VERSION ""

NS_ :

BS_:

BU_: AHLM ASBS CBC DIAGNOST DPDM DTCM ECM EHPS ESC ESL ESM ETM GPF HCP IC IRCM OCM ORC PTS RF_HUB SCCM SGW TBM TCM TPM

BO_ 1099 VehCfgBu5: 8 RF_HUB
 SG_ VC_BU_AmbLtgPrsnt : 61|1@1+ (1,0) [0|0] ""  CBC,SGW
 SG_ VC_BU_AmbTempLct : 6|2@1+ (1,0) [0|0] ""  CBC,SGW
 SG_ VC_BU_ChildDisp_Prsnt : 59|1@1+ (1,0) [0|0] ""  CBC,SGW
 SG_ VC_BU_LUCI_PRSNT : 2|1@1+ (1,0) [0|0] ""  CBC,SGW
 SG_ VC_BU_NonReg_TPIS : 4|1@1+ (1,0) [0|0] ""  CBC,SGW
 SG_ VC_BU_OffRoadPg : 60|1@1+ (1,0) [0|0] ""  CBC,SGW
 SG_ VC_BU_PPPA_Prsnt : 62|1@1+ (1,0) [0|0] ""  CBC,SGW
 SG_ VC_BU_ParkStopPrsnt : 63|1@1+ (1,0) [0|0] ""  CBC,SGW
 SG_ VC_BU_RR_DuallyPrsnt : 3|1@1+ (1,0) [0|0] ""  CBC,SGW
 SG_ VC_BU_RearDoorLocks2DCM : 56|1@1+ (1,0) [0|0] ""  CBC,SGW
 SG_ VC_BU_SBR_Prsnt : 58|1@1+ (1,0) [0|0] ""  CBC,SGW
 SG_ VC_BU_SpdLmt_PRSNT : 57|1@1+ (1,0) [0|0] ""  CBC,SGW
 SG_ VC_BU_Strng_Rt_0 : 8|8@1+ (0.1,0) [0|25.4] ""  CBC,SGW
 SG_ VC_BU_Strng_Rt_pls1 : 16|8@1+ (0.1,0) [0|25.4] ""  CBC,SGW
 SG_ VC_BU_Strng_Rt_pls2 : 24|8@1+ (0.1,0) [0|25.4] ""  CBC,SGW
 SG_ VC_BU_Strng_Rt_pls3 : 32|8@1+ (0.1,0) [0|25.4] ""  CBC,SGW
 SG_ VC_BU_Strng_Rt_pls4 : 40|8@1+ (0.1,0) [0|25.4] ""  CBC,SGW
 SG_ VC_BU_Strng_Rt_pls5 : 48|8@1+ (0.1,0) [0|25.4] ""  CBC,SGW
 SG_ VC_BU_VehCfg5_Stat : 0|2@1+ (1,0) [0|0] ""  CBC,SGW
 SG_ VC_BU_WTS_Prsnt : 5|1@1+ (1,0) [0|0] ""  CBC,SGW

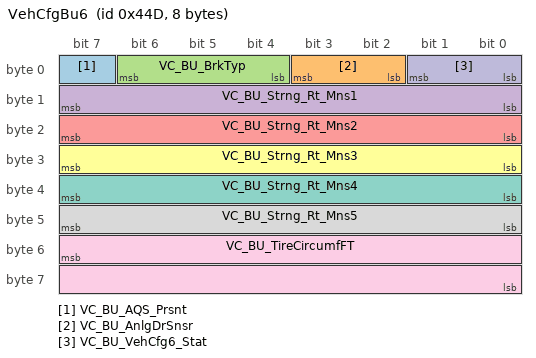
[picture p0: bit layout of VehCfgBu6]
BO_ 1101 VehCfgBu6: 8 RF_HUB
 SG_ VC_BU_AQS_Prsnt : 7|1@1+ (1,0) [0|0] ""  CBC,SGW
 SG_ VC_BU_AnlgDrSnsr : 2|2@1+ (1,0) [0|0] ""  CBC,SGW
 SG_ VC_BU_BrkTyp : 4|3@1+ (1,0) [0|0] ""  CBC,SGW
 SG_ VC_BU_Strng_Rt_Mns1 : 8|8@1+ (0.1,0) [0|25.4] ""  CBC,SGW
 SG_ VC_BU_Strng_Rt_Mns2 : 16|8@1+ (0.1,0) [0|25.4] ""  CBC,SGW
 SG_ VC_BU_Strng_Rt_Mns3 : 24|8@1+ (0.1,0) [0|25.4] ""  CBC,SGW
 SG_ VC_BU_Strng_Rt_Mns4 : 32|8@1+ (0.1,0) [0|25.4] ""  CBC,SGW
 SG_ VC_BU_Strng_Rt_Mns5 : 40|8@1+ (0.1,0) [0|25.4] ""  CBC,SGW
 SG_ VC_BU_TireCircumfFT : 55|16@0+ (1,0) [0|65534] "mm"  CBC,SGW
 SG_ VC_BU_VehCfg6_Stat : 0|2@1+ (1,0) [0|0] ""  CBC,SGW

BO_ 898 VehCfgBu7: 8 RF_HUB
 SG_ VC_BU_ABSM : 25|1@1+ (1,0) [0|0] ""  CBC,SGW
 SG_ VC_BU_ACC_Type : 19|2@1+ (1,0) [0|0] ""  CBC,SGW
 SG_ VC_BU_ADR_PRSNT : 40|1@1+ (1,0) [0|0] ""  CBC,SGW
 SG_ VC_BU_AGSprsnt : 41|1@1+ (1,0) [0|0] ""  CBC,SGW
 SG_ VC_BU_AS_ERS : 14|2@1+ (1,0) [0|0] ""  CBC,SGW
 SG_ VC_BU_AxleLockerPrsnt : 26|2@1+ (1,0) [0|0] ""  CBC,SGW
 SG_ VC_BU_Brake_Type : 56|4@1+ (1,0) [0|0] ""  CBC,SGW
 SG_ VC_BU_DST_Present : 5|1@1+ (1,0) [0|0] ""  CBC,SGW
 SG_ VC_BU_DampingPrsnt : 22|1@1+ (1,0) [0|0] ""  CBC,SGW
 SG_ VC_BU_FullSpeedRange_FCW : 18|1@1+ (1,0) [0|0] ""  CBC,SGW
 SG_ VC_BU_GlareFree_Prsnt : 48|1@1+ (1,0) [0|0] ""  CBC,SGW
 SG_ VC_BU_Glovebox : 44|1@1+ (1,0) [0|0] ""  CBC,SGW
 SG_ VC_BU_HybridType : 36|3@1+ (1,0) [0|0] ""  CBC,SGW
 SG_ VC_BU_LDW : 2|1@1+ (1,0) [0|0] ""  CBC,SGW
 SG_ VC_BU_MOC_Type : 45|2@1+ (1,0) [0|0] ""  CBC,SGW
 SG_ VC_BU_PBTyp : 29|3@1+ (1,0) [0|0] ""  CBC,SGW
 SG_ VC_BU_PTCPrsnt : 43|1@1+ (1,0) [0|0] ""  CBC,SGW
 SG_ VC_BU_PdlsMdPrsnt : 4|1@1+ (1,0) [0|0] ""  CBC,SGW
 SG_ VC_BU_RedKey : 24|1@1+ (1,0) [0|0] ""  CBC,SGW
 SG_ VC_BU_STP_PRSNT : 6|1@1+ (1,0) [0|0] ""  CBC,SGW
 SG_ VC_BU_SUNR_Prsnt : 47|1@1+ (1,0) [0|0] ""  CBC,SGW
 SG_ VC_BU_SVC_Prsnt : 17|1@1+ (1,0) [0|0] ""  CBC,SGW
 SG_ VC_BU_SmartAlternator : 35|1@1+ (1,0) [0|0] ""  CBC,SGW
 SG_ VC_BU_SuspPrsnt : 21|1@1+ (1,0) [0|0] ""  CBC,SGW
 SG_ VC_BU_Suspension_Type : 60|4@1+ (1,0) [0|0] ""  CBC,SGW
 SG_ VC_BU_TPMS_Configuration : 32|3@1+ (1,0) [0|0] ""  CBC,SGW
 SG_ VC_BU_TSBM_Prsnt : 39|1@1+ (1,0) [0|0] ""  CBC,SGW
 SG_ VC_BU_TeenKey : 16|1@1+ (1,0) [0|0] ""  CBC,SGW
 SG_ VC_BU_Temp_Display_Resolution : 42|1@1+ (1,0) [0|0] ""  CBC,SGW
 SG_ VC_BU_TransType : 8|6@1+ (1,0) [0|0] ""  CBC,SGW
 SG_ VC_BU_Trans_Equipped : 28|1@1+ (1,0) [0|0] ""  CBC,SGW
 SG_ VC_BU_Trans_N_Hold_Prsnt : 23|1@1+ (1,0) [0|0] ""  CBC,SGW
 SG_ VC_BU_TrnsDrvMdPrsnt : 3|1@1+ (1,0) [0|0] ""  CBC,SGW
 SG_ VC_BU_VehCfg7_Stat : 0|2@1+ (1,0) [0|0] ""  CBC,SGW
 SG_ VC_BU_eShifter_Prsnt : 7|1@1+ (1,0) [0|0] ""  CBC,SGW

BO_ 907 VehCfgBu8: 8 RF_HUB
 SG_ VC_BU_ARC_PRSNT : 5|1@1+ (1,0) [0|0] ""  CBC,SGW
 SG_ VC_BU_AVAC_PRSNT : 21|1@1+ (1,0) [0|0] ""  CBC,SGW
 SG_ VC_BU_BEAM_SHAPING_PRSNT : 19|1@1+ (1,0) [0|0] ""  CBC,SGW
 SG_ VC_BU_CHILLER_PRSNT : 6|1@1+ (1,0) [0|0] ""  CBC,SGW
 SG_ VC_BU_DBL_PRSNT : 20|1@1+ (1,0) [0|0] ""  CBC,SGW
 SG_ VC_BU_FADPrsnt : 38|1@1+ (1,0) [0|0] ""  CBC,SGW
 SG_ VC_BU_HighOctane_PRSNT : 7|1@1+ (1,0) [0|0] ""  CBC,SGW
 SG_ VC_BU_INDIA_SPEED_WARNING : 41|1@1+ (1,0) [0|0] ""  CBC,SGW
 SG_ VC_BU_Increasing_Speed_Constant : 13|3@1+ (1,0) [0|0] ""  CBC,SGW
 SG_ VC_BU_LineLock_PRSNT : 4|1@1+ (1,0) [0|0] ""  CBC,SGW
 SG_ VC_BU_OFFRoadModePrsnt : 22|1@1+ (1,0) [0|0] ""  CBC,SGW
 SG_ VC_BU_OFFroad_Camera : 23|1@1+ (1,0) [0|0] ""  CBC,SGW
 SG_ VC_BU_OvertakingBan : 16|1@1+ (1,0) [0|0] ""  CBC,SGW
 SG_ VC_BU_PEB_PRSNT : 62|1@1+ (1,0) [0|0] ""  CBC,SGW
 SG_ VC_BU_PPPAHardBtn : 24|1@1+ (1,0) [0|0] ""  CBC,SGW
 SG_ VC_BU_Power_Outlet_Type : 35|2@1+ (1,0) [0|0] ""  CBC,SGW
 SG_ VC_BU_SBL_FBL_CORNERING_PRSNT : 17|2@1+ (1,0) [0|0] ""  CBC,SGW
 SG_ VC_BU_STFA_Prsnt : 53|1@1+ (1,0) [0|0] ""  CBC,SGW
 SG_ VC_BU_Speedometer_Tolerance : 9|4@1+ (1,0) [0|0] ""  CBC,SGW
 SG_ VC_BU_Steering_Cfactor : 2|2@1+ (1,0) [0|0] ""  CBC,SGW
 SG_ VC_BU_TACHO_TYPE : 54|2@1+ (1,0) [0|0] ""  CBC,SGW
 SG_ VC_BU_TIPL_LOT : 39|1@1+ (1,0) [0|0] ""  CBC
 SG_ VC_BU_TLC_PRSNT : 37|1@1+ (1,0) [0|0] ""  CBC,SGW
 SG_ VC_BU_Trans_Brake_PRSNT : 8|1@1+ (1,0) [0|0] ""  CBC,SGW
 SG_ VC_BU_VP_Level : 43|4@1+ (1,0) [0|0] ""  CBC,SGW
 SG_ VC_BU_VehCfg8_Stat : 0|2@1+ (1,0) [0|0] ""  CBC,SGW
 SG_ VC_BU_WHL_BASE_LENGTH : 56|4@1+ (1,0) [0|0] ""  CBC,SGW

BO_ 947 VehCfgCSM1: 8 CBC
 SG_ VC_ACC_DLY_CSO : 24|1@1+ (1,0) [0|0] ""  RF_HUB,SGW
 SG_ VC_AFLS_CSO : 25|1@1+ (1,0) [0|0] ""  RF_HUB,SGW
 SG_ VC_AMB_DMR_CSO : 26|1@1+ (1,0) [0|0] ""  RF_HUB,SGW
 SG_ VC_ASCM_TJ_CSO : 27|1@1+ (1,0) [0|0] ""  RF_HUB,SGW
 SG_ VC_ASCM_WRN_CSO : 28|1@1+ (1,0) [0|0] ""  RF_HUB,SGW
 SG_ VC_AUTO_AERO_CSO : 29|1@1+ (1,0) [0|0] ""  RF_HUB,SGW
 SG_ VC_AUTO_HB_CSO : 30|1@1+ (1,0) [0|0] ""  RF_HUB,SGW
 SG_ VC_AUTO_PRK_CSO : 31|1@1+ (1,0) [0|0] ""  RF_HUB,SGW
 SG_ VC_AUX_SWS_CSO : 18|2@1+ (1,0) [0|0] ""  RF_HUB,SGW
 SG_ VC_BLIND_SPOT_CSO : 32|1@1+ (1,0) [0|0] ""  RF_HUB,SGW
 SG_ VC_CAPACITY_CSO : 33|1@1+ (1,0) [0|0] ""  RF_HUB,SGW
 SG_ VC_CHMSL_LINE_CSO : 15|1@1+ (1,0) [0|0] ""  RF_HUB,SGW
 SG_ VC_CLK_DSP_CSO : 34|1@1+ (1,0) [0|0] ""  RF_HUB,SGW
 SG_ VC_CMP_CAL_CSO : 35|1@1+ (1,0) [0|0] ""  RF_HUB,SGW
 SG_ VC_CMP_VAR_CSO : 36|1@1+ (1,0) [0|0] ""  RF_HUB,SGW
 SG_ VC_CMRA_GRDLNS_CSO : 20|2@1+ (1,0) [0|0] ""  RF_HUB,SGW
 SG_ VC_CONS_CSO : 37|1@1+ (1,0) [0|0] ""  RF_HUB,SGW
 SG_ VC_DCS_CSO : 16|2@1+ (1,0) [0|0] ""  RF_HUB,SGW
 SG_ VC_DISTANCE_CSO : 38|1@1+ (1,0) [0|0] ""  RF_HUB,SGW
 SG_ VC_DRL_CSO : 41|1@1+ (1,0) [0|0] ""  RF_HUB,SGW
 SG_ VC_DR_LK_CSO : 39|1@1+ (1,0) [0|0] ""  RF_HUB,SGW
 SG_ VC_DR_UNLK_CSO : 40|1@1+ (1,0) [0|0] ""  RF_HUB,SGW
 SG_ VC_EASY_EXIT_CSO : 42|1@1+ (1,0) [0|0] ""  RF_HUB,SGW
 SG_ VC_ENTRY_EXIT_CSO : 43|1@1+ (1,0) [0|0] ""  RF_HUB,SGW
 SG_ VC_EPB_SERV_CSO : 44|1@1+ (1,0) [0|0] ""  RF_HUB,SGW
 SG_ VC_EPS_CSO : 7|1@1+ (1,0) [0|0] ""  RF_HUB,SGW
 SG_ VC_FCW_BRK_CSO : 10|1@1+ (1,0) [0|0] ""  RF_HUB,SGW
 SG_ VC_FCW_CSO : 8|2@1+ (1,0) [0|0] ""  RF_HUB,SGW
 SG_ VC_FLSH_LMP_LK_CSO : 45|1@1+ (1,0) [0|0] ""  RF_HUB,SGW
 SG_ VC_HL_DRP_CSO : 46|1@1+ (1,0) [0|0] ""  RF_HUB,SGW
 SG_ VC_HL_OFF_DLY_CSO : 47|1@1+ (1,0) [0|0] ""  RF_HUB,SGW
 SG_ VC_HL_WPR_CSO : 48|1@1+ (1,0) [0|0] ""  RF_HUB,SGW
 SG_ VC_HRN_RMT_LK_CSO : 11|2@1+ (1,0) [0|0] ""  RF_HUB,SGW
 SG_ VC_HRN_RMT_LWR_CSO : 14|1@1+ (1,0) [0|0] ""  RF_HUB,SGW
 SG_ VC_HRN_RMT_ST_CSO : 13|1@1+ (1,0) [0|0] ""  RF_HUB,SGW
 SG_ VC_HSA_CSO : 49|1@1+ (1,0) [0|0] ""  RF_HUB,SGW
 SG_ VC_ILL_APPRCH_CSO : 50|1@1+ (1,0) [0|0] ""  RF_HUB,SGW
 SG_ VC_LDW_TRQ_CSO : 51|1@1+ (1,0) [0|0] ""  RF_HUB,SGW
 SG_ VC_LDW_WRN_CSO : 52|1@1+ (1,0) [0|0] ""  RF_HUB,SGW
 SG_ VC_LGHT_RMT_LWR_CSO : 53|1@1+ (1,0) [0|0] ""  RF_HUB,SGW
 SG_ VC_NAV_TRN_CSO : 54|1@1+ (1,0) [0|0] ""  RF_HUB,SGW
 SG_ VC_PER_SHFT_ENBL_CSO : 56|1@1+ (1,0) [0|0] ""  RF_HUB,SGW
 SG_ VC_PER_SHFT_RPM_CSO : 57|1@1+ (1,0) [0|0] ""  RF_HUB,SGW
 SG_ VC_PE_CSO : 55|1@1+ (1,0) [0|0] ""  RF_HUB,SGW
 SG_ VC_PLG_CHM_CSO : 58|1@1+ (1,0) [0|0] ""  RF_HUB,SGW
 SG_ VC_POLICE_PE_CSO : 23|1@1+ (1,0) [0|0] ""  RF_HUB,SGW
 SG_ VC_POWER_CSO : 59|1@1+ (1,0) [0|0] ""  RF_HUB,SGW
 SG_ VC_PRESSURE_CSO : 60|1@1+ (1,0) [0|0] ""  RF_HUB,SGW
 SG_ VC_PRK_AST_BRK_CSO : 4|1@1+ (1,0) [0|0] ""  RF_HUB,SGW
 SG_ VC_PRK_AST_CSO : 2|2@1+ (1,0) [0|0] ""  RF_HUB,SGW
 SG_ VC_PRK_FT_VOL_CSO : 5|1@1+ (1,0) [0|0] ""  RF_HUB,SGW
 SG_ VC_PRK_RR_VOL_CSO : 6|1@1+ (1,0) [0|0] ""  RF_HUB,SGW
 SG_ VC_PTO_CSO : 61|1@1+ (1,0) [0|0] ""  RF_HUB,SGW
 SG_ VC_RAIN_WPR_CSO : 62|1@1+ (1,0) [0|0] ""  RF_HUB,SGW
 SG_ VC_REAR_CMRA_CSO : 63|1@1+ (1,0) [0|0] ""  RF_HUB,SGW
 SG_ VC_UNIT_SET_CSO : 22|1@1+ (1,0) [0|0] ""  RF_HUB,SGW
 SG_ VC_VehCfgCSO1_Stat : 0|2@1+ (1,0) [0|0] ""  IC,RF_HUB,SGW

BO_ 949 VehCfgCSM1_BU: 8 RF_HUB
 SG_ VC_BU_ACC_DLY_CSO : 24|1@1+ (1,0) [0|0] ""  CBC,SGW
 SG_ VC_BU_AFLS_CSO : 25|1@1+ (1,0) [0|0] ""  CBC,SGW
 SG_ VC_BU_AMB_DMR_CSO : 26|1@1+ (1,0) [0|0] ""  CBC,SGW
 SG_ VC_BU_ASCM_TJ_CSO : 27|1@1+ (1,0) [0|0] ""  CBC,SGW
 SG_ VC_BU_ASCM_WRN_CSO : 28|1@1+ (1,0) [0|0] ""  CBC,SGW
 SG_ VC_BU_AUTO_AERO_CSO : 29|1@1+ (1,0) [0|0] ""  CBC,SGW
 SG_ VC_BU_AUTO_HB_CSO : 30|1@1+ (1,0) [0|0] ""  CBC,SGW
 SG_ VC_BU_AUTO_PRK_CSO : 31|1@1+ (1,0) [0|0] ""  CBC,SGW
 SG_ VC_BU_AUX_SWS_CSO : 18|2@1+ (1,0) [0|0] ""  CBC,SGW
 SG_ VC_BU_BLIND_SPOT_CSO : 32|1@1+ (1,0) [0|0] ""  CBC,SGW
 SG_ VC_BU_CAPACITY_CSO : 33|1@1+ (1,0) [0|0] ""  CBC,SGW
 SG_ VC_BU_CHMSL_LINE_CSO : 15|1@1+ (1,0) [0|0] ""  CBC,SGW
 SG_ VC_BU_CLK_DSP_CSO : 34|1@1+ (1,0) [0|0] ""  CBC,SGW
 SG_ VC_BU_CMP_CAL_CSO : 35|1@1+ (1,0) [0|0] ""  CBC,SGW
 SG_ VC_BU_CMP_VAR_CSO : 36|1@1+ (1,0) [0|0] ""  CBC,SGW
 SG_ VC_BU_CMRA_GRDLNS_CSO : 20|2@1+ (1,0) [0|0] ""  CBC,SGW
 SG_ VC_BU_CONS_CSO : 37|1@1+ (1,0) [0|0] ""  CBC,SGW
 SG_ VC_BU_DCS_CSO : 16|2@1+ (1,0) [0|0] ""  CBC,SGW
 SG_ VC_BU_DISTANCE_CSO : 38|1@1+ (1,0) [0|0] ""  CBC,SGW
 SG_ VC_BU_DRL_CSO : 41|1@1+ (1,0) [0|0] ""  CBC,SGW
 SG_ VC_BU_DR_LK_CSO : 39|1@1+ (1,0) [0|0] ""  CBC,SGW
 SG_ VC_BU_DR_UNLK_CSO : 40|1@1+ (1,0) [0|0] ""  CBC,SGW
 SG_ VC_BU_EASY_EXIT_CSO : 42|1@1+ (1,0) [0|0] ""  CBC,SGW
 SG_ VC_BU_ENTRY_EXIT_CSO : 43|1@1+ (1,0) [0|0] ""  CBC,SGW
 SG_ VC_BU_EPB_SERV_CSO : 44|1@1+ (1,0) [0|0] ""  CBC,SGW
 SG_ VC_BU_EPS_CSO : 7|1@1+ (1,0) [0|0] ""  CBC,SGW
 SG_ VC_BU_FCW_BRK_CSO : 10|1@1+ (1,0) [0|0] ""  CBC,SGW
 SG_ VC_BU_FCW_CSO : 8|2@1+ (1,0) [0|0] ""  CBC,SGW
 SG_ VC_BU_FLSH_LMP_LK_CSO : 45|1@1+ (1,0) [0|0] ""  CBC,SGW
 SG_ VC_BU_HL_DRP_CSO : 46|1@1+ (1,0) [0|0] ""  CBC,SGW
 SG_ VC_BU_HL_OFF_DLY_CSO : 47|1@1+ (1,0) [0|0] ""  CBC,SGW
 SG_ VC_BU_HL_WPR_CSO : 48|1@1+ (1,0) [0|0] ""  CBC,SGW
 SG_ VC_BU_HRN_RMT_LK_CSO : 11|2@1+ (1,0) [0|0] ""  CBC,SGW
 SG_ VC_BU_HRN_RMT_LWR_CSO : 14|1@1+ (1,0) [0|0] ""  CBC,SGW
 SG_ VC_BU_HRN_RMT_ST_CSO : 13|1@1+ (1,0) [0|0] ""  CBC,SGW
 SG_ VC_BU_HSA_CSO : 49|1@1+ (1,0) [0|0] ""  CBC,SGW
 SG_ VC_BU_ILL_APPRCH_CSO : 50|1@1+ (1,0) [0|0] ""  CBC,SGW
 SG_ VC_BU_LDW_TRQ_CSO : 51|1@1+ (1,0) [0|0] ""  CBC,SGW
 SG_ VC_BU_LDW_WRN_CSO : 52|1@1+ (1,0) [0|0] ""  CBC,SGW
 SG_ VC_BU_LGHT_RMT_LWR_CSO : 53|1@1+ (1,0) [0|0] ""  CBC,SGW
 SG_ VC_BU_NAV_TRN_CSO : 54|1@1+ (1,0) [0|0] ""  CBC,SGW
 SG_ VC_BU_PER_SHFT_ENBL_CSO : 56|1@1+ (1,0) [0|0] ""  CBC,SGW
 SG_ VC_BU_PER_SHFT_RPM_CSO : 57|1@1+ (1,0) [0|0] ""  CBC,SGW
 SG_ VC_BU_PE_CSO : 55|1@1+ (1,0) [0|0] ""  CBC,SGW
 SG_ VC_BU_PLG_CHM_CSO : 58|1@1+ (1,0) [0|0] ""  CBC,SGW
 SG_ VC_BU_POLICE_PE_CSO : 23|1@1+ (1,0) [0|0] ""  CBC,SGW
 SG_ VC_BU_POWER_CSO : 59|1@1+ (1,0) [0|0] ""  CBC,SGW
 SG_ VC_BU_PRESSURE_CSO : 60|1@1+ (1,0) [0|0] ""  CBC,SGW
 SG_ VC_BU_PRK_AST_BRK_CSO : 4|1@1+ (1,0) [0|0] ""  CBC,SGW
 SG_ VC_BU_PRK_AST_CSO : 2|2@1+ (1,0) [0|0] ""  CBC,SGW
 SG_ VC_BU_PRK_FT_VOL_CSO : 5|1@1+ (1,0) [0|0] ""  CBC,SGW
 SG_ VC_BU_PRK_RR_VOL_CSO : 6|1@1+ (1,0) [0|0] ""  CBC,SGW
 SG_ VC_BU_PTO_CSO : 61|1@1+ (1,0) [0|0] ""  CBC,SGW
 SG_ VC_BU_RAIN_WPR_CSO : 62|1@1+ (1,0) [0|0] ""  CBC,SGW
 SG_ VC_BU_REAR_CMRA_CSO : 63|1@1+ (1,0) [0|0] ""  CBC,SGW
 SG_ VC_BU_UNIT_SET_CSO : 22|1@1+ (1,0) [0|0] ""  CBC,SGW
 SG_ VC_BU_VehCfgCSO1_Stat : 0|2@1+ (1,0) [0|0] ""  CBC,SGW

CM_ SG_ 1099 VC_BU_AmbLtgPrsnt "Backup for ambient lighting feature is present; True = 1";
CM_ SG_ 1099 VC_BU_AmbTempLct "Backup for ambient temperature sensor location";
CM_ SG_ 1099 VC_BU_ChildDisp_Prsnt "Backup for child display feature is present; True = 1";
CM_ SG_ 1099 VC_BU_LUCI_PRSNT "Backup for Luci feature present; present = [1]";
CM_ SG_ 1099 VC_BU_NonReg_TPIS "Backup for non-regulated tire pressure indicator system; True = 1";
CM_ SG_ 1099 VC_BU_OffRoadPg "Backup for off road pages present; True = [1]";
CM_ SG_ 1099 VC_BU_PPPA_Prsnt "Backup for semi automatic parking system present; True = 1";
CM_ SG_ 1099 VC_BU_ParkStopPrsnt "Backup for park with stop is present; True = 1";
CM_ SG_ 1099 VC_BU_RR_DuallyPrsnt "Backup for vehicle is equipped with rear duals; present = [1]";
CM_ SG_ 1099 VC_BU_RearDoorLocks2DCM "Backup for Rear door lock switch present; present = [1]";
CM_ SG_ 1099 VC_BU_SBR_Prsnt "Backup for seat belt reminder module is present; True = 1";
CM_ SG_ 1099 VC_BU_SpdLmt_PRSNT "Backup for Speed limiter is present; present = [1]";
CM_ SG_ 1099 VC_BU_Strng_Rt_0 "Backup for Steering Ratio at zero";
CM_ SG_ 1099 VC_BU_Strng_Rt_pls1 "Backup for Steering Ratio at positve angle 1";
CM_ SG_ 1099 VC_BU_Strng_Rt_pls2 "Backup for Steering Ratio at positve angle 2";
CM_ SG_ 1099 VC_BU_Strng_Rt_pls3 "Backup for Steering Ratio at positve angle 3";
CM_ SG_ 1099 VC_BU_Strng_Rt_pls4 "Backup for Steering Ratio at positve angle 4";
CM_ SG_ 1099 VC_BU_Strng_Rt_pls5 "Backup for Steering Ratio at positve angle 5";
CM_ SG_ 1099 VC_BU_VehCfg5_Stat "Backup for Configuration messages status 5";
CM_ SG_ 1099 VC_BU_WTS_Prsnt "Backup for wait to start feature is present; present = [1]";
CM_ SG_ 1101 VC_BU_AQS_Prsnt "Backup for air quality sensor present; present = [1]";
CM_ SG_ 1101 VC_BU_AnlgDrSnsr "Analog door sensor configuration backup";
CM_ SG_ 1101 VC_BU_BrkTyp "Backup for brake type configuration (M156/7)";
CM_ SG_ 1101 VC_BU_Strng_Rt_Mns1 "Backup for Steering Ratio at negative angle 1";
CM_ SG_ 1101 VC_BU_Strng_Rt_Mns2 "Backup for Steering Ratio at negative angle 2";
CM_ SG_ 1101 VC_BU_Strng_Rt_Mns3 "Backup for Steering Ratio at negative angle 3";
CM_ SG_ 1101 VC_BU_Strng_Rt_Mns4 "Backup for Steering Ratio at negative angle 4";
CM_ SG_ 1101 VC_BU_Strng_Rt_Mns5 "Backup for Steering Ratio at negative angle 5";
CM_ SG_ 1101 VC_BU_TireCircumfFT "Backup for Dynamic tire circumference - front only";
CM_ SG_ 1101 VC_BU_VehCfg6_Stat "Backup for Configuration messages status 6";
CM_ SG_ 898 VC_BU_ABSM "Backup for Active Blind Spot present; present = [1]";
CM_ SG_ 898 VC_BU_ACC_Type "Backup for type of adaptive cruise control (ACC) system present";
CM_ SG_ 898 VC_BU_ADR_PRSNT "Backup for ADR feature present; True = [1]";
CM_ SG_ 898 VC_BU_AGSprsnt "Backup for AGS present/absent config signal;  Present = 1";
CM_ SG_ 898 VC_BU_AS_ERS "Backup for shift feature autostick / electronic range select status";
CM_ SG_ 898 VC_BU_AxleLockerPrsnt "Backup for axle locker configuration";
CM_ SG_ 898 VC_BU_Brake_Type "Backup for brake type";
CM_ SG_ 898 VC_BU_DST_Present "Backup for dynamic steering torque present; True = [1]";
CM_ SG_ 898 VC_BU_DampingPrsnt "Backup for ASCM contains active damping; present = [1]";
CM_ SG_ 898 VC_BU_FullSpeedRange_FCW "Backup for full speed range forward collision warning plus system present; Present = 1";
CM_ SG_ 898 VC_BU_GlareFree_Prsnt "Glare Free Present";
CM_ SG_ 898 VC_BU_Glovebox "Backup for Glovebox control; Present = 1";
CM_ SG_ 898 VC_BU_HybridType "Backup for identify the kind of hybrid vehicle";
CM_ SG_ 898 VC_BU_LDW "Lane departure warning present; present = [1]";
CM_ SG_ 898 VC_BU_MOC_Type "Backup for motor on caliper type";
CM_ SG_ 898 VC_BU_PBTyp "Backup for park brake type";
CM_ SG_ 898 VC_BU_PTCPrsnt "Backup for PTC present/absent config signal;  Present = 1";
CM_ SG_ 898 VC_BU_PdlsMdPrsnt "Backup for paddles lock-out feature; present = [1]";
CM_ SG_ 898 VC_BU_RedKey "Backup for RedKey feature is present; Present = [1]";
CM_ SG_ 898 VC_BU_STP_PRSNT "Backup for super trac pack present; True = [1]";
CM_ SG_ 898 VC_BU_SUNR_Prsnt "Backup for sunroof is present; True = 1";
CM_ SG_ 898 VC_BU_SVC_Prsnt "Backup for surround view camera; present = [1]";
CM_ SG_ 898 VC_BU_SmartAlternator "Backup for smart alternator is present; True = [1]";
CM_ SG_ 898 VC_BU_SuspPrsnt "backup for ASCM contains suspension; present = [1]";
CM_ SG_ 898 VC_BU_Suspension_Type "Backup for suspension type";
CM_ SG_ 898 VC_BU_TPMS_Configuration "Backup for TPMS configuration";
CM_ SG_ 898 VC_BU_TSBM_Prsnt "Backup for TSBM LIN slave is present; True = [1]";
CM_ SG_ 898 VC_BU_TeenKey "Backup for teenKey feature is present; Present = [1]";
CM_ SG_ 898 VC_BU_Temp_Display_Resolution "Backup for toggle between 0.5degC and 1degC temperature display";
CM_ SG_ 898 VC_BU_TransType "Backup for automatic transmission type";
CM_ SG_ 898 VC_BU_Trans_Equipped "Backup for Transmission equipped: 0 = Automatic & 1 = Manual";
CM_ SG_ 898 VC_BU_Trans_N_Hold_Prsnt "Backup for Transmission neutral hold feature; present = [1]";
CM_ SG_ 898 VC_BU_TrnsDrvMdPrsnt "Backup for transmission drive mode feature; present = [1]";
CM_ SG_ 898 VC_BU_VehCfg7_Stat "Backup for Configuration messages status 7";
CM_ SG_ 898 VC_BU_eShifter_Prsnt "Backup for e-shifter present; present = [1]";
CM_ SG_ 907 VC_BU_ARC_PRSNT "Backup for After Run Cooling (Race Cool Down) feature present; True = [1]";
CM_ SG_ 907 VC_BU_AVAC_PRSNT "Present = 1";
CM_ SG_ 907 VC_BU_BEAM_SHAPING_PRSNT "Present = 1";
CM_ SG_ 907 VC_BU_CHILLER_PRSNT "Backup for Chiller present; True = [1]";
CM_ SG_ 907 VC_BU_DBL_PRSNT "Present = 1";
CM_ SG_ 907 VC_BU_FADPrsnt "Present = 1";
CM_ SG_ 907 VC_BU_HighOctane_PRSNT "Backup for High Octane feature present; True = [1]";
CM_ SG_ 907 VC_BU_INDIA_SPEED_WARNING "Back up for INDIA EQUIPPED SPEED WARNING Feature";
CM_ SG_ 907 VC_BU_Increasing_Speed_Constant "Backup for Increasing Speed Constant (Offset for Speedometer Biasing)";
CM_ SG_ 907 VC_BU_LineLock_PRSNT "Backup for Line Lock feature present; True = [1]";
CM_ SG_ 907 VC_BU_OFFRoadModePrsnt "OFF ROAD MODE Present BackUp Configuration, Present = 1";
CM_ SG_ 907 VC_BU_OFFroad_Camera "OFF Road Camera Present, Present = 1";
CM_ SG_ 907 VC_BU_OvertakingBan "Backup for Overtaking Ban present; present = [1]";
CM_ SG_ 907 VC_BU_PEB_PRSNT "Vehicle config to learn the presence of PEB";
CM_ SG_ 907 VC_BU_PPPAHardBtn "PPPA Hard button present; Present = [1]";
CM_ SG_ 907 VC_BU_Power_Outlet_Type "Bachup signal of VC_Power_Outlet_Type";
CM_ SG_ 907 VC_BU_SBL_FBL_CORNERING_PRSNT "Configuration messages status 8";
CM_ SG_ 907 VC_BU_STFA_Prsnt "Back up for Selectable Tire Fill Alert Present; True = [1]";
CM_ SG_ 907 VC_BU_Speedometer_Tolerance "Backup for Speedometer Tolerance Percentage (Gain for Speedometer Biasing)";
CM_ SG_ 907 VC_BU_Steering_Cfactor "Backup for Steering Cfactor feature";
CM_ SG_ 907 VC_BU_TACHO_TYPE "Backup Vehicle Configuration 8 Packet";
CM_ SG_ 907 VC_BU_TIPL_LOT "Backup for Traffic in Parallel and Lock on Target (1=present)";
CM_ SG_ 907 VC_BU_TLC_PRSNT "Backup for VC_TLC_PRSNT; present = [1]";
CM_ SG_ 907 VC_BU_Trans_Brake_PRSNT "Backup for Transmission Brake feature present; True = [1]";
CM_ SG_ 907 VC_BU_VP_Level "Back up for Radio Type Identifier";
CM_ SG_ 907 VC_BU_VehCfg8_Stat "Backup for Configuration messages status 8";
CM_ SG_ 907 VC_BU_WHL_BASE_LENGTH "Back up Wheel Base Length";
CM_ SG_ 947 VC_ACC_DLY_CSO "Power accessory delay customer settings menu; Present = [1]";
CM_ SG_ 947 VC_AFLS_CSO "Adaptive front light system customer settings menu; Present = [1]";
CM_ SG_ 947 VC_AMB_DMR_CSO "Ambient dimmer customer settings menu; Present = [1]";
CM_ SG_ 947 VC_ASCM_TJ_CSO "Tire jack mode customer settings menu; Present = [1]";
CM_ SG_ 947 VC_ASCM_WRN_CSO "Air suspension warning customer settings menu; Present = [1]";
CM_ SG_ 947 VC_AUTO_AERO_CSO "Automatic aero mode customer settings menu; Present = [1]";
CM_ SG_ 947 VC_AUTO_HB_CSO "Auto high beam customer settings menu; Present = [1]";
CM_ SG_ 947 VC_AUTO_PRK_CSO "Auto park customer settings menu; Present = [1]";
CM_ SG_ 947 VC_AUX_SWS_CSO "Auxiliary switches customer settings menu";
CM_ SG_ 947 VC_BLIND_SPOT_CSO "Blind spot alert customer settings menu; Present = [1]";
CM_ SG_ 947 VC_CAPACITY_CSO "Capacity unit customer settings menu; Present = [1]";
CM_ SG_ 947 VC_CHMSL_LINE_CSO "CHMSL line menu; Present = [1]";
CM_ SG_ 947 VC_CLK_DSP_CSO "Clock display customer settings menu; Present = [1]";
CM_ SG_ 947 VC_CMP_CAL_CSO "Compass calibration customer settings menu; Present = [1]";
CM_ SG_ 947 VC_CMP_VAR_CSO "Compass variance customer settings menu; Present = [1]";
CM_ SG_ 947 VC_CMRA_GRDLNS_CSO "Rear view camera gridlines customer settings menu";
CM_ SG_ 947 VC_CONS_CSO "Consumption unit customer settings menu; Present = [1]";
CM_ SG_ 947 VC_DCS_CSO "Auto on driver comfort customer settings menu";
CM_ SG_ 947 VC_DISTANCE_CSO "Distance unit customer settings menu; Present = [1]";
CM_ SG_ 947 VC_DRL_CSO "Daytime running lights customer settings menu; Present = [1]";
CM_ SG_ 947 VC_DR_LK_CSO "Auto door lock customer settings menu; Present = [1]";
CM_ SG_ 947 VC_DR_UNLK_CSO "Auto door unlock customer settings menu; Present = [1]";
CM_ SG_ 947 VC_EASY_EXIT_CSO "Easy exit seat customer settings menu; Present = [1]";
CM_ SG_ 947 VC_ENTRY_EXIT_CSO "Auto entry exit mode customer settings menu; Present = [1]";
CM_ SG_ 947 VC_EPB_SERV_CSO "EPB service mode customer settings menu; Present = [1]";
CM_ SG_ 947 VC_EPS_CSO "Electric power steering customer settings menu; Present = [1]";
CM_ SG_ 947 VC_FCW_BRK_CSO "Forward collision mitigation braking customer settings menu; Present = [1]";
CM_ SG_ 947 VC_FCW_CSO "Forward collision warning customer settings menu";
CM_ SG_ 947 VC_FLSH_LMP_LK_CSO "Flash lamps with lock customer settings menu; Present = [1]";
CM_ SG_ 947 VC_HL_DRP_CSO "Headlamp drop customer settings menu; Present = [1]";
CM_ SG_ 947 VC_HL_OFF_DLY_CSO "Headlamp off delay customer settings menu; Present = [1]";
CM_ SG_ 947 VC_HL_WPR_CSO "Headlamps on with wiper customer settings menu; Present = [1]";
CM_ SG_ 947 VC_HRN_RMT_LK_CSO "Sound horn with remote lock customer settings menu";
CM_ SG_ 947 VC_HRN_RMT_LWR_CSO "Sound horn with remote lower customer settings menu; Present = [1]";
CM_ SG_ 947 VC_HRN_RMT_ST_CSO "Sound horn with remote start customer settings menu; Present = [1]";
CM_ SG_ 947 VC_HSA_CSO "Hill start assist customer settings menu; Present = [1]";
CM_ SG_ 947 VC_ILL_APPRCH_CSO "Illuminated approach customer settings menu; Present = [1]";
CM_ SG_ 947 VC_LDW_TRQ_CSO "Lane departure torque customer settings menu; Present = [1]";
CM_ SG_ 947 VC_LDW_WRN_CSO "Lane departure warning customer settings menu; Present = [1]";
CM_ SG_ 947 VC_LGHT_RMT_LWR_CSO "Flash lights with remote lower customer settings menu; Present = [1]";
CM_ SG_ 947 VC_NAV_TRN_CSO "Nav turn by turn customer settings menu; Present = [1]";
CM_ SG_ 947 VC_PER_SHFT_ENBL_CSO "Performance shift enable customer settings menu; Present = [1]";
CM_ SG_ 947 VC_PER_SHFT_RPM_CSO "Performance shift rpm customer settings menu; Present = [1]";
CM_ SG_ 947 VC_PE_CSO "Passive entry customer settings menu; Present = [1]";
CM_ SG_ 947 VC_PLG_CHM_CSO "Power liftgate chime customer settings menu; Present = [1]";
CM_ SG_ 947 VC_POLICE_PE_CSO "Police passive entry settings menu; Present = [1]";
CM_ SG_ 947 VC_POWER_CSO "Power unit customer settings menu; Present = [1]";
CM_ SG_ 947 VC_PRESSURE_CSO "Pressure unit customer settings menu; Present = [1]";
CM_ SG_ 947 VC_PRK_AST_BRK_CSO "Park assist brake customer settings menu; Present = [1]";
CM_ SG_ 947 VC_PRK_AST_CSO "Park assist customer settings menu";
CM_ SG_ 947 VC_PRK_FT_VOL_CSO "Park assist front volume customer settings menu; Present = [1]";
CM_ SG_ 947 VC_PRK_RR_VOL_CSO "Park assist rear volume customer settings menu; Present = [1]";
CM_ SG_ 947 VC_PTO_CSO "Power take off customer settings menu; Present = [1]";
CM_ SG_ 947 VC_RAIN_WPR_CSO "Rain sensitive wipers customer settings menu; Present = [1]";
CM_ SG_ 947 VC_REAR_CMRA_CSO "Rear camera customer settings menu; Present = [1]";
CM_ SG_ 947 VC_UNIT_SET_CSO "Unit set customer settings menu; Present = [1]";
CM_ SG_ 947 VC_VehCfgCSO1_Stat "Configuration message CSO1 status";
CM_ SG_ 949 VC_BU_ACC_DLY_CSO "Backup for Power accessory delay customer settings menu";
CM_ SG_ 949 VC_BU_AFLS_CSO "Backup for Adaptive front light system customer settings menu";
CM_ SG_ 949 VC_BU_AMB_DMR_CSO "Backup for Ambient dimmer customer settings menu";
CM_ SG_ 949 VC_BU_ASCM_TJ_CSO "Backup for Tire jack mode customer settings menu";
CM_ SG_ 949 VC_BU_ASCM_WRN_CSO "Backup for Air suspension warning customer settings menu";
CM_ SG_ 949 VC_BU_AUTO_AERO_CSO "Backup for Automatic aero mode customer settings menu";
CM_ SG_ 949 VC_BU_AUTO_HB_CSO "Backup for Auto high beam customer settings menu";
CM_ SG_ 949 VC_BU_AUTO_PRK_CSO "Backup for Auto park customer settings menu";
CM_ SG_ 949 VC_BU_AUX_SWS_CSO "Backup for Auxiliary switches customer settings menu";
CM_ SG_ 949 VC_BU_BLIND_SPOT_CSO "Backup for Blind spot alert customer settings menu";
CM_ SG_ 949 VC_BU_CAPACITY_CSO "Backup for Capacity unit customer settings menu";
CM_ SG_ 949 VC_BU_CHMSL_LINE_CSO "Backup for CHMSL line customer settings menu";
CM_ SG_ 949 VC_BU_CLK_DSP_CSO "Backup for Clock display customer settings menu";
CM_ SG_ 949 VC_BU_CMP_CAL_CSO "Backup for Compass calibration customer settings menu";
CM_ SG_ 949 VC_BU_CMP_VAR_CSO "Backup for Compass variance customer settings menu";
CM_ SG_ 949 VC_BU_CMRA_GRDLNS_CSO "Backup for Rear view camera gridlines customer settings menu";
CM_ SG_ 949 VC_BU_CONS_CSO "Backup for Consumption unit customer settings menu";
CM_ SG_ 949 VC_BU_DCS_CSO "Backup for Auto on driver comfort customer settings menu";
CM_ SG_ 949 VC_BU_DISTANCE_CSO "Backup for Distance unit customer settings menu";
CM_ SG_ 949 VC_BU_DRL_CSO "Backup for Daytime running lights customer settings menu";
CM_ SG_ 949 VC_BU_DR_LK_CSO "Backup for Auto door lock customer settings menu";
CM_ SG_ 949 VC_BU_DR_UNLK_CSO "Backup for Auto door unlock customer settings menu";
CM_ SG_ 949 VC_BU_EASY_EXIT_CSO "Backup for Easy exit seat customer settings menu";
CM_ SG_ 949 VC_BU_ENTRY_EXIT_CSO "Backup for Auto entry exit mode customer settings menu";
CM_ SG_ 949 VC_BU_EPB_SERV_CSO "Backup for EPB service mode customer settings menu";
CM_ SG_ 949 VC_BU_EPS_CSO "Backup for electric power steering customer settings menu";
CM_ SG_ 949 VC_BU_FCW_BRK_CSO "Backup for Forward collision mitigation braking customer settings menu";
CM_ SG_ 949 VC_BU_FCW_CSO "Backup for Forward collision warning customer settings menu";
CM_ SG_ 949 VC_BU_FLSH_LMP_LK_CSO "Backup for Flash lamps with lock customer settings menu";
CM_ SG_ 949 VC_BU_HL_DRP_CSO "Backup for Headlamp drop customer settings menu";
CM_ SG_ 949 VC_BU_HL_OFF_DLY_CSO "Backup for Headlamp off delay customer settings menu";
CM_ SG_ 949 VC_BU_HL_WPR_CSO "Backup for Headlamps on with wiper customer settings menu";
CM_ SG_ 949 VC_BU_HRN_RMT_LK_CSO "Backup for Sound horn with remote lock customer settings menu";
CM_ SG_ 949 VC_BU_HRN_RMT_LWR_CSO "Backup for Sound horn with remote lower customer settings menu";
CM_ SG_ 949 VC_BU_HRN_RMT_ST_CSO "Backup for Sound horn with remote start customer settings menu";
CM_ SG_ 949 VC_BU_HSA_CSO "Backup for Hill start assist customer settings menu";
CM_ SG_ 949 VC_BU_ILL_APPRCH_CSO "Backup for Illuminated approach customer settings menu";
CM_ SG_ 949 VC_BU_LDW_TRQ_CSO "Backup for Lane departure torque customer settings menu";
CM_ SG_ 949 VC_BU_LDW_WRN_CSO "Backup for Lane departure warning customer settings menu";
CM_ SG_ 949 VC_BU_LGHT_RMT_LWR_CSO "Backup for Flash lights with remote lower customer settings menu";
CM_ SG_ 949 VC_BU_NAV_TRN_CSO "Backup for Nav turn by turn customer settings menu";
CM_ SG_ 949 VC_BU_PER_SHFT_ENBL_CSO "Backup for Performance shift enable customer settings menu";
CM_ SG_ 949 VC_BU_PER_SHFT_RPM_CSO "Backup for Performance shift rpm customer settings menu";
CM_ SG_ 949 VC_BU_PE_CSO "Backup for Passive entry customer settings menu";
CM_ SG_ 949 VC_BU_PLG_CHM_CSO "Backup for Power liftgate chime customer settings menu";
CM_ SG_ 949 VC_BU_POLICE_PE_CSO "Backup for police passive entry settings menu; Present = [1]";
CM_ SG_ 949 VC_BU_POWER_CSO "Backup for Power unit customer settings menu";
CM_ SG_ 949 VC_BU_PRESSURE_CSO "Backup for Pressure unit customer settings menu";
CM_ SG_ 949 VC_BU_PRK_AST_BRK_CSO "Backup for park assist brake customer settings menu";
CM_ SG_ 949 VC_BU_PRK_AST_CSO "Backup for park assist customer settings menu";
CM_ SG_ 949 VC_BU_PRK_FT_VOL_CSO "Backup for park assist front volume customer settings menu";
CM_ SG_ 949 VC_BU_PRK_RR_VOL_CSO "Backup for park assist rear volume customer settings menu";
CM_ SG_ 949 VC_BU_PTO_CSO "Backup for Power take off customer settings menu";
CM_ SG_ 949 VC_BU_RAIN_WPR_CSO "Backup for Rain sensitive wipers customer settings menu";
CM_ SG_ 949 VC_BU_REAR_CMRA_CSO "Backup for Rear camera customer settings menu";
CM_ SG_ 949 VC_BU_UNIT_SET_CSO "Backup for unit set customer settings menu; Present = [1]";
CM_ SG_ 949 VC_BU_VehCfgCSO1_Stat "Backup for Configuration message CSO1 status";
BA_DEF_ BO_  "App-Botschaft" ENUM  "nein","ja";
BA_DEF_ BO_  "CanMsgMinLen" INT 0 8;
BA_DEF_ BO_  "DiagRequest" ENUM  "nein","ja";
BA_DEF_ BO_  "DiagResponse" ENUM  "nein","ja";
BA_DEF_ BO_  "DiagState" ENUM  "nein","ja";
BA_DEF_ BO_  "GenMsgCycleTime" INT 0 65535;
BA_DEF_ BO_  "GenMsgCycleTimeActive" INT 0 65535;
BA_DEF_ BO_  "GenMsgDelayTime" INT 0 65535;
BA_DEF_ BO_  "GenMsgNrOfRepetitions" INT 0 65535;
BA_DEF_ BO_  "GenMsgSendType" ENUM  "cyclicX","spontanX","cyclicIfActiveX","spontanWithDelay","cyclicAndSpontanX","cyclicAndSpontanWithDelay","spontanWithRepitition","cyclicIfActiveAndSpontanWD","cyclicIfActiveFast","cyclicWithRepeatOnDemand","none";
BA_DEF_ BO_  "GenMsgStartDelayTime" INT 0 65535;
BA_DEF_ BO_  "GenMsgStartValue" STRING ;
BA_DEF_ BO_  "NWM-Botschaft" ENUM  "nein","ja";
BA_DEF_ BO_  "TpTxIndex" INT 0 99;
BA_DEF_ SG_  "FlexKomComment" STRING ;
BA_DEF_ SG_  "FlexKomIsMotorola" ENUM  "nein","ja";
BA_DEF_ SG_  "FlexKomSID" INT 0 2147483647;
BA_DEF_ SG_  "FlexKomSigLaenge" INT 0 64;
BA_DEF_ SG_  "FlexKomSigName" STRING ;
BA_DEF_ SG_  "FlexKomSigStartPos" INT 0 63;
BA_DEF_ SG_  "FlexKomSigStartValue" STRING ;
BA_DEF_ SG_  "GenSigCycleTime" INT 0 65535;
BA_DEF_ SG_  "GenSigCycleTimeActive" INT 0 65535;
BA_DEF_ SG_  "GenSigSendType" ENUM  "cyclicX","spontanX","cyclicIfActiveX","spontanWithDelay","cyclicAndSpontanX","cyclicAndSpontanWithDelay","spontanWithRepitition","cyclicIfActiveAndSpontanWD","cyclicIfActiveFast","cyclicWithRepeatOnDemand","none";
BA_DEF_ SG_  "GenSigSNA" STRING ;
BA_DEF_ SG_  "GenSigStartValue" HEX 0 2147483648;
BA_DEF_ SG_  "GenSigTimeout_AHLM" INT 0 65535;
BA_DEF_ SG_  "GenSigTimeout_ASBS" INT 0 65535;
BA_DEF_ SG_  "GenSigTimeout_CBC" INT 0 65535;
BA_DEF_ SG_  "GenSigTimeout_DPDM" INT 0 65535;
BA_DEF_ SG_  "GenSigTimeout_DTCM" INT 0 65535;
BA_DEF_ SG_  "GenSigTimeout_EHPS" INT 0 65535;
BA_DEF_ SG_  "GenSigTimeout_ESC" INT 0 65535;
BA_DEF_ SG_  "GenSigTimeout_ESL" INT 0 65535;
BA_DEF_ SG_  "GenSigTimeout_ESM" INT 0 65535;
BA_DEF_ SG_  "GenSigTimeout_ETM" INT 0 65535;
BA_DEF_ SG_  "GenSigTimeout_IC" INT 0 65535;
BA_DEF_ SG_  "GenSigTimeout_OCM" INT 0 65535;
BA_DEF_ SG_  "GenSigTimeout_ORC" INT 0 65535;
BA_DEF_ SG_  "GenSigTimeout_PTS" INT 0 65535;
BA_DEF_ SG_  "GenSigTimeout_RF_HUB" INT 0 65535;
BA_DEF_ SG_  "GenSigTimeout_SCCM" INT 0 65535;
BA_DEF_ SG_  "GenSigTimeout_TBM" INT 0 65535;
BA_DEF_ SG_  "GenSigTimeout_TCM" INT 0 65535;
BA_DEF_ SG_  "GenSigTimeout_TPM" INT 0 65535;
BA_DEF_ SG_  "RID" STRING ;
BA_DEF_ SG_  "SystemSignalLongSymbol" STRING ;
BA_DEF_DEF_  "App-Botschaft" "nein";
BA_DEF_DEF_  "CanMsgMinLen" 0;
BA_DEF_DEF_  "DiagRequest" "nein";
BA_DEF_DEF_  "DiagResponse" "nein";
BA_DEF_DEF_  "DiagState" "nein";
BA_DEF_DEF_  "GenMsgCycleTime" 0;
BA_DEF_DEF_  "GenMsgCycleTimeActive" 0;
BA_DEF_DEF_  "GenMsgDelayTime" 0;
BA_DEF_DEF_  "GenMsgNrOfRepetitions" 0;
BA_DEF_DEF_  "GenMsgSendType" "cyclicX";
BA_DEF_DEF_  "GenMsgStartDelayTime" 0;
BA_DEF_DEF_  "GenMsgStartValue" "";
BA_DEF_DEF_  "NWM-Botschaft" "nein";
BA_DEF_DEF_  "TpTxIndex" 0;
BA_DEF_DEF_  "FlexKomComment" "";
BA_DEF_DEF_  "FlexKomIsMotorola" "nein";
BA_DEF_DEF_  "FlexKomSID" 0;
BA_DEF_DEF_  "FlexKomSigLaenge" 0;
BA_DEF_DEF_  "FlexKomSigName" "";
BA_DEF_DEF_  "FlexKomSigStartPos" 0;
BA_DEF_DEF_  "FlexKomSigStartValue" "";
BA_DEF_DEF_  "GenSigCycleTime" 0;
BA_DEF_DEF_  "GenSigCycleTimeActive" 0;
BA_DEF_DEF_  "GenSigSendType" "cyclicX";
BA_DEF_DEF_  "GenSigSNA" "";
BA_DEF_DEF_  "GenSigStartValue" 0;
BA_DEF_DEF_  "GenSigTimeout_AHLM" 0;
BA_DEF_DEF_  "GenSigTimeout_ASBS" 0;
BA_DEF_DEF_  "GenSigTimeout_CBC" 0;
BA_DEF_DEF_  "GenSigTimeout_DPDM" 0;
BA_DEF_DEF_  "GenSigTimeout_DTCM" 0;
BA_DEF_DEF_  "GenSigTimeout_EHPS" 0;
BA_DEF_DEF_  "GenSigTimeout_ESC" 0;
BA_DEF_DEF_  "GenSigTimeout_ESL" 0;
BA_DEF_DEF_  "GenSigTimeout_ESM" 0;
BA_DEF_DEF_  "GenSigTimeout_ETM" 0;
BA_DEF_DEF_  "GenSigTimeout_IC" 0;
BA_DEF_DEF_  "GenSigTimeout_OCM" 0;
BA_DEF_DEF_  "GenSigTimeout_ORC" 0;
BA_DEF_DEF_  "GenSigTimeout_PTS" 0;
BA_DEF_DEF_  "GenSigTimeout_RF_HUB" 0;
BA_DEF_DEF_  "GenSigTimeout_SCCM" 0;
BA_DEF_DEF_  "GenSigTimeout_TBM" 0;
BA_DEF_DEF_  "GenSigTimeout_TCM" 0;
BA_DEF_DEF_  "GenSigTimeout_TPM" 0;
BA_DEF_DEF_  "RID" "";
BA_DEF_DEF_  "SystemSignalLongSymbol" "";
BA_ "GenMsgStartValue" BO_ 1099 "C3FFFFFFFFFFFF00h";
BA_ "GenMsgSendType" BO_ 1099 1;
BA_ "GenMsgNrOfRepetitions" BO_ 1099 2;
BA_ "GenMsgDelayTime" BO_ 1099 20;
BA_ "GenMsgStartValue" BO_ 1101 "73FFFFFFFFFFFFFFh";
BA_ "GenMsgSendType" BO_ 1101 1;
BA_ "GenMsgNrOfRepetitions" BO_ 1101 2;
BA_ "GenMsgDelayTime" BO_ 1101 20;
BA_ "GenMsgStartValue" BO_ 898 "033F000000000000h";
BA_ "GenMsgSendType" BO_ 898 1;
BA_ "GenMsgNrOfRepetitions" BO_ 898 2;
BA_ "GenMsgDelayTime" BO_ 898 20;
BA_ "GenMsgStartValue" BO_ 907 "0300000000000000h";
BA_ "GenMsgSendType" BO_ 907 1;
BA_ "GenMsgNrOfRepetitions" BO_ 907 2;
BA_ "GenMsgDelayTime" BO_ 907 20;
BA_ "GenMsgStartValue" BO_ 947 "0300000000000000h";
BA_ "GenMsgStartDelayTime" BO_ 947 60;
BA_ "GenMsgSendType" BO_ 947 5;
BA_ "GenMsgNrOfRepetitions" BO_ 947 2;
BA_ "GenMsgDelayTime" BO_ 947 20;
BA_ "GenMsgCycleTime" BO_ 947 2000;
BA_ "GenMsgStartValue" BO_ 949 "0300000000000000h";
BA_ "GenMsgSendType" BO_ 949 1;
BA_ "GenMsgNrOfRepetitions" BO_ 949 2;
BA_ "GenMsgDelayTime" BO_ 949 20;
BA_ "GenSigSNA" SG_ 1099 VC_BU_AmbLtgPrsnt "0h";
BA_ "GenSigSendType" SG_ 1099 VC_BU_AmbLtgPrsnt 1;
BA_ "FlexKomSigStartValue" SG_ 1099 VC_BU_AmbLtgPrsnt "C3FFFFFFFFFFFF00h";
BA_ "FlexKomSigStartPos" SG_ 1099 VC_BU_AmbLtgPrsnt 7;
BA_ "FlexKomSigName" SG_ 1099 VC_BU_AmbLtgPrsnt "VehCfgBU5_Pkt";
BA_ "FlexKomSigLaenge" SG_ 1099 VC_BU_AmbLtgPrsnt 64;
BA_ "FlexKomSID" SG_ 1099 VC_BU_AmbLtgPrsnt 1196;
BA_ "FlexKomIsMotorola" SG_ 1099 VC_BU_AmbLtgPrsnt 1;
BA_ "FlexKomComment" SG_ 1099 VC_BU_AmbLtgPrsnt "Backup for Vehicle Configuration 5 Packet";
BA_ "GenSigStartValue" SG_ 1099 VC_BU_AmbTempLct 3;
BA_ "GenSigSNA" SG_ 1099 VC_BU_AmbTempLct "3h";
BA_ "GenSigSendType" SG_ 1099 VC_BU_AmbTempLct 1;
BA_ "FlexKomSigStartValue" SG_ 1099 VC_BU_AmbTempLct "C3FFFFFFFFFFFF00h";
BA_ "FlexKomSigStartPos" SG_ 1099 VC_BU_AmbTempLct 7;
BA_ "FlexKomSigName" SG_ 1099 VC_BU_AmbTempLct "VehCfgBU5_Pkt";
BA_ "FlexKomSigLaenge" SG_ 1099 VC_BU_AmbTempLct 64;
BA_ "FlexKomSID" SG_ 1099 VC_BU_AmbTempLct 1196;
BA_ "FlexKomIsMotorola" SG_ 1099 VC_BU_AmbTempLct 1;
BA_ "FlexKomComment" SG_ 1099 VC_BU_AmbTempLct "Backup for Vehicle Configuration 5 Packet";
BA_ "GenSigSNA" SG_ 1099 VC_BU_ChildDisp_Prsnt "0h";
BA_ "GenSigSendType" SG_ 1099 VC_BU_ChildDisp_Prsnt 1;
BA_ "FlexKomSigStartValue" SG_ 1099 VC_BU_ChildDisp_Prsnt "C3FFFFFFFFFFFF00h";
BA_ "FlexKomSigStartPos" SG_ 1099 VC_BU_ChildDisp_Prsnt 7;
BA_ "FlexKomSigName" SG_ 1099 VC_BU_ChildDisp_Prsnt "VehCfgBU5_Pkt";
BA_ "FlexKomSigLaenge" SG_ 1099 VC_BU_ChildDisp_Prsnt 64;
BA_ "FlexKomSID" SG_ 1099 VC_BU_ChildDisp_Prsnt 1196;
BA_ "FlexKomIsMotorola" SG_ 1099 VC_BU_ChildDisp_Prsnt 1;
BA_ "FlexKomComment" SG_ 1099 VC_BU_ChildDisp_Prsnt "Backup for Vehicle Configuration 5 Packet";
BA_ "GenSigSNA" SG_ 1099 VC_BU_LUCI_PRSNT "0h";
BA_ "GenSigSendType" SG_ 1099 VC_BU_LUCI_PRSNT 1;
BA_ "FlexKomSigStartValue" SG_ 1099 VC_BU_LUCI_PRSNT "C3FFFFFFFFFFFF00h";
BA_ "FlexKomSigStartPos" SG_ 1099 VC_BU_LUCI_PRSNT 7;
BA_ "FlexKomSigName" SG_ 1099 VC_BU_LUCI_PRSNT "VehCfgBU5_Pkt";
BA_ "FlexKomSigLaenge" SG_ 1099 VC_BU_LUCI_PRSNT 64;
BA_ "FlexKomSID" SG_ 1099 VC_BU_LUCI_PRSNT 1196;
BA_ "FlexKomIsMotorola" SG_ 1099 VC_BU_LUCI_PRSNT 1;
BA_ "FlexKomComment" SG_ 1099 VC_BU_LUCI_PRSNT "Backup for Vehicle Configuration 5 Packet";
BA_ "GenSigSNA" SG_ 1099 VC_BU_NonReg_TPIS "0h";
BA_ "GenSigSendType" SG_ 1099 VC_BU_NonReg_TPIS 1;
BA_ "FlexKomSigStartValue" SG_ 1099 VC_BU_NonReg_TPIS "C3FFFFFFFFFFFF00h";
BA_ "FlexKomSigStartPos" SG_ 1099 VC_BU_NonReg_TPIS 7;
BA_ "FlexKomSigName" SG_ 1099 VC_BU_NonReg_TPIS "VehCfgBU5_Pkt";
BA_ "FlexKomSigLaenge" SG_ 1099 VC_BU_NonReg_TPIS 64;
BA_ "FlexKomSID" SG_ 1099 VC_BU_NonReg_TPIS 1196;
BA_ "FlexKomIsMotorola" SG_ 1099 VC_BU_NonReg_TPIS 1;
BA_ "FlexKomComment" SG_ 1099 VC_BU_NonReg_TPIS "Backup for Vehicle Configuration 5 Packet";
BA_ "GenSigSNA" SG_ 1099 VC_BU_OffRoadPg "0h";
BA_ "GenSigSendType" SG_ 1099 VC_BU_OffRoadPg 1;
BA_ "FlexKomSigStartValue" SG_ 1099 VC_BU_OffRoadPg "C3FFFFFFFFFFFF00h";
BA_ "FlexKomSigStartPos" SG_ 1099 VC_BU_OffRoadPg 7;
BA_ "FlexKomSigName" SG_ 1099 VC_BU_OffRoadPg "VehCfgBU5_Pkt";
BA_ "FlexKomSigLaenge" SG_ 1099 VC_BU_OffRoadPg 64;
BA_ "FlexKomSID" SG_ 1099 VC_BU_OffRoadPg 1196;
BA_ "FlexKomIsMotorola" SG_ 1099 VC_BU_OffRoadPg 1;
BA_ "FlexKomComment" SG_ 1099 VC_BU_OffRoadPg "Backup for Vehicle Configuration 5 Packet";
BA_ "GenSigSNA" SG_ 1099 VC_BU_PPPA_Prsnt "0h";
BA_ "GenSigSendType" SG_ 1099 VC_BU_PPPA_Prsnt 1;
BA_ "FlexKomSigStartValue" SG_ 1099 VC_BU_PPPA_Prsnt "C3FFFFFFFFFFFF00h";
BA_ "FlexKomSigStartPos" SG_ 1099 VC_BU_PPPA_Prsnt 7;
BA_ "FlexKomSigName" SG_ 1099 VC_BU_PPPA_Prsnt "VehCfgBU5_Pkt";
BA_ "FlexKomSigLaenge" SG_ 1099 VC_BU_PPPA_Prsnt 64;
BA_ "FlexKomSID" SG_ 1099 VC_BU_PPPA_Prsnt 1196;
BA_ "FlexKomIsMotorola" SG_ 1099 VC_BU_PPPA_Prsnt 1;
BA_ "FlexKomComment" SG_ 1099 VC_BU_PPPA_Prsnt "Backup for Vehicle Configuration 5 Packet";
BA_ "GenSigSNA" SG_ 1099 VC_BU_ParkStopPrsnt "0h";
BA_ "GenSigSendType" SG_ 1099 VC_BU_ParkStopPrsnt 1;
BA_ "FlexKomSigStartValue" SG_ 1099 VC_BU_ParkStopPrsnt "C3FFFFFFFFFFFF00h";
BA_ "FlexKomSigStartPos" SG_ 1099 VC_BU_ParkStopPrsnt 7;
BA_ "FlexKomSigName" SG_ 1099 VC_BU_ParkStopPrsnt "VehCfgBU5_Pkt";
BA_ "FlexKomSigLaenge" SG_ 1099 VC_BU_ParkStopPrsnt 64;
BA_ "FlexKomSID" SG_ 1099 VC_BU_ParkStopPrsnt 1196;
BA_ "FlexKomIsMotorola" SG_ 1099 VC_BU_ParkStopPrsnt 1;
BA_ "FlexKomComment" SG_ 1099 VC_BU_ParkStopPrsnt "Backup for Vehicle Configuration 5 Packet";
BA_ "GenSigSNA" SG_ 1099 VC_BU_RR_DuallyPrsnt "0h";
BA_ "GenSigSendType" SG_ 1099 VC_BU_RR_DuallyPrsnt 1;
BA_ "FlexKomSigStartValue" SG_ 1099 VC_BU_RR_DuallyPrsnt "C3FFFFFFFFFFFF00h";
BA_ "FlexKomSigStartPos" SG_ 1099 VC_BU_RR_DuallyPrsnt 7;
BA_ "FlexKomSigName" SG_ 1099 VC_BU_RR_DuallyPrsnt "VehCfgBU5_Pkt";
BA_ "FlexKomSigLaenge" SG_ 1099 VC_BU_RR_DuallyPrsnt 64;
BA_ "FlexKomSID" SG_ 1099 VC_BU_RR_DuallyPrsnt 1196;
BA_ "FlexKomIsMotorola" SG_ 1099 VC_BU_RR_DuallyPrsnt 1;
BA_ "FlexKomComment" SG_ 1099 VC_BU_RR_DuallyPrsnt "Backup for Vehicle Configuration 5 Packet";
BA_ "GenSigSNA" SG_ 1099 VC_BU_RearDoorLocks2DCM "0h";
BA_ "GenSigSendType" SG_ 1099 VC_BU_RearDoorLocks2DCM 1;
BA_ "FlexKomSigStartValue" SG_ 1099 VC_BU_RearDoorLocks2DCM "C3FFFFFFFFFFFF00h";
BA_ "FlexKomSigStartPos" SG_ 1099 VC_BU_RearDoorLocks2DCM 7;
BA_ "FlexKomSigName" SG_ 1099 VC_BU_RearDoorLocks2DCM "VehCfgBU5_Pkt";
BA_ "FlexKomSigLaenge" SG_ 1099 VC_BU_RearDoorLocks2DCM 64;
BA_ "FlexKomSID" SG_ 1099 VC_BU_RearDoorLocks2DCM 1196;
BA_ "FlexKomIsMotorola" SG_ 1099 VC_BU_RearDoorLocks2DCM 1;
BA_ "FlexKomComment" SG_ 1099 VC_BU_RearDoorLocks2DCM "Backup for Vehicle Configuration 5 Packet";
BA_ "GenSigSNA" SG_ 1099 VC_BU_SBR_Prsnt "0h";
BA_ "GenSigSendType" SG_ 1099 VC_BU_SBR_Prsnt 1;
BA_ "FlexKomSigStartValue" SG_ 1099 VC_BU_SBR_Prsnt "C3FFFFFFFFFFFF00h";
BA_ "FlexKomSigStartPos" SG_ 1099 VC_BU_SBR_Prsnt 7;
BA_ "FlexKomSigName" SG_ 1099 VC_BU_SBR_Prsnt "VehCfgBU5_Pkt";
BA_ "FlexKomSigLaenge" SG_ 1099 VC_BU_SBR_Prsnt 64;
BA_ "FlexKomSID" SG_ 1099 VC_BU_SBR_Prsnt 1196;
BA_ "FlexKomIsMotorola" SG_ 1099 VC_BU_SBR_Prsnt 1;
BA_ "FlexKomComment" SG_ 1099 VC_BU_SBR_Prsnt "Backup for Vehicle Configuration 5 Packet";
BA_ "GenSigSNA" SG_ 1099 VC_BU_SpdLmt_PRSNT "0h";
BA_ "GenSigSendType" SG_ 1099 VC_BU_SpdLmt_PRSNT 1;
BA_ "FlexKomSigStartValue" SG_ 1099 VC_BU_SpdLmt_PRSNT "C3FFFFFFFFFFFF00h";
BA_ "FlexKomSigStartPos" SG_ 1099 VC_BU_SpdLmt_PRSNT 7;
BA_ "FlexKomSigName" SG_ 1099 VC_BU_SpdLmt_PRSNT "VehCfgBU5_Pkt";
BA_ "FlexKomSigLaenge" SG_ 1099 VC_BU_SpdLmt_PRSNT 64;
BA_ "FlexKomSID" SG_ 1099 VC_BU_SpdLmt_PRSNT 1196;
BA_ "FlexKomIsMotorola" SG_ 1099 VC_BU_SpdLmt_PRSNT 1;
BA_ "FlexKomComment" SG_ 1099 VC_BU_SpdLmt_PRSNT "Backup for Vehicle Configuration 5 Packet";
BA_ "GenSigStartValue" SG_ 1099 VC_BU_Strng_Rt_0 255;
BA_ "GenSigSNA" SG_ 1099 VC_BU_Strng_Rt_0 "FFh";
BA_ "GenSigSendType" SG_ 1099 VC_BU_Strng_Rt_0 1;
BA_ "FlexKomSigStartValue" SG_ 1099 VC_BU_Strng_Rt_0 "C3FFFFFFFFFFFF00h";
BA_ "FlexKomSigStartPos" SG_ 1099 VC_BU_Strng_Rt_0 7;
BA_ "FlexKomSigName" SG_ 1099 VC_BU_Strng_Rt_0 "VehCfgBU5_Pkt";
BA_ "FlexKomSigLaenge" SG_ 1099 VC_BU_Strng_Rt_0 64;
BA_ "FlexKomSID" SG_ 1099 VC_BU_Strng_Rt_0 1196;
BA_ "FlexKomIsMotorola" SG_ 1099 VC_BU_Strng_Rt_0 1;
BA_ "FlexKomComment" SG_ 1099 VC_BU_Strng_Rt_0 "Backup for Vehicle Configuration 5 Packet";
BA_ "GenSigStartValue" SG_ 1099 VC_BU_Strng_Rt_pls1 255;
BA_ "GenSigSNA" SG_ 1099 VC_BU_Strng_Rt_pls1 "FFh";
BA_ "GenSigSendType" SG_ 1099 VC_BU_Strng_Rt_pls1 1;
BA_ "FlexKomSigStartValue" SG_ 1099 VC_BU_Strng_Rt_pls1 "C3FFFFFFFFFFFF00h";
BA_ "FlexKomSigStartPos" SG_ 1099 VC_BU_Strng_Rt_pls1 7;
BA_ "FlexKomSigName" SG_ 1099 VC_BU_Strng_Rt_pls1 "VehCfgBU5_Pkt";
BA_ "FlexKomSigLaenge" SG_ 1099 VC_BU_Strng_Rt_pls1 64;
BA_ "FlexKomSID" SG_ 1099 VC_BU_Strng_Rt_pls1 1196;
BA_ "FlexKomIsMotorola" SG_ 1099 VC_BU_Strng_Rt_pls1 1;
BA_ "FlexKomComment" SG_ 1099 VC_BU_Strng_Rt_pls1 "Backup for Vehicle Configuration 5 Packet";
BA_ "GenSigStartValue" SG_ 1099 VC_BU_Strng_Rt_pls2 255;
BA_ "GenSigSNA" SG_ 1099 VC_BU_Strng_Rt_pls2 "FFh";
BA_ "GenSigSendType" SG_ 1099 VC_BU_Strng_Rt_pls2 1;
BA_ "FlexKomSigStartValue" SG_ 1099 VC_BU_Strng_Rt_pls2 "C3FFFFFFFFFFFF00h";
BA_ "FlexKomSigStartPos" SG_ 1099 VC_BU_Strng_Rt_pls2 7;
BA_ "FlexKomSigName" SG_ 1099 VC_BU_Strng_Rt_pls2 "VehCfgBU5_Pkt";
BA_ "FlexKomSigLaenge" SG_ 1099 VC_BU_Strng_Rt_pls2 64;
BA_ "FlexKomSID" SG_ 1099 VC_BU_Strng_Rt_pls2 1196;
BA_ "FlexKomIsMotorola" SG_ 1099 VC_BU_Strng_Rt_pls2 1;
BA_ "FlexKomComment" SG_ 1099 VC_BU_Strng_Rt_pls2 "Backup for Vehicle Configuration 5 Packet";
BA_ "GenSigStartValue" SG_ 1099 VC_BU_Strng_Rt_pls3 255;
BA_ "GenSigSNA" SG_ 1099 VC_BU_Strng_Rt_pls3 "FFh";
BA_ "GenSigSendType" SG_ 1099 VC_BU_Strng_Rt_pls3 1;
BA_ "FlexKomSigStartValue" SG_ 1099 VC_BU_Strng_Rt_pls3 "C3FFFFFFFFFFFF00h";
BA_ "FlexKomSigStartPos" SG_ 1099 VC_BU_Strng_Rt_pls3 7;
BA_ "FlexKomSigName" SG_ 1099 VC_BU_Strng_Rt_pls3 "VehCfgBU5_Pkt";
BA_ "FlexKomSigLaenge" SG_ 1099 VC_BU_Strng_Rt_pls3 64;
BA_ "FlexKomSID" SG_ 1099 VC_BU_Strng_Rt_pls3 1196;
BA_ "FlexKomIsMotorola" SG_ 1099 VC_BU_Strng_Rt_pls3 1;
BA_ "FlexKomComment" SG_ 1099 VC_BU_Strng_Rt_pls3 "Backup for Vehicle Configuration 5 Packet";
BA_ "GenSigStartValue" SG_ 1099 VC_BU_Strng_Rt_pls4 255;
BA_ "GenSigSNA" SG_ 1099 VC_BU_Strng_Rt_pls4 "FFh";
BA_ "GenSigSendType" SG_ 1099 VC_BU_Strng_Rt_pls4 1;
BA_ "FlexKomSigStartValue" SG_ 1099 VC_BU_Strng_Rt_pls4 "C3FFFFFFFFFFFF00h";
BA_ "FlexKomSigStartPos" SG_ 1099 VC_BU_Strng_Rt_pls4 7;
BA_ "FlexKomSigName" SG_ 1099 VC_BU_Strng_Rt_pls4 "VehCfgBU5_Pkt";
BA_ "FlexKomSigLaenge" SG_ 1099 VC_BU_Strng_Rt_pls4 64;
BA_ "FlexKomSID" SG_ 1099 VC_BU_Strng_Rt_pls4 1196;
BA_ "FlexKomIsMotorola" SG_ 1099 VC_BU_Strng_Rt_pls4 1;
BA_ "FlexKomComment" SG_ 1099 VC_BU_Strng_Rt_pls4 "Backup for Vehicle Configuration 5 Packet";
BA_ "GenSigStartValue" SG_ 1099 VC_BU_Strng_Rt_pls5 255;
BA_ "GenSigSNA" SG_ 1099 VC_BU_Strng_Rt_pls5 "FFh";
BA_ "GenSigSendType" SG_ 1099 VC_BU_Strng_Rt_pls5 1;
BA_ "FlexKomSigStartValue" SG_ 1099 VC_BU_Strng_Rt_pls5 "C3FFFFFFFFFFFF00h";
BA_ "FlexKomSigStartPos" SG_ 1099 VC_BU_Strng_Rt_pls5 7;
BA_ "FlexKomSigName" SG_ 1099 VC_BU_Strng_Rt_pls5 "VehCfgBU5_Pkt";
BA_ "FlexKomSigLaenge" SG_ 1099 VC_BU_Strng_Rt_pls5 64;
BA_ "FlexKomSID" SG_ 1099 VC_BU_Strng_Rt_pls5 1196;
BA_ "FlexKomIsMotorola" SG_ 1099 VC_BU_Strng_Rt_pls5 1;
BA_ "FlexKomComment" SG_ 1099 VC_BU_Strng_Rt_pls5 "Backup for Vehicle Configuration 5 Packet";
BA_ "GenSigStartValue" SG_ 1099 VC_BU_VehCfg5_Stat 3;
BA_ "GenSigSNA" SG_ 1099 VC_BU_VehCfg5_Stat "3h";
BA_ "GenSigSendType" SG_ 1099 VC_BU_VehCfg5_Stat 1;
BA_ "FlexKomSigStartValue" SG_ 1099 VC_BU_VehCfg5_Stat "C3FFFFFFFFFFFF00h";
BA_ "FlexKomSigStartPos" SG_ 1099 VC_BU_VehCfg5_Stat 7;
BA_ "FlexKomSigName" SG_ 1099 VC_BU_VehCfg5_Stat "VehCfgBU5_Pkt";
BA_ "FlexKomSigLaenge" SG_ 1099 VC_BU_VehCfg5_Stat 64;
BA_ "FlexKomSID" SG_ 1099 VC_BU_VehCfg5_Stat 1196;
BA_ "FlexKomIsMotorola" SG_ 1099 VC_BU_VehCfg5_Stat 1;
BA_ "FlexKomComment" SG_ 1099 VC_BU_VehCfg5_Stat "Backup for Vehicle Configuration 5 Packet";
BA_ "GenSigSNA" SG_ 1099 VC_BU_WTS_Prsnt "0h";
BA_ "GenSigSendType" SG_ 1099 VC_BU_WTS_Prsnt 1;
BA_ "FlexKomSigStartValue" SG_ 1099 VC_BU_WTS_Prsnt "C3FFFFFFFFFFFF00h";
BA_ "FlexKomSigStartPos" SG_ 1099 VC_BU_WTS_Prsnt 7;
BA_ "FlexKomSigName" SG_ 1099 VC_BU_WTS_Prsnt "VehCfgBU5_Pkt";
BA_ "FlexKomSigLaenge" SG_ 1099 VC_BU_WTS_Prsnt 64;
BA_ "FlexKomSID" SG_ 1099 VC_BU_WTS_Prsnt 1196;
BA_ "FlexKomIsMotorola" SG_ 1099 VC_BU_WTS_Prsnt 1;
BA_ "FlexKomComment" SG_ 1099 VC_BU_WTS_Prsnt "Backup for Vehicle Configuration 5 Packet";
BA_ "GenSigSNA" SG_ 1101 VC_BU_AQS_Prsnt "0h";
BA_ "GenSigSendType" SG_ 1101 VC_BU_AQS_Prsnt 1;
BA_ "FlexKomSigStartValue" SG_ 1101 VC_BU_AQS_Prsnt "73FFFFFFFFFFFFFFh";
BA_ "FlexKomSigStartPos" SG_ 1101 VC_BU_AQS_Prsnt 7;
BA_ "FlexKomSigName" SG_ 1101 VC_BU_AQS_Prsnt "VehCfgBU6_Pkt";
BA_ "FlexKomSigLaenge" SG_ 1101 VC_BU_AQS_Prsnt 64;
BA_ "FlexKomSID" SG_ 1101 VC_BU_AQS_Prsnt 1197;
BA_ "FlexKomIsMotorola" SG_ 1101 VC_BU_AQS_Prsnt 1;
BA_ "FlexKomComment" SG_ 1101 VC_BU_AQS_Prsnt "Backup for Vehicle Configuration 6 Packet";
BA_ "GenSigSNA" SG_ 1101 VC_BU_AnlgDrSnsr "0h";
BA_ "GenSigSendType" SG_ 1101 VC_BU_AnlgDrSnsr 1;
BA_ "FlexKomSigStartValue" SG_ 1101 VC_BU_AnlgDrSnsr "73FFFFFFFFFFFFFFh";
BA_ "FlexKomSigStartPos" SG_ 1101 VC_BU_AnlgDrSnsr 7;
BA_ "FlexKomSigName" SG_ 1101 VC_BU_AnlgDrSnsr "VehCfgBU6_Pkt";
BA_ "FlexKomSigLaenge" SG_ 1101 VC_BU_AnlgDrSnsr 64;
BA_ "FlexKomSID" SG_ 1101 VC_BU_AnlgDrSnsr 1197;
BA_ "FlexKomIsMotorola" SG_ 1101 VC_BU_AnlgDrSnsr 1;
BA_ "FlexKomComment" SG_ 1101 VC_BU_AnlgDrSnsr "Backup for Vehicle Configuration 6 Packet";
BA_ "GenSigStartValue" SG_ 1101 VC_BU_BrkTyp 7;
BA_ "GenSigSNA" SG_ 1101 VC_BU_BrkTyp "7h";
BA_ "GenSigSendType" SG_ 1101 VC_BU_BrkTyp 1;
BA_ "FlexKomSigStartValue" SG_ 1101 VC_BU_BrkTyp "73FFFFFFFFFFFFFFh";
BA_ "FlexKomSigStartPos" SG_ 1101 VC_BU_BrkTyp 7;
BA_ "FlexKomSigName" SG_ 1101 VC_BU_BrkTyp "VehCfgBU6_Pkt";
BA_ "FlexKomSigLaenge" SG_ 1101 VC_BU_BrkTyp 64;
BA_ "FlexKomSID" SG_ 1101 VC_BU_BrkTyp 1197;
BA_ "FlexKomIsMotorola" SG_ 1101 VC_BU_BrkTyp 1;
BA_ "FlexKomComment" SG_ 1101 VC_BU_BrkTyp "Backup for Vehicle Configuration 6 Packet";
BA_ "GenSigStartValue" SG_ 1101 VC_BU_Strng_Rt_Mns1 255;
BA_ "GenSigSNA" SG_ 1101 VC_BU_Strng_Rt_Mns1 "FFh";
BA_ "GenSigSendType" SG_ 1101 VC_BU_Strng_Rt_Mns1 1;
BA_ "FlexKomSigStartValue" SG_ 1101 VC_BU_Strng_Rt_Mns1 "73FFFFFFFFFFFFFFh";
BA_ "FlexKomSigStartPos" SG_ 1101 VC_BU_Strng_Rt_Mns1 7;
BA_ "FlexKomSigName" SG_ 1101 VC_BU_Strng_Rt_Mns1 "VehCfgBU6_Pkt";
BA_ "FlexKomSigLaenge" SG_ 1101 VC_BU_Strng_Rt_Mns1 64;
BA_ "FlexKomSID" SG_ 1101 VC_BU_Strng_Rt_Mns1 1197;
BA_ "FlexKomIsMotorola" SG_ 1101 VC_BU_Strng_Rt_Mns1 1;
BA_ "FlexKomComment" SG_ 1101 VC_BU_Strng_Rt_Mns1 "Backup for Vehicle Configuration 6 Packet";
BA_ "GenSigStartValue" SG_ 1101 VC_BU_Strng_Rt_Mns2 255;
BA_ "GenSigSNA" SG_ 1101 VC_BU_Strng_Rt_Mns2 "FFh";
BA_ "GenSigSendType" SG_ 1101 VC_BU_Strng_Rt_Mns2 1;
BA_ "FlexKomSigStartValue" SG_ 1101 VC_BU_Strng_Rt_Mns2 "73FFFFFFFFFFFFFFh";
BA_ "FlexKomSigStartPos" SG_ 1101 VC_BU_Strng_Rt_Mns2 7;
BA_ "FlexKomSigName" SG_ 1101 VC_BU_Strng_Rt_Mns2 "VehCfgBU6_Pkt";
BA_ "FlexKomSigLaenge" SG_ 1101 VC_BU_Strng_Rt_Mns2 64;
BA_ "FlexKomSID" SG_ 1101 VC_BU_Strng_Rt_Mns2 1197;
BA_ "FlexKomIsMotorola" SG_ 1101 VC_BU_Strng_Rt_Mns2 1;
BA_ "FlexKomComment" SG_ 1101 VC_BU_Strng_Rt_Mns2 "Backup for Vehicle Configuration 6 Packet";
BA_ "GenSigStartValue" SG_ 1101 VC_BU_Strng_Rt_Mns3 255;
BA_ "GenSigSNA" SG_ 1101 VC_BU_Strng_Rt_Mns3 "FFh";
BA_ "GenSigSendType" SG_ 1101 VC_BU_Strng_Rt_Mns3 1;
BA_ "FlexKomSigStartValue" SG_ 1101 VC_BU_Strng_Rt_Mns3 "73FFFFFFFFFFFFFFh";
BA_ "FlexKomSigStartPos" SG_ 1101 VC_BU_Strng_Rt_Mns3 7;
BA_ "FlexKomSigName" SG_ 1101 VC_BU_Strng_Rt_Mns3 "VehCfgBU6_Pkt";
BA_ "FlexKomSigLaenge" SG_ 1101 VC_BU_Strng_Rt_Mns3 64;
BA_ "FlexKomSID" SG_ 1101 VC_BU_Strng_Rt_Mns3 1197;
BA_ "FlexKomIsMotorola" SG_ 1101 VC_BU_Strng_Rt_Mns3 1;
BA_ "FlexKomComment" SG_ 1101 VC_BU_Strng_Rt_Mns3 "Backup for Vehicle Configuration 6 Packet";
BA_ "GenSigStartValue" SG_ 1101 VC_BU_Strng_Rt_Mns4 255;
BA_ "GenSigSNA" SG_ 1101 VC_BU_Strng_Rt_Mns4 "FFh";
BA_ "GenSigSendType" SG_ 1101 VC_BU_Strng_Rt_Mns4 1;
BA_ "FlexKomSigStartValue" SG_ 1101 VC_BU_Strng_Rt_Mns4 "73FFFFFFFFFFFFFFh";
BA_ "FlexKomSigStartPos" SG_ 1101 VC_BU_Strng_Rt_Mns4 7;
BA_ "FlexKomSigName" SG_ 1101 VC_BU_Strng_Rt_Mns4 "VehCfgBU6_Pkt";
BA_ "FlexKomSigLaenge" SG_ 1101 VC_BU_Strng_Rt_Mns4 64;
BA_ "FlexKomSID" SG_ 1101 VC_BU_Strng_Rt_Mns4 1197;
BA_ "FlexKomIsMotorola" SG_ 1101 VC_BU_Strng_Rt_Mns4 1;
BA_ "FlexKomComment" SG_ 1101 VC_BU_Strng_Rt_Mns4 "Backup for Vehicle Configuration 6 Packet";
BA_ "GenSigStartValue" SG_ 1101 VC_BU_Strng_Rt_Mns5 255;
BA_ "GenSigSNA" SG_ 1101 VC_BU_Strng_Rt_Mns5 "FFh";
BA_ "GenSigSendType" SG_ 1101 VC_BU_Strng_Rt_Mns5 1;
BA_ "FlexKomSigStartValue" SG_ 1101 VC_BU_Strng_Rt_Mns5 "73FFFFFFFFFFFFFFh";
BA_ "FlexKomSigStartPos" SG_ 1101 VC_BU_Strng_Rt_Mns5 7;
BA_ "FlexKomSigName" SG_ 1101 VC_BU_Strng_Rt_Mns5 "VehCfgBU6_Pkt";
BA_ "FlexKomSigLaenge" SG_ 1101 VC_BU_Strng_Rt_Mns5 64;
BA_ "FlexKomSID" SG_ 1101 VC_BU_Strng_Rt_Mns5 1197;
BA_ "FlexKomIsMotorola" SG_ 1101 VC_BU_Strng_Rt_Mns5 1;
BA_ "FlexKomComment" SG_ 1101 VC_BU_Strng_Rt_Mns5 "Backup for Vehicle Configuration 6 Packet";
BA_ "GenSigStartValue" SG_ 1101 VC_BU_TireCircumfFT 65535;
BA_ "GenSigSNA" SG_ 1101 VC_BU_TireCircumfFT "FFFFh";
BA_ "GenSigSendType" SG_ 1101 VC_BU_TireCircumfFT 1;
BA_ "FlexKomSigStartValue" SG_ 1101 VC_BU_TireCircumfFT "73FFFFFFFFFFFFFFh";
BA_ "FlexKomSigStartPos" SG_ 1101 VC_BU_TireCircumfFT 7;
BA_ "FlexKomSigName" SG_ 1101 VC_BU_TireCircumfFT "VehCfgBU6_Pkt";
BA_ "FlexKomSigLaenge" SG_ 1101 VC_BU_TireCircumfFT 64;
BA_ "FlexKomSID" SG_ 1101 VC_BU_TireCircumfFT 1197;
BA_ "FlexKomIsMotorola" SG_ 1101 VC_BU_TireCircumfFT 1;
BA_ "FlexKomComment" SG_ 1101 VC_BU_TireCircumfFT "Backup for Vehicle Configuration 6 Packet";
BA_ "GenSigStartValue" SG_ 1101 VC_BU_VehCfg6_Stat 3;
BA_ "GenSigSNA" SG_ 1101 VC_BU_VehCfg6_Stat "3h";
BA_ "GenSigSendType" SG_ 1101 VC_BU_VehCfg6_Stat 1;
BA_ "FlexKomSigStartValue" SG_ 1101 VC_BU_VehCfg6_Stat "73FFFFFFFFFFFFFFh";
BA_ "FlexKomSigStartPos" SG_ 1101 VC_BU_VehCfg6_Stat 7;
BA_ "FlexKomSigName" SG_ 1101 VC_BU_VehCfg6_Stat "VehCfgBU6_Pkt";
BA_ "FlexKomSigLaenge" SG_ 1101 VC_BU_VehCfg6_Stat 64;
BA_ "FlexKomSID" SG_ 1101 VC_BU_VehCfg6_Stat 1197;
BA_ "FlexKomIsMotorola" SG_ 1101 VC_BU_VehCfg6_Stat 1;
BA_ "FlexKomComment" SG_ 1101 VC_BU_VehCfg6_Stat "Backup for Vehicle Configuration 6 Packet";
BA_ "GenSigSNA" SG_ 898 VC_BU_ABSM "0h";
BA_ "GenSigSendType" SG_ 898 VC_BU_ABSM 1;
BA_ "FlexKomSigStartValue" SG_ 898 VC_BU_ABSM "033F000000000000h";
BA_ "FlexKomSigStartPos" SG_ 898 VC_BU_ABSM 7;
BA_ "FlexKomSigName" SG_ 898 VC_BU_ABSM "VehCfgBU7_Pkt";
BA_ "FlexKomSigLaenge" SG_ 898 VC_BU_ABSM 64;
BA_ "FlexKomSID" SG_ 898 VC_BU_ABSM 2027;
BA_ "FlexKomIsMotorola" SG_ 898 VC_BU_ABSM 1;
BA_ "FlexKomComment" SG_ 898 VC_BU_ABSM "Backup for vehicle configuration 7 packet";
BA_ "GenSigSNA" SG_ 898 VC_BU_ACC_Type "0h";
BA_ "GenSigSendType" SG_ 898 VC_BU_ACC_Type 1;
BA_ "FlexKomSigStartValue" SG_ 898 VC_BU_ACC_Type "033F000000000000h";
BA_ "FlexKomSigStartPos" SG_ 898 VC_BU_ACC_Type 7;
BA_ "FlexKomSigName" SG_ 898 VC_BU_ACC_Type "VehCfgBU7_Pkt";
BA_ "FlexKomSigLaenge" SG_ 898 VC_BU_ACC_Type 64;
BA_ "FlexKomSID" SG_ 898 VC_BU_ACC_Type 2027;
BA_ "FlexKomIsMotorola" SG_ 898 VC_BU_ACC_Type 1;
BA_ "FlexKomComment" SG_ 898 VC_BU_ACC_Type "Backup for vehicle configuration 7 packet";
BA_ "GenSigSNA" SG_ 898 VC_BU_ADR_PRSNT "0h";
BA_ "GenSigSendType" SG_ 898 VC_BU_ADR_PRSNT 1;
BA_ "FlexKomSigStartValue" SG_ 898 VC_BU_ADR_PRSNT "033F000000000000h";
BA_ "FlexKomSigStartPos" SG_ 898 VC_BU_ADR_PRSNT 7;
BA_ "FlexKomSigName" SG_ 898 VC_BU_ADR_PRSNT "VehCfgBU7_Pkt";
BA_ "FlexKomSigLaenge" SG_ 898 VC_BU_ADR_PRSNT 64;
BA_ "FlexKomSID" SG_ 898 VC_BU_ADR_PRSNT 2027;
BA_ "FlexKomIsMotorola" SG_ 898 VC_BU_ADR_PRSNT 1;
BA_ "FlexKomComment" SG_ 898 VC_BU_ADR_PRSNT "Backup for vehicle configuration 7 packet";
BA_ "GenSigSNA" SG_ 898 VC_BU_AGSprsnt "0h";
BA_ "GenSigSendType" SG_ 898 VC_BU_AGSprsnt 1;
BA_ "FlexKomSigStartValue" SG_ 898 VC_BU_AGSprsnt "033F000000000000h";
BA_ "FlexKomSigStartPos" SG_ 898 VC_BU_AGSprsnt 7;
BA_ "FlexKomSigName" SG_ 898 VC_BU_AGSprsnt "VehCfgBU7_Pkt";
BA_ "FlexKomSigLaenge" SG_ 898 VC_BU_AGSprsnt 64;
BA_ "FlexKomSID" SG_ 898 VC_BU_AGSprsnt 2027;
BA_ "FlexKomIsMotorola" SG_ 898 VC_BU_AGSprsnt 1;
BA_ "FlexKomComment" SG_ 898 VC_BU_AGSprsnt "Backup for vehicle configuration 7 packet";
BA_ "GenSigSNA" SG_ 898 VC_BU_AS_ERS "3h";
BA_ "GenSigSendType" SG_ 898 VC_BU_AS_ERS 1;
BA_ "FlexKomSigStartValue" SG_ 898 VC_BU_AS_ERS "033F000000000000h";
BA_ "FlexKomSigStartPos" SG_ 898 VC_BU_AS_ERS 7;
BA_ "FlexKomSigName" SG_ 898 VC_BU_AS_ERS "VehCfgBU7_Pkt";
BA_ "FlexKomSigLaenge" SG_ 898 VC_BU_AS_ERS 64;
BA_ "FlexKomSID" SG_ 898 VC_BU_AS_ERS 2027;
BA_ "FlexKomIsMotorola" SG_ 898 VC_BU_AS_ERS 1;
BA_ "FlexKomComment" SG_ 898 VC_BU_AS_ERS "Backup for vehicle configuration 7 packet";
BA_ "GenSigSNA" SG_ 898 VC_BU_AxleLockerPrsnt "0h";
BA_ "GenSigSendType" SG_ 898 VC_BU_AxleLockerPrsnt 1;
BA_ "FlexKomSigStartValue" SG_ 898 VC_BU_AxleLockerPrsnt "033F000000000000h";
BA_ "FlexKomSigStartPos" SG_ 898 VC_BU_AxleLockerPrsnt 7;
BA_ "FlexKomSigName" SG_ 898 VC_BU_AxleLockerPrsnt "VehCfgBU7_Pkt";
BA_ "FlexKomSigLaenge" SG_ 898 VC_BU_AxleLockerPrsnt 64;
BA_ "FlexKomSID" SG_ 898 VC_BU_AxleLockerPrsnt 2027;
BA_ "FlexKomIsMotorola" SG_ 898 VC_BU_AxleLockerPrsnt 1;
BA_ "FlexKomComment" SG_ 898 VC_BU_AxleLockerPrsnt "Backup for vehicle configuration 7 packet";
BA_ "GenSigSNA" SG_ 898 VC_BU_Brake_Type "0h";
BA_ "GenSigSendType" SG_ 898 VC_BU_Brake_Type 1;
BA_ "FlexKomSigStartValue" SG_ 898 VC_BU_Brake_Type "033F000000000000h";
BA_ "FlexKomSigStartPos" SG_ 898 VC_BU_Brake_Type 7;
BA_ "FlexKomSigName" SG_ 898 VC_BU_Brake_Type "VehCfgBU7_Pkt";
BA_ "FlexKomSigLaenge" SG_ 898 VC_BU_Brake_Type 64;
BA_ "FlexKomSID" SG_ 898 VC_BU_Brake_Type 2027;
BA_ "FlexKomIsMotorola" SG_ 898 VC_BU_Brake_Type 1;
BA_ "FlexKomComment" SG_ 898 VC_BU_Brake_Type "Backup for vehicle configuration 7 packet";
BA_ "GenSigSNA" SG_ 898 VC_BU_DST_Present "0h";
BA_ "GenSigSendType" SG_ 898 VC_BU_DST_Present 1;
BA_ "FlexKomSigStartValue" SG_ 898 VC_BU_DST_Present "033F000000000000h";
BA_ "FlexKomSigStartPos" SG_ 898 VC_BU_DST_Present 7;
BA_ "FlexKomSigName" SG_ 898 VC_BU_DST_Present "VehCfgBU7_Pkt";
BA_ "FlexKomSigLaenge" SG_ 898 VC_BU_DST_Present 64;
BA_ "FlexKomSID" SG_ 898 VC_BU_DST_Present 2027;
BA_ "FlexKomIsMotorola" SG_ 898 VC_BU_DST_Present 1;
BA_ "FlexKomComment" SG_ 898 VC_BU_DST_Present "Backup for vehicle configuration 7 packet";
BA_ "GenSigSNA" SG_ 898 VC_BU_DampingPrsnt "0h";
BA_ "GenSigSendType" SG_ 898 VC_BU_DampingPrsnt 1;
BA_ "FlexKomSigStartValue" SG_ 898 VC_BU_DampingPrsnt "033F000000000000h";
BA_ "FlexKomSigStartPos" SG_ 898 VC_BU_DampingPrsnt 7;
BA_ "FlexKomSigName" SG_ 898 VC_BU_DampingPrsnt "VehCfgBU7_Pkt";
BA_ "FlexKomSigLaenge" SG_ 898 VC_BU_DampingPrsnt 64;
BA_ "FlexKomSID" SG_ 898 VC_BU_DampingPrsnt 2027;
BA_ "FlexKomIsMotorola" SG_ 898 VC_BU_DampingPrsnt 1;
BA_ "FlexKomComment" SG_ 898 VC_BU_DampingPrsnt "Backup for vehicle configuration 7 packet";
BA_ "GenSigSNA" SG_ 898 VC_BU_FullSpeedRange_FCW "0h";
BA_ "GenSigSendType" SG_ 898 VC_BU_FullSpeedRange_FCW 1;
BA_ "FlexKomSigStartValue" SG_ 898 VC_BU_FullSpeedRange_FCW "033F000000000000h";
BA_ "FlexKomSigStartPos" SG_ 898 VC_BU_FullSpeedRange_FCW 7;
BA_ "FlexKomSigName" SG_ 898 VC_BU_FullSpeedRange_FCW "VehCfgBU7_Pkt";
BA_ "FlexKomSigLaenge" SG_ 898 VC_BU_FullSpeedRange_FCW 64;
BA_ "FlexKomSID" SG_ 898 VC_BU_FullSpeedRange_FCW 2027;
BA_ "FlexKomIsMotorola" SG_ 898 VC_BU_FullSpeedRange_FCW 1;
BA_ "FlexKomComment" SG_ 898 VC_BU_FullSpeedRange_FCW "Backup for vehicle configuration 7 packet";
BA_ "GenSigSNA" SG_ 898 VC_BU_GlareFree_Prsnt "0h";
BA_ "GenSigSendType" SG_ 898 VC_BU_GlareFree_Prsnt 1;
BA_ "FlexKomSigStartValue" SG_ 898 VC_BU_GlareFree_Prsnt "033F000000000000h";
BA_ "FlexKomSigStartPos" SG_ 898 VC_BU_GlareFree_Prsnt 7;
BA_ "FlexKomSigName" SG_ 898 VC_BU_GlareFree_Prsnt "VehCfgBU7_Pkt";
BA_ "FlexKomSigLaenge" SG_ 898 VC_BU_GlareFree_Prsnt 64;
BA_ "FlexKomSID" SG_ 898 VC_BU_GlareFree_Prsnt 2027;
BA_ "FlexKomIsMotorola" SG_ 898 VC_BU_GlareFree_Prsnt 1;
BA_ "FlexKomComment" SG_ 898 VC_BU_GlareFree_Prsnt "Backup for vehicle configuration 7 packet";
BA_ "GenSigSNA" SG_ 898 VC_BU_Glovebox "0h";
BA_ "GenSigSendType" SG_ 898 VC_BU_Glovebox 1;
BA_ "FlexKomSigStartValue" SG_ 898 VC_BU_Glovebox "033F000000000000h";
BA_ "FlexKomSigStartPos" SG_ 898 VC_BU_Glovebox 7;
BA_ "FlexKomSigName" SG_ 898 VC_BU_Glovebox "VehCfgBU7_Pkt";
BA_ "FlexKomSigLaenge" SG_ 898 VC_BU_Glovebox 64;
BA_ "FlexKomSID" SG_ 898 VC_BU_Glovebox 2027;
BA_ "FlexKomIsMotorola" SG_ 898 VC_BU_Glovebox 1;
BA_ "FlexKomComment" SG_ 898 VC_BU_Glovebox "Backup for vehicle configuration 7 packet";
BA_ "GenSigSNA" SG_ 898 VC_BU_HybridType "0h";
BA_ "GenSigSendType" SG_ 898 VC_BU_HybridType 1;
BA_ "FlexKomSigStartValue" SG_ 898 VC_BU_HybridType "033F000000000000h";
BA_ "FlexKomSigStartPos" SG_ 898 VC_BU_HybridType 7;
BA_ "FlexKomSigName" SG_ 898 VC_BU_HybridType "VehCfgBU7_Pkt";
BA_ "FlexKomSigLaenge" SG_ 898 VC_BU_HybridType 64;
BA_ "FlexKomSID" SG_ 898 VC_BU_HybridType 2027;
BA_ "FlexKomIsMotorola" SG_ 898 VC_BU_HybridType 1;
BA_ "FlexKomComment" SG_ 898 VC_BU_HybridType "Backup for vehicle configuration 7 packet";
BA_ "GenSigSNA" SG_ 898 VC_BU_LDW "0h";
BA_ "GenSigSendType" SG_ 898 VC_BU_LDW 1;
BA_ "FlexKomSigStartValue" SG_ 898 VC_BU_LDW "033F000000000000h";
BA_ "FlexKomSigStartPos" SG_ 898 VC_BU_LDW 7;
BA_ "FlexKomSigName" SG_ 898 VC_BU_LDW "VehCfgBU7_Pkt";
BA_ "FlexKomSigLaenge" SG_ 898 VC_BU_LDW 64;
BA_ "FlexKomSID" SG_ 898 VC_BU_LDW 2027;
BA_ "FlexKomIsMotorola" SG_ 898 VC_BU_LDW 1;
BA_ "FlexKomComment" SG_ 898 VC_BU_LDW "Backup for vehicle configuration 7 packet";
BA_ "GenSigSNA" SG_ 898 VC_BU_MOC_Type "0h";
BA_ "GenSigSendType" SG_ 898 VC_BU_MOC_Type 1;
BA_ "FlexKomSigStartValue" SG_ 898 VC_BU_MOC_Type "033F000000000000h";
BA_ "FlexKomSigStartPos" SG_ 898 VC_BU_MOC_Type 7;
BA_ "FlexKomSigName" SG_ 898 VC_BU_MOC_Type "VehCfgBU7_Pkt";
BA_ "FlexKomSigLaenge" SG_ 898 VC_BU_MOC_Type 64;
BA_ "FlexKomSID" SG_ 898 VC_BU_MOC_Type 2027;
BA_ "FlexKomIsMotorola" SG_ 898 VC_BU_MOC_Type 1;
BA_ "FlexKomComment" SG_ 898 VC_BU_MOC_Type "Backup for vehicle configuration 7 packet";
BA_ "GenSigSNA" SG_ 898 VC_BU_PBTyp "7h";
BA_ "GenSigSendType" SG_ 898 VC_BU_PBTyp 1;
BA_ "FlexKomSigStartValue" SG_ 898 VC_BU_PBTyp "033F000000000000h";
BA_ "FlexKomSigStartPos" SG_ 898 VC_BU_PBTyp 7;
BA_ "FlexKomSigName" SG_ 898 VC_BU_PBTyp "VehCfgBU7_Pkt";
BA_ "FlexKomSigLaenge" SG_ 898 VC_BU_PBTyp 64;
BA_ "FlexKomSID" SG_ 898 VC_BU_PBTyp 2027;
BA_ "FlexKomIsMotorola" SG_ 898 VC_BU_PBTyp 1;
BA_ "FlexKomComment" SG_ 898 VC_BU_PBTyp "Backup for vehicle configuration 7 packet";
BA_ "GenSigSNA" SG_ 898 VC_BU_PTCPrsnt "0h";
BA_ "GenSigSendType" SG_ 898 VC_BU_PTCPrsnt 1;
BA_ "FlexKomSigStartValue" SG_ 898 VC_BU_PTCPrsnt "033F000000000000h";
BA_ "FlexKomSigStartPos" SG_ 898 VC_BU_PTCPrsnt 7;
BA_ "FlexKomSigName" SG_ 898 VC_BU_PTCPrsnt "VehCfgBU7_Pkt";
BA_ "FlexKomSigLaenge" SG_ 898 VC_BU_PTCPrsnt 64;
BA_ "FlexKomSID" SG_ 898 VC_BU_PTCPrsnt 2027;
BA_ "FlexKomIsMotorola" SG_ 898 VC_BU_PTCPrsnt 1;
BA_ "FlexKomComment" SG_ 898 VC_BU_PTCPrsnt "Backup for vehicle configuration 7 packet";
BA_ "GenSigSNA" SG_ 898 VC_BU_PdlsMdPrsnt "0h";
BA_ "GenSigSendType" SG_ 898 VC_BU_PdlsMdPrsnt 1;
BA_ "FlexKomSigStartValue" SG_ 898 VC_BU_PdlsMdPrsnt "033F000000000000h";
BA_ "FlexKomSigStartPos" SG_ 898 VC_BU_PdlsMdPrsnt 7;
BA_ "FlexKomSigName" SG_ 898 VC_BU_PdlsMdPrsnt "VehCfgBU7_Pkt";
BA_ "FlexKomSigLaenge" SG_ 898 VC_BU_PdlsMdPrsnt 64;
BA_ "FlexKomSID" SG_ 898 VC_BU_PdlsMdPrsnt 2027;
BA_ "FlexKomIsMotorola" SG_ 898 VC_BU_PdlsMdPrsnt 1;
BA_ "FlexKomComment" SG_ 898 VC_BU_PdlsMdPrsnt "Backup for vehicle configuration 7 packet";
BA_ "GenSigSNA" SG_ 898 VC_BU_RedKey "0h";
BA_ "GenSigSendType" SG_ 898 VC_BU_RedKey 1;
BA_ "FlexKomSigStartValue" SG_ 898 VC_BU_RedKey "033F000000000000h";
BA_ "FlexKomSigStartPos" SG_ 898 VC_BU_RedKey 7;
BA_ "FlexKomSigName" SG_ 898 VC_BU_RedKey "VehCfgBU7_Pkt";
BA_ "FlexKomSigLaenge" SG_ 898 VC_BU_RedKey 64;
BA_ "FlexKomSID" SG_ 898 VC_BU_RedKey 2027;
BA_ "FlexKomIsMotorola" SG_ 898 VC_BU_RedKey 1;
BA_ "FlexKomComment" SG_ 898 VC_BU_RedKey "Backup for vehicle configuration 7 packet";
BA_ "GenSigSNA" SG_ 898 VC_BU_STP_PRSNT "0h";
BA_ "GenSigSendType" SG_ 898 VC_BU_STP_PRSNT 1;
BA_ "FlexKomSigStartValue" SG_ 898 VC_BU_STP_PRSNT "033F000000000000h";
BA_ "FlexKomSigStartPos" SG_ 898 VC_BU_STP_PRSNT 7;
BA_ "FlexKomSigName" SG_ 898 VC_BU_STP_PRSNT "VehCfgBU7_Pkt";
BA_ "FlexKomSigLaenge" SG_ 898 VC_BU_STP_PRSNT 64;
BA_ "FlexKomSID" SG_ 898 VC_BU_STP_PRSNT 2027;
BA_ "FlexKomIsMotorola" SG_ 898 VC_BU_STP_PRSNT 1;
BA_ "FlexKomComment" SG_ 898 VC_BU_STP_PRSNT "Backup for vehicle configuration 7 packet";
BA_ "GenSigSNA" SG_ 898 VC_BU_SUNR_Prsnt "0h";
BA_ "GenSigSendType" SG_ 898 VC_BU_SUNR_Prsnt 1;
BA_ "FlexKomSigStartValue" SG_ 898 VC_BU_SUNR_Prsnt "033F000000000000h";
BA_ "FlexKomSigStartPos" SG_ 898 VC_BU_SUNR_Prsnt 7;
BA_ "FlexKomSigName" SG_ 898 VC_BU_SUNR_Prsnt "VehCfgBU7_Pkt";
BA_ "FlexKomSigLaenge" SG_ 898 VC_BU_SUNR_Prsnt 64;
BA_ "FlexKomSID" SG_ 898 VC_BU_SUNR_Prsnt 2027;
BA_ "FlexKomIsMotorola" SG_ 898 VC_BU_SUNR_Prsnt 1;
BA_ "FlexKomComment" SG_ 898 VC_BU_SUNR_Prsnt "Backup for vehicle configuration 7 packet";
BA_ "GenSigSNA" SG_ 898 VC_BU_SVC_Prsnt "0h";
BA_ "GenSigSendType" SG_ 898 VC_BU_SVC_Prsnt 1;
BA_ "FlexKomSigStartValue" SG_ 898 VC_BU_SVC_Prsnt "033F000000000000h";
BA_ "FlexKomSigStartPos" SG_ 898 VC_BU_SVC_Prsnt 7;
BA_ "FlexKomSigName" SG_ 898 VC_BU_SVC_Prsnt "VehCfgBU7_Pkt";
BA_ "FlexKomSigLaenge" SG_ 898 VC_BU_SVC_Prsnt 64;
BA_ "FlexKomSID" SG_ 898 VC_BU_SVC_Prsnt 2027;
BA_ "FlexKomIsMotorola" SG_ 898 VC_BU_SVC_Prsnt 1;
BA_ "FlexKomComment" SG_ 898 VC_BU_SVC_Prsnt "Backup for vehicle configuration 7 packet";
BA_ "GenSigSNA" SG_ 898 VC_BU_SmartAlternator "0h";
BA_ "GenSigSendType" SG_ 898 VC_BU_SmartAlternator 1;
BA_ "FlexKomSigStartValue" SG_ 898 VC_BU_SmartAlternator "033F000000000000h";
BA_ "FlexKomSigStartPos" SG_ 898 VC_BU_SmartAlternator 7;
BA_ "FlexKomSigName" SG_ 898 VC_BU_SmartAlternator "VehCfgBU7_Pkt";
BA_ "FlexKomSigLaenge" SG_ 898 VC_BU_SmartAlternator 64;
BA_ "FlexKomSID" SG_ 898 VC_BU_SmartAlternator 2027;
BA_ "FlexKomIsMotorola" SG_ 898 VC_BU_SmartAlternator 1;
BA_ "FlexKomComment" SG_ 898 VC_BU_SmartAlternator "Backup for vehicle configuration 7 packet";
BA_ "GenSigSNA" SG_ 898 VC_BU_SuspPrsnt "0h";
BA_ "GenSigSendType" SG_ 898 VC_BU_SuspPrsnt 1;
BA_ "FlexKomSigStartValue" SG_ 898 VC_BU_SuspPrsnt "033F000000000000h";
BA_ "FlexKomSigStartPos" SG_ 898 VC_BU_SuspPrsnt 7;
BA_ "FlexKomSigName" SG_ 898 VC_BU_SuspPrsnt "VehCfgBU7_Pkt";
BA_ "FlexKomSigLaenge" SG_ 898 VC_BU_SuspPrsnt 64;
BA_ "FlexKomSID" SG_ 898 VC_BU_SuspPrsnt 2027;
BA_ "FlexKomIsMotorola" SG_ 898 VC_BU_SuspPrsnt 1;
BA_ "FlexKomComment" SG_ 898 VC_BU_SuspPrsnt "Backup for vehicle configuration 7 packet";
BA_ "GenSigSNA" SG_ 898 VC_BU_Suspension_Type "0h";
BA_ "GenSigSendType" SG_ 898 VC_BU_Suspension_Type 1;
BA_ "FlexKomSigStartValue" SG_ 898 VC_BU_Suspension_Type "033F000000000000h";
BA_ "FlexKomSigStartPos" SG_ 898 VC_BU_Suspension_Type 7;
BA_ "FlexKomSigName" SG_ 898 VC_BU_Suspension_Type "VehCfgBU7_Pkt";
BA_ "FlexKomSigLaenge" SG_ 898 VC_BU_Suspension_Type 64;
BA_ "FlexKomSID" SG_ 898 VC_BU_Suspension_Type 2027;
BA_ "FlexKomIsMotorola" SG_ 898 VC_BU_Suspension_Type 1;
BA_ "FlexKomComment" SG_ 898 VC_BU_Suspension_Type "Backup for vehicle configuration 7 packet";
BA_ "GenSigSNA" SG_ 898 VC_BU_TPMS_Configuration "7h";
BA_ "GenSigSendType" SG_ 898 VC_BU_TPMS_Configuration 1;
BA_ "FlexKomSigStartValue" SG_ 898 VC_BU_TPMS_Configuration "033F000000000000h";
BA_ "FlexKomSigStartPos" SG_ 898 VC_BU_TPMS_Configuration 7;
BA_ "FlexKomSigName" SG_ 898 VC_BU_TPMS_Configuration "VehCfgBU7_Pkt";
BA_ "FlexKomSigLaenge" SG_ 898 VC_BU_TPMS_Configuration 64;
BA_ "FlexKomSID" SG_ 898 VC_BU_TPMS_Configuration 2027;
BA_ "FlexKomIsMotorola" SG_ 898 VC_BU_TPMS_Configuration 1;
BA_ "FlexKomComment" SG_ 898 VC_BU_TPMS_Configuration "Backup for vehicle configuration 7 packet";
BA_ "GenSigSNA" SG_ 898 VC_BU_TSBM_Prsnt "0h";
BA_ "GenSigSendType" SG_ 898 VC_BU_TSBM_Prsnt 1;
BA_ "FlexKomSigStartValue" SG_ 898 VC_BU_TSBM_Prsnt "033F000000000000h";
BA_ "FlexKomSigStartPos" SG_ 898 VC_BU_TSBM_Prsnt 7;
BA_ "FlexKomSigName" SG_ 898 VC_BU_TSBM_Prsnt "VehCfgBU7_Pkt";
BA_ "FlexKomSigLaenge" SG_ 898 VC_BU_TSBM_Prsnt 64;
BA_ "FlexKomSID" SG_ 898 VC_BU_TSBM_Prsnt 2027;
BA_ "FlexKomIsMotorola" SG_ 898 VC_BU_TSBM_Prsnt 1;
BA_ "FlexKomComment" SG_ 898 VC_BU_TSBM_Prsnt "Backup for vehicle configuration 7 packet";
BA_ "GenSigSNA" SG_ 898 VC_BU_TeenKey "0h";
BA_ "GenSigSendType" SG_ 898 VC_BU_TeenKey 1;
BA_ "FlexKomSigStartValue" SG_ 898 VC_BU_TeenKey "033F000000000000h";
BA_ "FlexKomSigStartPos" SG_ 898 VC_BU_TeenKey 7;
BA_ "FlexKomSigName" SG_ 898 VC_BU_TeenKey "VehCfgBU7_Pkt";
BA_ "FlexKomSigLaenge" SG_ 898 VC_BU_TeenKey 64;
BA_ "FlexKomSID" SG_ 898 VC_BU_TeenKey 2027;
BA_ "FlexKomIsMotorola" SG_ 898 VC_BU_TeenKey 1;
BA_ "FlexKomComment" SG_ 898 VC_BU_TeenKey "Backup for vehicle configuration 7 packet";
BA_ "GenSigSNA" SG_ 898 VC_BU_Temp_Display_Resolution "0h";
BA_ "GenSigSendType" SG_ 898 VC_BU_Temp_Display_Resolution 1;
BA_ "FlexKomSigStartValue" SG_ 898 VC_BU_Temp_Display_Resolution "033F000000000000h";
BA_ "FlexKomSigStartPos" SG_ 898 VC_BU_Temp_Display_Resolution 7;
BA_ "FlexKomSigName" SG_ 898 VC_BU_Temp_Display_Resolution "VehCfgBU7_Pkt";
BA_ "FlexKomSigLaenge" SG_ 898 VC_BU_Temp_Display_Resolution 64;
BA_ "FlexKomSID" SG_ 898 VC_BU_Temp_Display_Resolution 2027;
BA_ "FlexKomIsMotorola" SG_ 898 VC_BU_Temp_Display_Resolution 1;
BA_ "FlexKomComment" SG_ 898 VC_BU_Temp_Display_Resolution "Backup for vehicle configuration 7 packet";
BA_ "GenSigStartValue" SG_ 898 VC_BU_TransType 63;
BA_ "GenSigSNA" SG_ 898 VC_BU_TransType "3Fh";
BA_ "GenSigSendType" SG_ 898 VC_BU_TransType 1;
BA_ "FlexKomSigStartValue" SG_ 898 VC_BU_TransType "033F000000000000h";
BA_ "FlexKomSigStartPos" SG_ 898 VC_BU_TransType 7;
BA_ "FlexKomSigName" SG_ 898 VC_BU_TransType "VehCfgBU7_Pkt";
BA_ "FlexKomSigLaenge" SG_ 898 VC_BU_TransType 64;
BA_ "FlexKomSID" SG_ 898 VC_BU_TransType 2027;
BA_ "FlexKomIsMotorola" SG_ 898 VC_BU_TransType 1;
BA_ "FlexKomComment" SG_ 898 VC_BU_TransType "Backup for vehicle configuration 7 packet";
BA_ "GenSigSNA" SG_ 898 VC_BU_Trans_Equipped "0h";
BA_ "GenSigSendType" SG_ 898 VC_BU_Trans_Equipped 1;
BA_ "FlexKomSigStartValue" SG_ 898 VC_BU_Trans_Equipped "033F000000000000h";
BA_ "FlexKomSigStartPos" SG_ 898 VC_BU_Trans_Equipped 7;
BA_ "FlexKomSigName" SG_ 898 VC_BU_Trans_Equipped "VehCfgBU7_Pkt";
BA_ "FlexKomSigLaenge" SG_ 898 VC_BU_Trans_Equipped 64;
BA_ "FlexKomSID" SG_ 898 VC_BU_Trans_Equipped 2027;
BA_ "FlexKomIsMotorola" SG_ 898 VC_BU_Trans_Equipped 1;
BA_ "FlexKomComment" SG_ 898 VC_BU_Trans_Equipped "Backup for vehicle configuration 7 packet";
BA_ "GenSigSNA" SG_ 898 VC_BU_Trans_N_Hold_Prsnt "0h";
BA_ "GenSigSendType" SG_ 898 VC_BU_Trans_N_Hold_Prsnt 1;
BA_ "FlexKomSigStartValue" SG_ 898 VC_BU_Trans_N_Hold_Prsnt "033F000000000000h";
BA_ "FlexKomSigStartPos" SG_ 898 VC_BU_Trans_N_Hold_Prsnt 7;
BA_ "FlexKomSigName" SG_ 898 VC_BU_Trans_N_Hold_Prsnt "VehCfgBU7_Pkt";
BA_ "FlexKomSigLaenge" SG_ 898 VC_BU_Trans_N_Hold_Prsnt 64;
BA_ "FlexKomSID" SG_ 898 VC_BU_Trans_N_Hold_Prsnt 2027;
BA_ "FlexKomIsMotorola" SG_ 898 VC_BU_Trans_N_Hold_Prsnt 1;
BA_ "FlexKomComment" SG_ 898 VC_BU_Trans_N_Hold_Prsnt "Backup for vehicle configuration 7 packet";
BA_ "GenSigSNA" SG_ 898 VC_BU_TrnsDrvMdPrsnt "0h";
BA_ "GenSigSendType" SG_ 898 VC_BU_TrnsDrvMdPrsnt 1;
BA_ "FlexKomSigStartValue" SG_ 898 VC_BU_TrnsDrvMdPrsnt "033F000000000000h";
BA_ "FlexKomSigStartPos" SG_ 898 VC_BU_TrnsDrvMdPrsnt 7;
BA_ "FlexKomSigName" SG_ 898 VC_BU_TrnsDrvMdPrsnt "VehCfgBU7_Pkt";
BA_ "FlexKomSigLaenge" SG_ 898 VC_BU_TrnsDrvMdPrsnt 64;
BA_ "FlexKomSID" SG_ 898 VC_BU_TrnsDrvMdPrsnt 2027;
BA_ "FlexKomIsMotorola" SG_ 898 VC_BU_TrnsDrvMdPrsnt 1;
BA_ "FlexKomComment" SG_ 898 VC_BU_TrnsDrvMdPrsnt "Backup for vehicle configuration 7 packet";
BA_ "GenSigStartValue" SG_ 898 VC_BU_VehCfg7_Stat 3;
BA_ "GenSigSNA" SG_ 898 VC_BU_VehCfg7_Stat "3h";
BA_ "GenSigSendType" SG_ 898 VC_BU_VehCfg7_Stat 1;
BA_ "FlexKomSigStartValue" SG_ 898 VC_BU_VehCfg7_Stat "033F000000000000h";
BA_ "FlexKomSigStartPos" SG_ 898 VC_BU_VehCfg7_Stat 7;
BA_ "FlexKomSigName" SG_ 898 VC_BU_VehCfg7_Stat "VehCfgBU7_Pkt";
BA_ "FlexKomSigLaenge" SG_ 898 VC_BU_VehCfg7_Stat 64;
BA_ "FlexKomSID" SG_ 898 VC_BU_VehCfg7_Stat 2027;
BA_ "FlexKomIsMotorola" SG_ 898 VC_BU_VehCfg7_Stat 1;
BA_ "FlexKomComment" SG_ 898 VC_BU_VehCfg7_Stat "Backup for vehicle configuration 7 packet";
BA_ "GenSigSNA" SG_ 898 VC_BU_eShifter_Prsnt "0h";
BA_ "GenSigSendType" SG_ 898 VC_BU_eShifter_Prsnt 1;
BA_ "FlexKomSigStartValue" SG_ 898 VC_BU_eShifter_Prsnt "033F000000000000h";
BA_ "FlexKomSigStartPos" SG_ 898 VC_BU_eShifter_Prsnt 7;
BA_ "FlexKomSigName" SG_ 898 VC_BU_eShifter_Prsnt "VehCfgBU7_Pkt";
BA_ "FlexKomSigLaenge" SG_ 898 VC_BU_eShifter_Prsnt 64;
BA_ "FlexKomSID" SG_ 898 VC_BU_eShifter_Prsnt 2027;
BA_ "FlexKomIsMotorola" SG_ 898 VC_BU_eShifter_Prsnt 1;
BA_ "FlexKomComment" SG_ 898 VC_BU_eShifter_Prsnt "Backup for vehicle configuration 7 packet";
BA_ "GenSigSNA" SG_ 907 VC_BU_ARC_PRSNT "0h";
BA_ "GenSigSendType" SG_ 907 VC_BU_ARC_PRSNT 1;
BA_ "FlexKomSigStartValue" SG_ 907 VC_BU_ARC_PRSNT "0300000000000000h";
BA_ "FlexKomSigStartPos" SG_ 907 VC_BU_ARC_PRSNT 7;
BA_ "FlexKomSigName" SG_ 907 VC_BU_ARC_PRSNT "VehCfgBU8_Pkt";
BA_ "FlexKomSigLaenge" SG_ 907 VC_BU_ARC_PRSNT 64;
BA_ "FlexKomSID" SG_ 907 VC_BU_ARC_PRSNT 2723;
BA_ "FlexKomIsMotorola" SG_ 907 VC_BU_ARC_PRSNT 1;
BA_ "FlexKomComment" SG_ 907 VC_BU_ARC_PRSNT "Backup Vehicle Configuration 8 Packet";
BA_ "GenSigSNA" SG_ 907 VC_BU_AVAC_PRSNT "0h";
BA_ "GenSigSendType" SG_ 907 VC_BU_AVAC_PRSNT 1;
BA_ "FlexKomSigStartValue" SG_ 907 VC_BU_AVAC_PRSNT "0300000000000000h";
BA_ "FlexKomSigStartPos" SG_ 907 VC_BU_AVAC_PRSNT 7;
BA_ "FlexKomSigName" SG_ 907 VC_BU_AVAC_PRSNT "VehCfgBU8_Pkt";
BA_ "FlexKomSigLaenge" SG_ 907 VC_BU_AVAC_PRSNT 64;
BA_ "FlexKomSID" SG_ 907 VC_BU_AVAC_PRSNT 2723;
BA_ "FlexKomIsMotorola" SG_ 907 VC_BU_AVAC_PRSNT 1;
BA_ "FlexKomComment" SG_ 907 VC_BU_AVAC_PRSNT "Backup Vehicle Configuration 8 Packet";
BA_ "GenSigSNA" SG_ 907 VC_BU_BEAM_SHAPING_PRSNT "0h";
BA_ "GenSigSendType" SG_ 907 VC_BU_BEAM_SHAPING_PRSNT 1;
BA_ "FlexKomSigStartValue" SG_ 907 VC_BU_BEAM_SHAPING_PRSNT "0300000000000000h";
BA_ "FlexKomSigStartPos" SG_ 907 VC_BU_BEAM_SHAPING_PRSNT 7;
BA_ "FlexKomSigName" SG_ 907 VC_BU_BEAM_SHAPING_PRSNT "VehCfgBU8_Pkt";
BA_ "FlexKomSigLaenge" SG_ 907 VC_BU_BEAM_SHAPING_PRSNT 64;
BA_ "FlexKomSID" SG_ 907 VC_BU_BEAM_SHAPING_PRSNT 2723;
BA_ "FlexKomIsMotorola" SG_ 907 VC_BU_BEAM_SHAPING_PRSNT 1;
BA_ "FlexKomComment" SG_ 907 VC_BU_BEAM_SHAPING_PRSNT "Backup Vehicle Configuration 8 Packet";
BA_ "GenSigSNA" SG_ 907 VC_BU_CHILLER_PRSNT "0h";
BA_ "GenSigSendType" SG_ 907 VC_BU_CHILLER_PRSNT 1;
BA_ "FlexKomSigStartValue" SG_ 907 VC_BU_CHILLER_PRSNT "0300000000000000h";
BA_ "FlexKomSigStartPos" SG_ 907 VC_BU_CHILLER_PRSNT 7;
BA_ "FlexKomSigName" SG_ 907 VC_BU_CHILLER_PRSNT "VehCfgBU8_Pkt";
BA_ "FlexKomSigLaenge" SG_ 907 VC_BU_CHILLER_PRSNT 64;
BA_ "FlexKomSID" SG_ 907 VC_BU_CHILLER_PRSNT 2723;
BA_ "FlexKomIsMotorola" SG_ 907 VC_BU_CHILLER_PRSNT 1;
BA_ "FlexKomComment" SG_ 907 VC_BU_CHILLER_PRSNT "Backup Vehicle Configuration 8 Packet";
BA_ "GenSigSNA" SG_ 907 VC_BU_DBL_PRSNT "0h";
BA_ "GenSigSendType" SG_ 907 VC_BU_DBL_PRSNT 1;
BA_ "FlexKomSigStartValue" SG_ 907 VC_BU_DBL_PRSNT "0300000000000000h";
BA_ "FlexKomSigStartPos" SG_ 907 VC_BU_DBL_PRSNT 7;
BA_ "FlexKomSigName" SG_ 907 VC_BU_DBL_PRSNT "VehCfgBU8_Pkt";
BA_ "FlexKomSigLaenge" SG_ 907 VC_BU_DBL_PRSNT 64;
BA_ "FlexKomSID" SG_ 907 VC_BU_DBL_PRSNT 2723;
BA_ "FlexKomIsMotorola" SG_ 907 VC_BU_DBL_PRSNT 1;
BA_ "FlexKomComment" SG_ 907 VC_BU_DBL_PRSNT "Backup Vehicle Configuration 8 Packet";
BA_ "GenSigSNA" SG_ 907 VC_BU_FADPrsnt "0h";
BA_ "GenSigSendType" SG_ 907 VC_BU_FADPrsnt 1;
BA_ "FlexKomSigStartValue" SG_ 907 VC_BU_FADPrsnt "0300000000000000h";
BA_ "FlexKomSigStartPos" SG_ 907 VC_BU_FADPrsnt 7;
BA_ "FlexKomSigName" SG_ 907 VC_BU_FADPrsnt "VehCfgBU8_Pkt";
BA_ "FlexKomSigLaenge" SG_ 907 VC_BU_FADPrsnt 64;
BA_ "FlexKomSID" SG_ 907 VC_BU_FADPrsnt 2723;
BA_ "FlexKomIsMotorola" SG_ 907 VC_BU_FADPrsnt 1;
BA_ "FlexKomComment" SG_ 907 VC_BU_FADPrsnt "Backup Vehicle Configuration 8 Packet";
BA_ "GenSigSNA" SG_ 907 VC_BU_HighOctane_PRSNT "0h";
BA_ "GenSigSendType" SG_ 907 VC_BU_HighOctane_PRSNT 1;
BA_ "FlexKomSigStartValue" SG_ 907 VC_BU_HighOctane_PRSNT "0300000000000000h";
BA_ "FlexKomSigStartPos" SG_ 907 VC_BU_HighOctane_PRSNT 7;
BA_ "FlexKomSigName" SG_ 907 VC_BU_HighOctane_PRSNT "VehCfgBU8_Pkt";
BA_ "FlexKomSigLaenge" SG_ 907 VC_BU_HighOctane_PRSNT 64;
BA_ "FlexKomSID" SG_ 907 VC_BU_HighOctane_PRSNT 2723;
BA_ "FlexKomIsMotorola" SG_ 907 VC_BU_HighOctane_PRSNT 1;
BA_ "FlexKomComment" SG_ 907 VC_BU_HighOctane_PRSNT "Backup Vehicle Configuration 8 Packet";
BA_ "GenSigSNA" SG_ 907 VC_BU_INDIA_SPEED_WARNING "0h";
BA_ "GenSigSendType" SG_ 907 VC_BU_INDIA_SPEED_WARNING 1;
BA_ "FlexKomSigStartValue" SG_ 907 VC_BU_INDIA_SPEED_WARNING "0300000000000000h";
BA_ "FlexKomSigStartPos" SG_ 907 VC_BU_INDIA_SPEED_WARNING 7;
BA_ "FlexKomSigName" SG_ 907 VC_BU_INDIA_SPEED_WARNING "VehCfgBU8_Pkt";
BA_ "FlexKomSigLaenge" SG_ 907 VC_BU_INDIA_SPEED_WARNING 64;
BA_ "FlexKomSID" SG_ 907 VC_BU_INDIA_SPEED_WARNING 2723;
BA_ "FlexKomIsMotorola" SG_ 907 VC_BU_INDIA_SPEED_WARNING 1;
BA_ "FlexKomComment" SG_ 907 VC_BU_INDIA_SPEED_WARNING "Backup Vehicle Configuration 8 Packet";
BA_ "GenSigTimeout_CBC" SG_ 907 VC_BU_Increasing_Speed_Constant 10500;
BA_ "GenSigSNA" SG_ 907 VC_BU_Increasing_Speed_Constant "0h";
BA_ "GenSigSendType" SG_ 907 VC_BU_Increasing_Speed_Constant 1;
BA_ "FlexKomSigStartValue" SG_ 907 VC_BU_Increasing_Speed_Constant "0300000000000000h";
BA_ "FlexKomSigStartPos" SG_ 907 VC_BU_Increasing_Speed_Constant 7;
BA_ "FlexKomSigName" SG_ 907 VC_BU_Increasing_Speed_Constant "VehCfgBU8_Pkt";
BA_ "FlexKomSigLaenge" SG_ 907 VC_BU_Increasing_Speed_Constant 64;
BA_ "FlexKomSID" SG_ 907 VC_BU_Increasing_Speed_Constant 2723;
BA_ "FlexKomIsMotorola" SG_ 907 VC_BU_Increasing_Speed_Constant 1;
BA_ "FlexKomComment" SG_ 907 VC_BU_Increasing_Speed_Constant "Backup Vehicle Configuration 8 Packet";
BA_ "GenSigSNA" SG_ 907 VC_BU_LineLock_PRSNT "0h";
BA_ "GenSigSendType" SG_ 907 VC_BU_LineLock_PRSNT 1;
BA_ "FlexKomSigStartValue" SG_ 907 VC_BU_LineLock_PRSNT "0300000000000000h";
BA_ "FlexKomSigStartPos" SG_ 907 VC_BU_LineLock_PRSNT 7;
BA_ "FlexKomSigName" SG_ 907 VC_BU_LineLock_PRSNT "VehCfgBU8_Pkt";
BA_ "FlexKomSigLaenge" SG_ 907 VC_BU_LineLock_PRSNT 64;
BA_ "FlexKomSID" SG_ 907 VC_BU_LineLock_PRSNT 2723;
BA_ "FlexKomIsMotorola" SG_ 907 VC_BU_LineLock_PRSNT 1;
BA_ "FlexKomComment" SG_ 907 VC_BU_LineLock_PRSNT "Backup Vehicle Configuration 8 Packet";
BA_ "GenSigSNA" SG_ 907 VC_BU_OFFRoadModePrsnt "0h";
BA_ "GenSigSendType" SG_ 907 VC_BU_OFFRoadModePrsnt 1;
BA_ "FlexKomSigStartValue" SG_ 907 VC_BU_OFFRoadModePrsnt "0300000000000000h";
BA_ "FlexKomSigStartPos" SG_ 907 VC_BU_OFFRoadModePrsnt 7;
BA_ "FlexKomSigName" SG_ 907 VC_BU_OFFRoadModePrsnt "VehCfgBU8_Pkt";
BA_ "FlexKomSigLaenge" SG_ 907 VC_BU_OFFRoadModePrsnt 64;
BA_ "FlexKomSID" SG_ 907 VC_BU_OFFRoadModePrsnt 2723;
BA_ "FlexKomIsMotorola" SG_ 907 VC_BU_OFFRoadModePrsnt 1;
BA_ "FlexKomComment" SG_ 907 VC_BU_OFFRoadModePrsnt "Backup Vehicle Configuration 8 Packet";
BA_ "GenSigSNA" SG_ 907 VC_BU_OFFroad_Camera "0h";
BA_ "GenSigSendType" SG_ 907 VC_BU_OFFroad_Camera 1;
BA_ "FlexKomSigStartValue" SG_ 907 VC_BU_OFFroad_Camera "0300000000000000h";
BA_ "FlexKomSigStartPos" SG_ 907 VC_BU_OFFroad_Camera 7;
BA_ "FlexKomSigName" SG_ 907 VC_BU_OFFroad_Camera "VehCfgBU8_Pkt";
BA_ "FlexKomSigLaenge" SG_ 907 VC_BU_OFFroad_Camera 64;
BA_ "FlexKomSID" SG_ 907 VC_BU_OFFroad_Camera 2723;
BA_ "FlexKomIsMotorola" SG_ 907 VC_BU_OFFroad_Camera 1;
BA_ "FlexKomComment" SG_ 907 VC_BU_OFFroad_Camera "Backup Vehicle Configuration 8 Packet";
BA_ "GenSigSNA" SG_ 907 VC_BU_OvertakingBan "0h";
BA_ "GenSigSendType" SG_ 907 VC_BU_OvertakingBan 1;
BA_ "FlexKomSigStartValue" SG_ 907 VC_BU_OvertakingBan "0300000000000000h";
BA_ "FlexKomSigStartPos" SG_ 907 VC_BU_OvertakingBan 7;
BA_ "FlexKomSigName" SG_ 907 VC_BU_OvertakingBan "VehCfgBU8_Pkt";
BA_ "FlexKomSigLaenge" SG_ 907 VC_BU_OvertakingBan 64;
BA_ "FlexKomSID" SG_ 907 VC_BU_OvertakingBan 2723;
BA_ "FlexKomIsMotorola" SG_ 907 VC_BU_OvertakingBan 1;
BA_ "FlexKomComment" SG_ 907 VC_BU_OvertakingBan "Backup Vehicle Configuration 8 Packet";
BA_ "GenSigSNA" SG_ 907 VC_BU_PEB_PRSNT "0h";
BA_ "GenSigSendType" SG_ 907 VC_BU_PEB_PRSNT 1;
BA_ "FlexKomSigStartValue" SG_ 907 VC_BU_PEB_PRSNT "0300000000000000h";
BA_ "FlexKomSigStartPos" SG_ 907 VC_BU_PEB_PRSNT 7;
BA_ "FlexKomSigName" SG_ 907 VC_BU_PEB_PRSNT "VehCfgBU8_Pkt";
BA_ "FlexKomSigLaenge" SG_ 907 VC_BU_PEB_PRSNT 64;
BA_ "FlexKomSID" SG_ 907 VC_BU_PEB_PRSNT 2723;
BA_ "FlexKomIsMotorola" SG_ 907 VC_BU_PEB_PRSNT 1;
BA_ "FlexKomComment" SG_ 907 VC_BU_PEB_PRSNT "Backup Vehicle Configuration 8 Packet";
BA_ "GenSigSNA" SG_ 907 VC_BU_PPPAHardBtn "0h";
BA_ "GenSigSendType" SG_ 907 VC_BU_PPPAHardBtn 1;
BA_ "FlexKomSigStartValue" SG_ 907 VC_BU_PPPAHardBtn "0300000000000000h";
BA_ "FlexKomSigStartPos" SG_ 907 VC_BU_PPPAHardBtn 7;
BA_ "FlexKomSigName" SG_ 907 VC_BU_PPPAHardBtn "VehCfgBU8_Pkt";
BA_ "FlexKomSigLaenge" SG_ 907 VC_BU_PPPAHardBtn 64;
BA_ "FlexKomSID" SG_ 907 VC_BU_PPPAHardBtn 2723;
BA_ "FlexKomIsMotorola" SG_ 907 VC_BU_PPPAHardBtn 1;
BA_ "FlexKomComment" SG_ 907 VC_BU_PPPAHardBtn "Backup Vehicle Configuration 8 Packet";
BA_ "GenSigSNA" SG_ 907 VC_BU_Power_Outlet_Type "0h";
BA_ "GenSigSendType" SG_ 907 VC_BU_Power_Outlet_Type 1;
BA_ "FlexKomSigStartValue" SG_ 907 VC_BU_Power_Outlet_Type "0300000000000000h";
BA_ "FlexKomSigStartPos" SG_ 907 VC_BU_Power_Outlet_Type 7;
BA_ "FlexKomSigName" SG_ 907 VC_BU_Power_Outlet_Type "VehCfgBU8_Pkt";
BA_ "FlexKomSigLaenge" SG_ 907 VC_BU_Power_Outlet_Type 64;
BA_ "FlexKomSID" SG_ 907 VC_BU_Power_Outlet_Type 2723;
BA_ "FlexKomIsMotorola" SG_ 907 VC_BU_Power_Outlet_Type 1;
BA_ "FlexKomComment" SG_ 907 VC_BU_Power_Outlet_Type "Backup Vehicle Configuration 8 Packet";
BA_ "GenSigSNA" SG_ 907 VC_BU_SBL_FBL_CORNERING_PRSNT "0h";
BA_ "GenSigSendType" SG_ 907 VC_BU_SBL_FBL_CORNERING_PRSNT 1;
BA_ "FlexKomSigStartValue" SG_ 907 VC_BU_SBL_FBL_CORNERING_PRSNT "0300000000000000h";
BA_ "FlexKomSigStartPos" SG_ 907 VC_BU_SBL_FBL_CORNERING_PRSNT 7;
BA_ "FlexKomSigName" SG_ 907 VC_BU_SBL_FBL_CORNERING_PRSNT "VehCfgBU8_Pkt";
BA_ "FlexKomSigLaenge" SG_ 907 VC_BU_SBL_FBL_CORNERING_PRSNT 64;
BA_ "FlexKomSID" SG_ 907 VC_BU_SBL_FBL_CORNERING_PRSNT 2723;
BA_ "FlexKomIsMotorola" SG_ 907 VC_BU_SBL_FBL_CORNERING_PRSNT 1;
BA_ "FlexKomComment" SG_ 907 VC_BU_SBL_FBL_CORNERING_PRSNT "Backup Vehicle Configuration 8 Packet";
BA_ "GenSigSNA" SG_ 907 VC_BU_STFA_Prsnt "0h";
BA_ "GenSigSendType" SG_ 907 VC_BU_STFA_Prsnt 1;
BA_ "FlexKomSigStartValue" SG_ 907 VC_BU_STFA_Prsnt "0300000000000000h";
BA_ "FlexKomSigStartPos" SG_ 907 VC_BU_STFA_Prsnt 7;
BA_ "FlexKomSigName" SG_ 907 VC_BU_STFA_Prsnt "VehCfgBU8_Pkt";
BA_ "FlexKomSigLaenge" SG_ 907 VC_BU_STFA_Prsnt 64;
BA_ "FlexKomSID" SG_ 907 VC_BU_STFA_Prsnt 2723;
BA_ "FlexKomIsMotorola" SG_ 907 VC_BU_STFA_Prsnt 1;
BA_ "FlexKomComment" SG_ 907 VC_BU_STFA_Prsnt "Backup Vehicle Configuration 8 Packet";
BA_ "GenSigTimeout_CBC" SG_ 907 VC_BU_Speedometer_Tolerance 10500;
BA_ "GenSigSNA" SG_ 907 VC_BU_Speedometer_Tolerance "0h";
BA_ "GenSigSendType" SG_ 907 VC_BU_Speedometer_Tolerance 1;
BA_ "FlexKomSigStartValue" SG_ 907 VC_BU_Speedometer_Tolerance "0300000000000000h";
BA_ "FlexKomSigStartPos" SG_ 907 VC_BU_Speedometer_Tolerance 7;
BA_ "FlexKomSigName" SG_ 907 VC_BU_Speedometer_Tolerance "VehCfgBU8_Pkt";
BA_ "FlexKomSigLaenge" SG_ 907 VC_BU_Speedometer_Tolerance 64;
BA_ "FlexKomSID" SG_ 907 VC_BU_Speedometer_Tolerance 2723;
BA_ "FlexKomIsMotorola" SG_ 907 VC_BU_Speedometer_Tolerance 1;
BA_ "FlexKomComment" SG_ 907 VC_BU_Speedometer_Tolerance "Backup Vehicle Configuration 8 Packet";
BA_ "GenSigSNA" SG_ 907 VC_BU_Steering_Cfactor "0h";
BA_ "GenSigSendType" SG_ 907 VC_BU_Steering_Cfactor 1;
BA_ "FlexKomSigStartValue" SG_ 907 VC_BU_Steering_Cfactor "0300000000000000h";
BA_ "FlexKomSigStartPos" SG_ 907 VC_BU_Steering_Cfactor 7;
BA_ "FlexKomSigName" SG_ 907 VC_BU_Steering_Cfactor "VehCfgBU8_Pkt";
BA_ "FlexKomSigLaenge" SG_ 907 VC_BU_Steering_Cfactor 64;
BA_ "FlexKomSID" SG_ 907 VC_BU_Steering_Cfactor 2723;
BA_ "FlexKomIsMotorola" SG_ 907 VC_BU_Steering_Cfactor 1;
BA_ "FlexKomComment" SG_ 907 VC_BU_Steering_Cfactor "Backup Vehicle Configuration 8 Packet";
BA_ "GenSigSNA" SG_ 907 VC_BU_TACHO_TYPE "0h";
BA_ "GenSigSendType" SG_ 907 VC_BU_TACHO_TYPE 1;
BA_ "FlexKomSigStartValue" SG_ 907 VC_BU_TACHO_TYPE "0300000000000000h";
BA_ "FlexKomSigStartPos" SG_ 907 VC_BU_TACHO_TYPE 7;
BA_ "FlexKomSigName" SG_ 907 VC_BU_TACHO_TYPE "VehCfgBU8_Pkt";
BA_ "FlexKomSigLaenge" SG_ 907 VC_BU_TACHO_TYPE 64;
BA_ "FlexKomSID" SG_ 907 VC_BU_TACHO_TYPE 2723;
BA_ "FlexKomIsMotorola" SG_ 907 VC_BU_TACHO_TYPE 1;
BA_ "FlexKomComment" SG_ 907 VC_BU_TACHO_TYPE "Backup Vehicle Configuration 8 Packet";
BA_ "GenSigSNA" SG_ 907 VC_BU_TIPL_LOT "0h";
BA_ "GenSigSendType" SG_ 907 VC_BU_TIPL_LOT 1;
BA_ "FlexKomSigStartValue" SG_ 907 VC_BU_TIPL_LOT "0300000000000000h";
BA_ "FlexKomSigStartPos" SG_ 907 VC_BU_TIPL_LOT 7;
BA_ "FlexKomSigName" SG_ 907 VC_BU_TIPL_LOT "VehCfgBU8_Pkt";
BA_ "FlexKomSigLaenge" SG_ 907 VC_BU_TIPL_LOT 64;
BA_ "FlexKomSID" SG_ 907 VC_BU_TIPL_LOT 2723;
BA_ "FlexKomIsMotorola" SG_ 907 VC_BU_TIPL_LOT 1;
BA_ "FlexKomComment" SG_ 907 VC_BU_TIPL_LOT "Backup Vehicle Configuration 8 Packet";
BA_ "GenSigSNA" SG_ 907 VC_BU_TLC_PRSNT "0h";
BA_ "GenSigSendType" SG_ 907 VC_BU_TLC_PRSNT 1;
BA_ "FlexKomSigStartValue" SG_ 907 VC_BU_TLC_PRSNT "0300000000000000h";
BA_ "FlexKomSigStartPos" SG_ 907 VC_BU_TLC_PRSNT 7;
BA_ "FlexKomSigName" SG_ 907 VC_BU_TLC_PRSNT "VehCfgBU8_Pkt";
BA_ "FlexKomSigLaenge" SG_ 907 VC_BU_TLC_PRSNT 64;
BA_ "FlexKomSID" SG_ 907 VC_BU_TLC_PRSNT 2723;
BA_ "FlexKomIsMotorola" SG_ 907 VC_BU_TLC_PRSNT 1;
BA_ "FlexKomComment" SG_ 907 VC_BU_TLC_PRSNT "Backup Vehicle Configuration 8 Packet";
BA_ "GenSigSNA" SG_ 907 VC_BU_Trans_Brake_PRSNT "0h";
BA_ "GenSigSendType" SG_ 907 VC_BU_Trans_Brake_PRSNT 1;
BA_ "FlexKomSigStartValue" SG_ 907 VC_BU_Trans_Brake_PRSNT "0300000000000000h";
BA_ "FlexKomSigStartPos" SG_ 907 VC_BU_Trans_Brake_PRSNT 7;
BA_ "FlexKomSigName" SG_ 907 VC_BU_Trans_Brake_PRSNT "VehCfgBU8_Pkt";
BA_ "FlexKomSigLaenge" SG_ 907 VC_BU_Trans_Brake_PRSNT 64;
BA_ "FlexKomSID" SG_ 907 VC_BU_Trans_Brake_PRSNT 2723;
BA_ "FlexKomIsMotorola" SG_ 907 VC_BU_Trans_Brake_PRSNT 1;
BA_ "FlexKomComment" SG_ 907 VC_BU_Trans_Brake_PRSNT "Backup Vehicle Configuration 8 Packet";
BA_ "GenSigSendType" SG_ 907 VC_BU_VP_Level 1;
BA_ "FlexKomSigStartValue" SG_ 907 VC_BU_VP_Level "0300000000000000h";
BA_ "FlexKomSigStartPos" SG_ 907 VC_BU_VP_Level 7;
BA_ "FlexKomSigName" SG_ 907 VC_BU_VP_Level "VehCfgBU8_Pkt";
BA_ "FlexKomSigLaenge" SG_ 907 VC_BU_VP_Level 64;
BA_ "FlexKomSID" SG_ 907 VC_BU_VP_Level 2723;
BA_ "FlexKomIsMotorola" SG_ 907 VC_BU_VP_Level 1;
BA_ "FlexKomComment" SG_ 907 VC_BU_VP_Level "Backup Vehicle Configuration 8 Packet";
BA_ "GenSigStartValue" SG_ 907 VC_BU_VehCfg8_Stat 3;
BA_ "GenSigSNA" SG_ 907 VC_BU_VehCfg8_Stat "3h";
BA_ "GenSigSendType" SG_ 907 VC_BU_VehCfg8_Stat 1;
BA_ "FlexKomSigStartValue" SG_ 907 VC_BU_VehCfg8_Stat "0300000000000000h";
BA_ "FlexKomSigStartPos" SG_ 907 VC_BU_VehCfg8_Stat 7;
BA_ "FlexKomSigName" SG_ 907 VC_BU_VehCfg8_Stat "VehCfgBU8_Pkt";
BA_ "FlexKomSigLaenge" SG_ 907 VC_BU_VehCfg8_Stat 64;
BA_ "FlexKomSID" SG_ 907 VC_BU_VehCfg8_Stat 2723;
BA_ "FlexKomIsMotorola" SG_ 907 VC_BU_VehCfg8_Stat 1;
BA_ "FlexKomComment" SG_ 907 VC_BU_VehCfg8_Stat "Backup Vehicle Configuration 8 Packet";
BA_ "GenSigSendType" SG_ 907 VC_BU_WHL_BASE_LENGTH 1;
BA_ "FlexKomSigStartValue" SG_ 907 VC_BU_WHL_BASE_LENGTH "0300000000000000h";
BA_ "FlexKomSigStartPos" SG_ 907 VC_BU_WHL_BASE_LENGTH 7;
BA_ "FlexKomSigName" SG_ 907 VC_BU_WHL_BASE_LENGTH "VehCfgBU8_Pkt";
BA_ "FlexKomSigLaenge" SG_ 907 VC_BU_WHL_BASE_LENGTH 64;
BA_ "FlexKomSID" SG_ 907 VC_BU_WHL_BASE_LENGTH 2723;
BA_ "FlexKomIsMotorola" SG_ 907 VC_BU_WHL_BASE_LENGTH 1;
BA_ "FlexKomComment" SG_ 907 VC_BU_WHL_BASE_LENGTH "Backup Vehicle Configuration 8 Packet";
BA_ "GenSigTimeout_IC" SG_ 947 VC_ACC_DLY_CSO 21000;
BA_ "GenSigSNA" SG_ 947 VC_ACC_DLY_CSO "0h";
BA_ "GenSigSendType" SG_ 947 VC_ACC_DLY_CSO 5;
BA_ "GenSigCycleTime" SG_ 947 VC_ACC_DLY_CSO 2000;
BA_ "FlexKomSigStartValue" SG_ 947 VC_ACC_DLY_CSO "0300000000000000h";
BA_ "FlexKomSigStartPos" SG_ 947 VC_ACC_DLY_CSO 7;
BA_ "FlexKomSigName" SG_ 947 VC_ACC_DLY_CSO "VehCfgCSM1_Pkt";
BA_ "FlexKomSigLaenge" SG_ 947 VC_ACC_DLY_CSO 64;
BA_ "FlexKomSID" SG_ 947 VC_ACC_DLY_CSO 2006;
BA_ "FlexKomIsMotorola" SG_ 947 VC_ACC_DLY_CSO 1;
BA_ "FlexKomComment" SG_ 947 VC_ACC_DLY_CSO "Vehicle configuration - customer settings menu 1 P";
BA_ "GenSigTimeout_IC" SG_ 947 VC_AFLS_CSO 21000;
BA_ "GenSigSNA" SG_ 947 VC_AFLS_CSO "0h";
BA_ "GenSigSendType" SG_ 947 VC_AFLS_CSO 5;
BA_ "GenSigCycleTime" SG_ 947 VC_AFLS_CSO 2000;
BA_ "FlexKomSigStartValue" SG_ 947 VC_AFLS_CSO "0300000000000000h";
BA_ "FlexKomSigStartPos" SG_ 947 VC_AFLS_CSO 7;
BA_ "FlexKomSigName" SG_ 947 VC_AFLS_CSO "VehCfgCSM1_Pkt";
BA_ "FlexKomSigLaenge" SG_ 947 VC_AFLS_CSO 64;
BA_ "FlexKomSID" SG_ 947 VC_AFLS_CSO 2006;
BA_ "FlexKomIsMotorola" SG_ 947 VC_AFLS_CSO 1;
BA_ "FlexKomComment" SG_ 947 VC_AFLS_CSO "Vehicle configuration - customer settings menu 1 P";
BA_ "GenSigTimeout_IC" SG_ 947 VC_AMB_DMR_CSO 21000;
BA_ "GenSigSNA" SG_ 947 VC_AMB_DMR_CSO "0h";
BA_ "GenSigSendType" SG_ 947 VC_AMB_DMR_CSO 5;
BA_ "GenSigCycleTime" SG_ 947 VC_AMB_DMR_CSO 2000;
BA_ "FlexKomSigStartValue" SG_ 947 VC_AMB_DMR_CSO "0300000000000000h";
BA_ "FlexKomSigStartPos" SG_ 947 VC_AMB_DMR_CSO 7;
BA_ "FlexKomSigName" SG_ 947 VC_AMB_DMR_CSO "VehCfgCSM1_Pkt";
BA_ "FlexKomSigLaenge" SG_ 947 VC_AMB_DMR_CSO 64;
BA_ "FlexKomSID" SG_ 947 VC_AMB_DMR_CSO 2006;
BA_ "FlexKomIsMotorola" SG_ 947 VC_AMB_DMR_CSO 1;
BA_ "FlexKomComment" SG_ 947 VC_AMB_DMR_CSO "Vehicle configuration - customer settings menu 1 P";
BA_ "GenSigTimeout_IC" SG_ 947 VC_ASCM_TJ_CSO 21000;
BA_ "GenSigSNA" SG_ 947 VC_ASCM_TJ_CSO "0h";
BA_ "GenSigSendType" SG_ 947 VC_ASCM_TJ_CSO 5;
BA_ "GenSigCycleTime" SG_ 947 VC_ASCM_TJ_CSO 2000;
BA_ "FlexKomSigStartValue" SG_ 947 VC_ASCM_TJ_CSO "0300000000000000h";
BA_ "FlexKomSigStartPos" SG_ 947 VC_ASCM_TJ_CSO 7;
BA_ "FlexKomSigName" SG_ 947 VC_ASCM_TJ_CSO "VehCfgCSM1_Pkt";
BA_ "FlexKomSigLaenge" SG_ 947 VC_ASCM_TJ_CSO 64;
BA_ "FlexKomSID" SG_ 947 VC_ASCM_TJ_CSO 2006;
BA_ "FlexKomIsMotorola" SG_ 947 VC_ASCM_TJ_CSO 1;
BA_ "FlexKomComment" SG_ 947 VC_ASCM_TJ_CSO "Vehicle configuration - customer settings menu 1 P";
BA_ "GenSigTimeout_IC" SG_ 947 VC_ASCM_WRN_CSO 21000;
BA_ "GenSigSNA" SG_ 947 VC_ASCM_WRN_CSO "0h";
BA_ "GenSigSendType" SG_ 947 VC_ASCM_WRN_CSO 5;
BA_ "GenSigCycleTime" SG_ 947 VC_ASCM_WRN_CSO 2000;
BA_ "FlexKomSigStartValue" SG_ 947 VC_ASCM_WRN_CSO "0300000000000000h";
BA_ "FlexKomSigStartPos" SG_ 947 VC_ASCM_WRN_CSO 7;
BA_ "FlexKomSigName" SG_ 947 VC_ASCM_WRN_CSO "VehCfgCSM1_Pkt";
BA_ "FlexKomSigLaenge" SG_ 947 VC_ASCM_WRN_CSO 64;
BA_ "FlexKomSID" SG_ 947 VC_ASCM_WRN_CSO 2006;
BA_ "FlexKomIsMotorola" SG_ 947 VC_ASCM_WRN_CSO 1;
BA_ "FlexKomComment" SG_ 947 VC_ASCM_WRN_CSO "Vehicle configuration - customer settings menu 1 P";
BA_ "GenSigTimeout_IC" SG_ 947 VC_AUTO_AERO_CSO 21000;
BA_ "GenSigSNA" SG_ 947 VC_AUTO_AERO_CSO "0h";
BA_ "GenSigSendType" SG_ 947 VC_AUTO_AERO_CSO 5;
BA_ "GenSigCycleTime" SG_ 947 VC_AUTO_AERO_CSO 2000;
BA_ "FlexKomSigStartValue" SG_ 947 VC_AUTO_AERO_CSO "0300000000000000h";
BA_ "FlexKomSigStartPos" SG_ 947 VC_AUTO_AERO_CSO 7;
BA_ "FlexKomSigName" SG_ 947 VC_AUTO_AERO_CSO "VehCfgCSM1_Pkt";
BA_ "FlexKomSigLaenge" SG_ 947 VC_AUTO_AERO_CSO 64;
BA_ "FlexKomSID" SG_ 947 VC_AUTO_AERO_CSO 2006;
BA_ "FlexKomIsMotorola" SG_ 947 VC_AUTO_AERO_CSO 1;
BA_ "FlexKomComment" SG_ 947 VC_AUTO_AERO_CSO "Vehicle configuration - customer settings menu 1 P";
BA_ "GenSigTimeout_IC" SG_ 947 VC_AUTO_HB_CSO 21000;
BA_ "GenSigSNA" SG_ 947 VC_AUTO_HB_CSO "0h";
BA_ "GenSigSendType" SG_ 947 VC_AUTO_HB_CSO 5;
BA_ "GenSigCycleTime" SG_ 947 VC_AUTO_HB_CSO 2000;
BA_ "FlexKomSigStartValue" SG_ 947 VC_AUTO_HB_CSO "0300000000000000h";
BA_ "FlexKomSigStartPos" SG_ 947 VC_AUTO_HB_CSO 7;
BA_ "FlexKomSigName" SG_ 947 VC_AUTO_HB_CSO "VehCfgCSM1_Pkt";
BA_ "FlexKomSigLaenge" SG_ 947 VC_AUTO_HB_CSO 64;
BA_ "FlexKomSID" SG_ 947 VC_AUTO_HB_CSO 2006;
BA_ "FlexKomIsMotorola" SG_ 947 VC_AUTO_HB_CSO 1;
BA_ "FlexKomComment" SG_ 947 VC_AUTO_HB_CSO "Vehicle configuration - customer settings menu 1 P";
BA_ "GenSigTimeout_IC" SG_ 947 VC_AUTO_PRK_CSO 21000;
BA_ "GenSigSNA" SG_ 947 VC_AUTO_PRK_CSO "0h";
BA_ "GenSigSendType" SG_ 947 VC_AUTO_PRK_CSO 5;
BA_ "GenSigCycleTime" SG_ 947 VC_AUTO_PRK_CSO 2000;
BA_ "FlexKomSigStartValue" SG_ 947 VC_AUTO_PRK_CSO "0300000000000000h";
BA_ "FlexKomSigStartPos" SG_ 947 VC_AUTO_PRK_CSO 7;
BA_ "FlexKomSigName" SG_ 947 VC_AUTO_PRK_CSO "VehCfgCSM1_Pkt";
BA_ "FlexKomSigLaenge" SG_ 947 VC_AUTO_PRK_CSO 64;
BA_ "FlexKomSID" SG_ 947 VC_AUTO_PRK_CSO 2006;
BA_ "FlexKomIsMotorola" SG_ 947 VC_AUTO_PRK_CSO 1;
BA_ "FlexKomComment" SG_ 947 VC_AUTO_PRK_CSO "Vehicle configuration - customer settings menu 1 P";
BA_ "GenSigTimeout_IC" SG_ 947 VC_AUX_SWS_CSO 21000;
BA_ "GenSigSNA" SG_ 947 VC_AUX_SWS_CSO "0h";
BA_ "GenSigSendType" SG_ 947 VC_AUX_SWS_CSO 5;
BA_ "GenSigCycleTime" SG_ 947 VC_AUX_SWS_CSO 2000;
BA_ "FlexKomSigStartValue" SG_ 947 VC_AUX_SWS_CSO "0300000000000000h";
BA_ "FlexKomSigStartPos" SG_ 947 VC_AUX_SWS_CSO 7;
BA_ "FlexKomSigName" SG_ 947 VC_AUX_SWS_CSO "VehCfgCSM1_Pkt";
BA_ "FlexKomSigLaenge" SG_ 947 VC_AUX_SWS_CSO 64;
BA_ "FlexKomSID" SG_ 947 VC_AUX_SWS_CSO 2006;
BA_ "FlexKomIsMotorola" SG_ 947 VC_AUX_SWS_CSO 1;
BA_ "FlexKomComment" SG_ 947 VC_AUX_SWS_CSO "Vehicle configuration - customer settings menu 1 P";
BA_ "GenSigTimeout_IC" SG_ 947 VC_BLIND_SPOT_CSO 21000;
BA_ "GenSigSNA" SG_ 947 VC_BLIND_SPOT_CSO "0h";
BA_ "GenSigSendType" SG_ 947 VC_BLIND_SPOT_CSO 5;
BA_ "GenSigCycleTime" SG_ 947 VC_BLIND_SPOT_CSO 2000;
BA_ "FlexKomSigStartValue" SG_ 947 VC_BLIND_SPOT_CSO "0300000000000000h";
BA_ "FlexKomSigStartPos" SG_ 947 VC_BLIND_SPOT_CSO 7;
BA_ "FlexKomSigName" SG_ 947 VC_BLIND_SPOT_CSO "VehCfgCSM1_Pkt";
BA_ "FlexKomSigLaenge" SG_ 947 VC_BLIND_SPOT_CSO 64;
BA_ "FlexKomSID" SG_ 947 VC_BLIND_SPOT_CSO 2006;
BA_ "FlexKomIsMotorola" SG_ 947 VC_BLIND_SPOT_CSO 1;
BA_ "FlexKomComment" SG_ 947 VC_BLIND_SPOT_CSO "Vehicle configuration - customer settings menu 1 P";
BA_ "GenSigTimeout_IC" SG_ 947 VC_CAPACITY_CSO 21000;
BA_ "GenSigSNA" SG_ 947 VC_CAPACITY_CSO "0h";
BA_ "GenSigSendType" SG_ 947 VC_CAPACITY_CSO 5;
BA_ "GenSigCycleTime" SG_ 947 VC_CAPACITY_CSO 2000;
BA_ "FlexKomSigStartValue" SG_ 947 VC_CAPACITY_CSO "0300000000000000h";
BA_ "FlexKomSigStartPos" SG_ 947 VC_CAPACITY_CSO 7;
BA_ "FlexKomSigName" SG_ 947 VC_CAPACITY_CSO "VehCfgCSM1_Pkt";
BA_ "FlexKomSigLaenge" SG_ 947 VC_CAPACITY_CSO 64;
BA_ "FlexKomSID" SG_ 947 VC_CAPACITY_CSO 2006;
BA_ "FlexKomIsMotorola" SG_ 947 VC_CAPACITY_CSO 1;
BA_ "FlexKomComment" SG_ 947 VC_CAPACITY_CSO "Vehicle configuration - customer settings menu 1 P";
BA_ "GenSigTimeout_IC" SG_ 947 VC_CHMSL_LINE_CSO 21000;
BA_ "GenSigSNA" SG_ 947 VC_CHMSL_LINE_CSO "0h";
BA_ "GenSigSendType" SG_ 947 VC_CHMSL_LINE_CSO 5;
BA_ "GenSigCycleTime" SG_ 947 VC_CHMSL_LINE_CSO 2000;
BA_ "FlexKomSigStartValue" SG_ 947 VC_CHMSL_LINE_CSO "0300000000000000h";
BA_ "FlexKomSigStartPos" SG_ 947 VC_CHMSL_LINE_CSO 7;
BA_ "FlexKomSigName" SG_ 947 VC_CHMSL_LINE_CSO "VehCfgCSM1_Pkt";
BA_ "FlexKomSigLaenge" SG_ 947 VC_CHMSL_LINE_CSO 64;
BA_ "FlexKomSID" SG_ 947 VC_CHMSL_LINE_CSO 2006;
BA_ "FlexKomIsMotorola" SG_ 947 VC_CHMSL_LINE_CSO 1;
BA_ "FlexKomComment" SG_ 947 VC_CHMSL_LINE_CSO "Vehicle configuration - customer settings menu 1 P";
BA_ "GenSigTimeout_IC" SG_ 947 VC_CLK_DSP_CSO 21000;
BA_ "GenSigSNA" SG_ 947 VC_CLK_DSP_CSO "0h";
BA_ "GenSigSendType" SG_ 947 VC_CLK_DSP_CSO 5;
BA_ "GenSigCycleTime" SG_ 947 VC_CLK_DSP_CSO 2000;
BA_ "FlexKomSigStartValue" SG_ 947 VC_CLK_DSP_CSO "0300000000000000h";
BA_ "FlexKomSigStartPos" SG_ 947 VC_CLK_DSP_CSO 7;
BA_ "FlexKomSigName" SG_ 947 VC_CLK_DSP_CSO "VehCfgCSM1_Pkt";
BA_ "FlexKomSigLaenge" SG_ 947 VC_CLK_DSP_CSO 64;
BA_ "FlexKomSID" SG_ 947 VC_CLK_DSP_CSO 2006;
BA_ "FlexKomIsMotorola" SG_ 947 VC_CLK_DSP_CSO 1;
BA_ "FlexKomComment" SG_ 947 VC_CLK_DSP_CSO "Vehicle configuration - customer settings menu 1 P";
BA_ "GenSigTimeout_IC" SG_ 947 VC_CMP_CAL_CSO 21000;
BA_ "GenSigSNA" SG_ 947 VC_CMP_CAL_CSO "0h";
BA_ "GenSigSendType" SG_ 947 VC_CMP_CAL_CSO 5;
BA_ "GenSigCycleTime" SG_ 947 VC_CMP_CAL_CSO 2000;
BA_ "FlexKomSigStartValue" SG_ 947 VC_CMP_CAL_CSO "0300000000000000h";
BA_ "FlexKomSigStartPos" SG_ 947 VC_CMP_CAL_CSO 7;
BA_ "FlexKomSigName" SG_ 947 VC_CMP_CAL_CSO "VehCfgCSM1_Pkt";
BA_ "FlexKomSigLaenge" SG_ 947 VC_CMP_CAL_CSO 64;
BA_ "FlexKomSID" SG_ 947 VC_CMP_CAL_CSO 2006;
BA_ "FlexKomIsMotorola" SG_ 947 VC_CMP_CAL_CSO 1;
BA_ "FlexKomComment" SG_ 947 VC_CMP_CAL_CSO "Vehicle configuration - customer settings menu 1 P";
BA_ "GenSigTimeout_IC" SG_ 947 VC_CMP_VAR_CSO 21000;
BA_ "GenSigSNA" SG_ 947 VC_CMP_VAR_CSO "0h";
BA_ "GenSigSendType" SG_ 947 VC_CMP_VAR_CSO 5;
BA_ "GenSigCycleTime" SG_ 947 VC_CMP_VAR_CSO 2000;
BA_ "FlexKomSigStartValue" SG_ 947 VC_CMP_VAR_CSO "0300000000000000h";
BA_ "FlexKomSigStartPos" SG_ 947 VC_CMP_VAR_CSO 7;
BA_ "FlexKomSigName" SG_ 947 VC_CMP_VAR_CSO "VehCfgCSM1_Pkt";
BA_ "FlexKomSigLaenge" SG_ 947 VC_CMP_VAR_CSO 64;
BA_ "FlexKomSID" SG_ 947 VC_CMP_VAR_CSO 2006;
BA_ "FlexKomIsMotorola" SG_ 947 VC_CMP_VAR_CSO 1;
BA_ "FlexKomComment" SG_ 947 VC_CMP_VAR_CSO "Vehicle configuration - customer settings menu 1 P";
BA_ "GenSigTimeout_IC" SG_ 947 VC_CMRA_GRDLNS_CSO 21000;
BA_ "GenSigSNA" SG_ 947 VC_CMRA_GRDLNS_CSO "0h";
BA_ "GenSigSendType" SG_ 947 VC_CMRA_GRDLNS_CSO 5;
BA_ "GenSigCycleTime" SG_ 947 VC_CMRA_GRDLNS_CSO 2000;
BA_ "FlexKomSigStartValue" SG_ 947 VC_CMRA_GRDLNS_CSO "0300000000000000h";
BA_ "FlexKomSigStartPos" SG_ 947 VC_CMRA_GRDLNS_CSO 7;
BA_ "FlexKomSigName" SG_ 947 VC_CMRA_GRDLNS_CSO "VehCfgCSM1_Pkt";
BA_ "FlexKomSigLaenge" SG_ 947 VC_CMRA_GRDLNS_CSO 64;
BA_ "FlexKomSID" SG_ 947 VC_CMRA_GRDLNS_CSO 2006;
BA_ "FlexKomIsMotorola" SG_ 947 VC_CMRA_GRDLNS_CSO 1;
BA_ "FlexKomComment" SG_ 947 VC_CMRA_GRDLNS_CSO "Vehicle configuration - customer settings menu 1 P";
BA_ "GenSigTimeout_IC" SG_ 947 VC_CONS_CSO 21000;
BA_ "GenSigSNA" SG_ 947 VC_CONS_CSO "0h";
BA_ "GenSigSendType" SG_ 947 VC_CONS_CSO 5;
BA_ "GenSigCycleTime" SG_ 947 VC_CONS_CSO 2000;
BA_ "FlexKomSigStartValue" SG_ 947 VC_CONS_CSO "0300000000000000h";
BA_ "FlexKomSigStartPos" SG_ 947 VC_CONS_CSO 7;
BA_ "FlexKomSigName" SG_ 947 VC_CONS_CSO "VehCfgCSM1_Pkt";
BA_ "FlexKomSigLaenge" SG_ 947 VC_CONS_CSO 64;
BA_ "FlexKomSID" SG_ 947 VC_CONS_CSO 2006;
BA_ "FlexKomIsMotorola" SG_ 947 VC_CONS_CSO 1;
BA_ "FlexKomComment" SG_ 947 VC_CONS_CSO "Vehicle configuration - customer settings menu 1 P";
BA_ "GenSigTimeout_IC" SG_ 947 VC_DCS_CSO 21000;
BA_ "GenSigSNA" SG_ 947 VC_DCS_CSO "0h";
BA_ "GenSigSendType" SG_ 947 VC_DCS_CSO 5;
BA_ "GenSigCycleTime" SG_ 947 VC_DCS_CSO 2000;
BA_ "FlexKomSigStartValue" SG_ 947 VC_DCS_CSO "0300000000000000h";
BA_ "FlexKomSigStartPos" SG_ 947 VC_DCS_CSO 7;
BA_ "FlexKomSigName" SG_ 947 VC_DCS_CSO "VehCfgCSM1_Pkt";
BA_ "FlexKomSigLaenge" SG_ 947 VC_DCS_CSO 64;
BA_ "FlexKomSID" SG_ 947 VC_DCS_CSO 2006;
BA_ "FlexKomIsMotorola" SG_ 947 VC_DCS_CSO 1;
BA_ "FlexKomComment" SG_ 947 VC_DCS_CSO "Vehicle configuration - customer settings menu 1 P";
BA_ "GenSigTimeout_IC" SG_ 947 VC_DISTANCE_CSO 21000;
BA_ "GenSigSNA" SG_ 947 VC_DISTANCE_CSO "0h";
BA_ "GenSigSendType" SG_ 947 VC_DISTANCE_CSO 5;
BA_ "GenSigCycleTime" SG_ 947 VC_DISTANCE_CSO 2000;
BA_ "FlexKomSigStartValue" SG_ 947 VC_DISTANCE_CSO "0300000000000000h";
BA_ "FlexKomSigStartPos" SG_ 947 VC_DISTANCE_CSO 7;
BA_ "FlexKomSigName" SG_ 947 VC_DISTANCE_CSO "VehCfgCSM1_Pkt";
BA_ "FlexKomSigLaenge" SG_ 947 VC_DISTANCE_CSO 64;
BA_ "FlexKomSID" SG_ 947 VC_DISTANCE_CSO 2006;
BA_ "FlexKomIsMotorola" SG_ 947 VC_DISTANCE_CSO 1;
BA_ "FlexKomComment" SG_ 947 VC_DISTANCE_CSO "Vehicle configuration - customer settings menu 1 P";
BA_ "GenSigTimeout_IC" SG_ 947 VC_DRL_CSO 21000;
BA_ "GenSigSNA" SG_ 947 VC_DRL_CSO "0h";
BA_ "GenSigSendType" SG_ 947 VC_DRL_CSO 5;
BA_ "GenSigCycleTime" SG_ 947 VC_DRL_CSO 2000;
BA_ "FlexKomSigStartValue" SG_ 947 VC_DRL_CSO "0300000000000000h";
BA_ "FlexKomSigStartPos" SG_ 947 VC_DRL_CSO 7;
BA_ "FlexKomSigName" SG_ 947 VC_DRL_CSO "VehCfgCSM1_Pkt";
BA_ "FlexKomSigLaenge" SG_ 947 VC_DRL_CSO 64;
BA_ "FlexKomSID" SG_ 947 VC_DRL_CSO 2006;
BA_ "FlexKomIsMotorola" SG_ 947 VC_DRL_CSO 1;
BA_ "FlexKomComment" SG_ 947 VC_DRL_CSO "Vehicle configuration - customer settings menu 1 P";
BA_ "GenSigTimeout_IC" SG_ 947 VC_DR_LK_CSO 21000;
BA_ "GenSigSNA" SG_ 947 VC_DR_LK_CSO "0h";
BA_ "GenSigSendType" SG_ 947 VC_DR_LK_CSO 5;
BA_ "GenSigCycleTime" SG_ 947 VC_DR_LK_CSO 2000;
BA_ "FlexKomSigStartValue" SG_ 947 VC_DR_LK_CSO "0300000000000000h";
BA_ "FlexKomSigStartPos" SG_ 947 VC_DR_LK_CSO 7;
BA_ "FlexKomSigName" SG_ 947 VC_DR_LK_CSO "VehCfgCSM1_Pkt";
BA_ "FlexKomSigLaenge" SG_ 947 VC_DR_LK_CSO 64;
BA_ "FlexKomSID" SG_ 947 VC_DR_LK_CSO 2006;
BA_ "FlexKomIsMotorola" SG_ 947 VC_DR_LK_CSO 1;
BA_ "FlexKomComment" SG_ 947 VC_DR_LK_CSO "Vehicle configuration - customer settings menu 1 P";
BA_ "GenSigTimeout_IC" SG_ 947 VC_DR_UNLK_CSO 21000;
BA_ "GenSigSNA" SG_ 947 VC_DR_UNLK_CSO "0h";
BA_ "GenSigSendType" SG_ 947 VC_DR_UNLK_CSO 5;
BA_ "GenSigCycleTime" SG_ 947 VC_DR_UNLK_CSO 2000;
BA_ "FlexKomSigStartValue" SG_ 947 VC_DR_UNLK_CSO "0300000000000000h";
BA_ "FlexKomSigStartPos" SG_ 947 VC_DR_UNLK_CSO 7;
BA_ "FlexKomSigName" SG_ 947 VC_DR_UNLK_CSO "VehCfgCSM1_Pkt";
BA_ "FlexKomSigLaenge" SG_ 947 VC_DR_UNLK_CSO 64;
BA_ "FlexKomSID" SG_ 947 VC_DR_UNLK_CSO 2006;
BA_ "FlexKomIsMotorola" SG_ 947 VC_DR_UNLK_CSO 1;
BA_ "FlexKomComment" SG_ 947 VC_DR_UNLK_CSO "Vehicle configuration - customer settings menu 1 P";
BA_ "GenSigTimeout_IC" SG_ 947 VC_EASY_EXIT_CSO 21000;
BA_ "GenSigSNA" SG_ 947 VC_EASY_EXIT_CSO "0h";
BA_ "GenSigSendType" SG_ 947 VC_EASY_EXIT_CSO 5;
BA_ "GenSigCycleTime" SG_ 947 VC_EASY_EXIT_CSO 2000;
BA_ "FlexKomSigStartValue" SG_ 947 VC_EASY_EXIT_CSO "0300000000000000h";
BA_ "FlexKomSigStartPos" SG_ 947 VC_EASY_EXIT_CSO 7;
BA_ "FlexKomSigName" SG_ 947 VC_EASY_EXIT_CSO "VehCfgCSM1_Pkt";
BA_ "FlexKomSigLaenge" SG_ 947 VC_EASY_EXIT_CSO 64;
BA_ "FlexKomSID" SG_ 947 VC_EASY_EXIT_CSO 2006;
BA_ "FlexKomIsMotorola" SG_ 947 VC_EASY_EXIT_CSO 1;
BA_ "FlexKomComment" SG_ 947 VC_EASY_EXIT_CSO "Vehicle configuration - customer settings menu 1 P";
BA_ "GenSigTimeout_IC" SG_ 947 VC_ENTRY_EXIT_CSO 21000;
BA_ "GenSigSNA" SG_ 947 VC_ENTRY_EXIT_CSO "0h";
BA_ "GenSigSendType" SG_ 947 VC_ENTRY_EXIT_CSO 5;
BA_ "GenSigCycleTime" SG_ 947 VC_ENTRY_EXIT_CSO 2000;
BA_ "FlexKomSigStartValue" SG_ 947 VC_ENTRY_EXIT_CSO "0300000000000000h";
BA_ "FlexKomSigStartPos" SG_ 947 VC_ENTRY_EXIT_CSO 7;
BA_ "FlexKomSigName" SG_ 947 VC_ENTRY_EXIT_CSO "VehCfgCSM1_Pkt";
BA_ "FlexKomSigLaenge" SG_ 947 VC_ENTRY_EXIT_CSO 64;
BA_ "FlexKomSID" SG_ 947 VC_ENTRY_EXIT_CSO 2006;
BA_ "FlexKomIsMotorola" SG_ 947 VC_ENTRY_EXIT_CSO 1;
BA_ "FlexKomComment" SG_ 947 VC_ENTRY_EXIT_CSO "Vehicle configuration - customer settings menu 1 P";
BA_ "GenSigTimeout_IC" SG_ 947 VC_EPB_SERV_CSO 21000;
BA_ "GenSigSNA" SG_ 947 VC_EPB_SERV_CSO "0h";
BA_ "GenSigSendType" SG_ 947 VC_EPB_SERV_CSO 5;
BA_ "GenSigCycleTime" SG_ 947 VC_EPB_SERV_CSO 2000;
BA_ "FlexKomSigStartValue" SG_ 947 VC_EPB_SERV_CSO "0300000000000000h";
BA_ "FlexKomSigStartPos" SG_ 947 VC_EPB_SERV_CSO 7;
BA_ "FlexKomSigName" SG_ 947 VC_EPB_SERV_CSO "VehCfgCSM1_Pkt";
BA_ "FlexKomSigLaenge" SG_ 947 VC_EPB_SERV_CSO 64;
BA_ "FlexKomSID" SG_ 947 VC_EPB_SERV_CSO 2006;
BA_ "FlexKomIsMotorola" SG_ 947 VC_EPB_SERV_CSO 1;
BA_ "FlexKomComment" SG_ 947 VC_EPB_SERV_CSO "Vehicle configuration - customer settings menu 1 P";
BA_ "GenSigTimeout_IC" SG_ 947 VC_EPS_CSO 21000;
BA_ "GenSigSNA" SG_ 947 VC_EPS_CSO "0h";
BA_ "GenSigSendType" SG_ 947 VC_EPS_CSO 5;
BA_ "GenSigCycleTime" SG_ 947 VC_EPS_CSO 2000;
BA_ "FlexKomSigStartValue" SG_ 947 VC_EPS_CSO "0300000000000000h";
BA_ "FlexKomSigStartPos" SG_ 947 VC_EPS_CSO 7;
BA_ "FlexKomSigName" SG_ 947 VC_EPS_CSO "VehCfgCSM1_Pkt";
BA_ "FlexKomSigLaenge" SG_ 947 VC_EPS_CSO 64;
BA_ "FlexKomSID" SG_ 947 VC_EPS_CSO 2006;
BA_ "FlexKomIsMotorola" SG_ 947 VC_EPS_CSO 1;
BA_ "FlexKomComment" SG_ 947 VC_EPS_CSO "Vehicle configuration - customer settings menu 1 P";
BA_ "GenSigTimeout_IC" SG_ 947 VC_FCW_BRK_CSO 21000;
BA_ "GenSigSNA" SG_ 947 VC_FCW_BRK_CSO "0h";
BA_ "GenSigSendType" SG_ 947 VC_FCW_BRK_CSO 5;
BA_ "GenSigCycleTime" SG_ 947 VC_FCW_BRK_CSO 2000;
BA_ "FlexKomSigStartValue" SG_ 947 VC_FCW_BRK_CSO "0300000000000000h";
BA_ "FlexKomSigStartPos" SG_ 947 VC_FCW_BRK_CSO 7;
BA_ "FlexKomSigName" SG_ 947 VC_FCW_BRK_CSO "VehCfgCSM1_Pkt";
BA_ "FlexKomSigLaenge" SG_ 947 VC_FCW_BRK_CSO 64;
BA_ "FlexKomSID" SG_ 947 VC_FCW_BRK_CSO 2006;
BA_ "FlexKomIsMotorola" SG_ 947 VC_FCW_BRK_CSO 1;
BA_ "FlexKomComment" SG_ 947 VC_FCW_BRK_CSO "Vehicle configuration - customer settings menu 1 P";
BA_ "GenSigTimeout_IC" SG_ 947 VC_FCW_CSO 21000;
BA_ "GenSigSNA" SG_ 947 VC_FCW_CSO "0h";
BA_ "GenSigSendType" SG_ 947 VC_FCW_CSO 5;
BA_ "GenSigCycleTime" SG_ 947 VC_FCW_CSO 2000;
BA_ "FlexKomSigStartValue" SG_ 947 VC_FCW_CSO "0300000000000000h";
BA_ "FlexKomSigStartPos" SG_ 947 VC_FCW_CSO 7;
BA_ "FlexKomSigName" SG_ 947 VC_FCW_CSO "VehCfgCSM1_Pkt";
BA_ "FlexKomSigLaenge" SG_ 947 VC_FCW_CSO 64;
BA_ "FlexKomSID" SG_ 947 VC_FCW_CSO 2006;
BA_ "FlexKomIsMotorola" SG_ 947 VC_FCW_CSO 1;
BA_ "FlexKomComment" SG_ 947 VC_FCW_CSO "Vehicle configuration - customer settings menu 1 P";
BA_ "GenSigTimeout_IC" SG_ 947 VC_FLSH_LMP_LK_CSO 21000;
BA_ "GenSigSNA" SG_ 947 VC_FLSH_LMP_LK_CSO "0h";
BA_ "GenSigSendType" SG_ 947 VC_FLSH_LMP_LK_CSO 5;
BA_ "GenSigCycleTime" SG_ 947 VC_FLSH_LMP_LK_CSO 2000;
BA_ "FlexKomSigStartValue" SG_ 947 VC_FLSH_LMP_LK_CSO "0300000000000000h";
BA_ "FlexKomSigStartPos" SG_ 947 VC_FLSH_LMP_LK_CSO 7;
BA_ "FlexKomSigName" SG_ 947 VC_FLSH_LMP_LK_CSO "VehCfgCSM1_Pkt";
BA_ "FlexKomSigLaenge" SG_ 947 VC_FLSH_LMP_LK_CSO 64;
BA_ "FlexKomSID" SG_ 947 VC_FLSH_LMP_LK_CSO 2006;
BA_ "FlexKomIsMotorola" SG_ 947 VC_FLSH_LMP_LK_CSO 1;
BA_ "FlexKomComment" SG_ 947 VC_FLSH_LMP_LK_CSO "Vehicle configuration - customer settings menu 1 P";
BA_ "GenSigTimeout_IC" SG_ 947 VC_HL_DRP_CSO 21000;
BA_ "GenSigSNA" SG_ 947 VC_HL_DRP_CSO "0h";
BA_ "GenSigSendType" SG_ 947 VC_HL_DRP_CSO 5;
BA_ "GenSigCycleTime" SG_ 947 VC_HL_DRP_CSO 2000;
BA_ "FlexKomSigStartValue" SG_ 947 VC_HL_DRP_CSO "0300000000000000h";
BA_ "FlexKomSigStartPos" SG_ 947 VC_HL_DRP_CSO 7;
BA_ "FlexKomSigName" SG_ 947 VC_HL_DRP_CSO "VehCfgCSM1_Pkt";
BA_ "FlexKomSigLaenge" SG_ 947 VC_HL_DRP_CSO 64;
BA_ "FlexKomSID" SG_ 947 VC_HL_DRP_CSO 2006;
BA_ "FlexKomIsMotorola" SG_ 947 VC_HL_DRP_CSO 1;
BA_ "FlexKomComment" SG_ 947 VC_HL_DRP_CSO "Vehicle configuration - customer settings menu 1 P";
BA_ "GenSigTimeout_IC" SG_ 947 VC_HL_OFF_DLY_CSO 21000;
BA_ "GenSigSNA" SG_ 947 VC_HL_OFF_DLY_CSO "0h";
BA_ "GenSigSendType" SG_ 947 VC_HL_OFF_DLY_CSO 5;
BA_ "GenSigCycleTime" SG_ 947 VC_HL_OFF_DLY_CSO 2000;
BA_ "FlexKomSigStartValue" SG_ 947 VC_HL_OFF_DLY_CSO "0300000000000000h";
BA_ "FlexKomSigStartPos" SG_ 947 VC_HL_OFF_DLY_CSO 7;
BA_ "FlexKomSigName" SG_ 947 VC_HL_OFF_DLY_CSO "VehCfgCSM1_Pkt";
BA_ "FlexKomSigLaenge" SG_ 947 VC_HL_OFF_DLY_CSO 64;
BA_ "FlexKomSID" SG_ 947 VC_HL_OFF_DLY_CSO 2006;
BA_ "FlexKomIsMotorola" SG_ 947 VC_HL_OFF_DLY_CSO 1;
BA_ "FlexKomComment" SG_ 947 VC_HL_OFF_DLY_CSO "Vehicle configuration - customer settings menu 1 P";
BA_ "GenSigTimeout_IC" SG_ 947 VC_HL_WPR_CSO 21000;
BA_ "GenSigSNA" SG_ 947 VC_HL_WPR_CSO "0h";
BA_ "GenSigSendType" SG_ 947 VC_HL_WPR_CSO 5;
BA_ "GenSigCycleTime" SG_ 947 VC_HL_WPR_CSO 2000;
BA_ "FlexKomSigStartValue" SG_ 947 VC_HL_WPR_CSO "0300000000000000h";
BA_ "FlexKomSigStartPos" SG_ 947 VC_HL_WPR_CSO 7;
BA_ "FlexKomSigName" SG_ 947 VC_HL_WPR_CSO "VehCfgCSM1_Pkt";
BA_ "FlexKomSigLaenge" SG_ 947 VC_HL_WPR_CSO 64;
BA_ "FlexKomSID" SG_ 947 VC_HL_WPR_CSO 2006;
BA_ "FlexKomIsMotorola" SG_ 947 VC_HL_WPR_CSO 1;
BA_ "FlexKomComment" SG_ 947 VC_HL_WPR_CSO "Vehicle configuration - customer settings menu 1 P";
BA_ "GenSigTimeout_IC" SG_ 947 VC_HRN_RMT_LK_CSO 21000;
BA_ "GenSigSNA" SG_ 947 VC_HRN_RMT_LK_CSO "0h";
BA_ "GenSigSendType" SG_ 947 VC_HRN_RMT_LK_CSO 5;
BA_ "GenSigCycleTime" SG_ 947 VC_HRN_RMT_LK_CSO 2000;
BA_ "FlexKomSigStartValue" SG_ 947 VC_HRN_RMT_LK_CSO "0300000000000000h";
BA_ "FlexKomSigStartPos" SG_ 947 VC_HRN_RMT_LK_CSO 7;
BA_ "FlexKomSigName" SG_ 947 VC_HRN_RMT_LK_CSO "VehCfgCSM1_Pkt";
BA_ "FlexKomSigLaenge" SG_ 947 VC_HRN_RMT_LK_CSO 64;
BA_ "FlexKomSID" SG_ 947 VC_HRN_RMT_LK_CSO 2006;
BA_ "FlexKomIsMotorola" SG_ 947 VC_HRN_RMT_LK_CSO 1;
BA_ "FlexKomComment" SG_ 947 VC_HRN_RMT_LK_CSO "Vehicle configuration - customer settings menu 1 P";
BA_ "GenSigTimeout_IC" SG_ 947 VC_HRN_RMT_LWR_CSO 21000;
BA_ "GenSigSNA" SG_ 947 VC_HRN_RMT_LWR_CSO "0h";
BA_ "GenSigSendType" SG_ 947 VC_HRN_RMT_LWR_CSO 5;
BA_ "GenSigCycleTime" SG_ 947 VC_HRN_RMT_LWR_CSO 2000;
BA_ "FlexKomSigStartValue" SG_ 947 VC_HRN_RMT_LWR_CSO "0300000000000000h";
BA_ "FlexKomSigStartPos" SG_ 947 VC_HRN_RMT_LWR_CSO 7;
BA_ "FlexKomSigName" SG_ 947 VC_HRN_RMT_LWR_CSO "VehCfgCSM1_Pkt";
BA_ "FlexKomSigLaenge" SG_ 947 VC_HRN_RMT_LWR_CSO 64;
BA_ "FlexKomSID" SG_ 947 VC_HRN_RMT_LWR_CSO 2006;
BA_ "FlexKomIsMotorola" SG_ 947 VC_HRN_RMT_LWR_CSO 1;
BA_ "FlexKomComment" SG_ 947 VC_HRN_RMT_LWR_CSO "Vehicle configuration - customer settings menu 1 P";
BA_ "GenSigTimeout_IC" SG_ 947 VC_HRN_RMT_ST_CSO 21000;
BA_ "GenSigSNA" SG_ 947 VC_HRN_RMT_ST_CSO "0h";
BA_ "GenSigSendType" SG_ 947 VC_HRN_RMT_ST_CSO 5;
BA_ "GenSigCycleTime" SG_ 947 VC_HRN_RMT_ST_CSO 2000;
BA_ "FlexKomSigStartValue" SG_ 947 VC_HRN_RMT_ST_CSO "0300000000000000h";
BA_ "FlexKomSigStartPos" SG_ 947 VC_HRN_RMT_ST_CSO 7;
BA_ "FlexKomSigName" SG_ 947 VC_HRN_RMT_ST_CSO "VehCfgCSM1_Pkt";
BA_ "FlexKomSigLaenge" SG_ 947 VC_HRN_RMT_ST_CSO 64;
BA_ "FlexKomSID" SG_ 947 VC_HRN_RMT_ST_CSO 2006;
BA_ "FlexKomIsMotorola" SG_ 947 VC_HRN_RMT_ST_CSO 1;
BA_ "FlexKomComment" SG_ 947 VC_HRN_RMT_ST_CSO "Vehicle configuration - customer settings menu 1 P";
BA_ "GenSigTimeout_IC" SG_ 947 VC_HSA_CSO 21000;
BA_ "GenSigSNA" SG_ 947 VC_HSA_CSO "0h";
BA_ "GenSigSendType" SG_ 947 VC_HSA_CSO 5;
BA_ "GenSigCycleTime" SG_ 947 VC_HSA_CSO 2000;
BA_ "FlexKomSigStartValue" SG_ 947 VC_HSA_CSO "0300000000000000h";
BA_ "FlexKomSigStartPos" SG_ 947 VC_HSA_CSO 7;
BA_ "FlexKomSigName" SG_ 947 VC_HSA_CSO "VehCfgCSM1_Pkt";
BA_ "FlexKomSigLaenge" SG_ 947 VC_HSA_CSO 64;
BA_ "FlexKomSID" SG_ 947 VC_HSA_CSO 2006;
BA_ "FlexKomIsMotorola" SG_ 947 VC_HSA_CSO 1;
BA_ "FlexKomComment" SG_ 947 VC_HSA_CSO "Vehicle configuration - customer settings menu 1 P";
BA_ "GenSigTimeout_IC" SG_ 947 VC_ILL_APPRCH_CSO 21000;
BA_ "GenSigSNA" SG_ 947 VC_ILL_APPRCH_CSO "0h";
BA_ "GenSigSendType" SG_ 947 VC_ILL_APPRCH_CSO 5;
BA_ "GenSigCycleTime" SG_ 947 VC_ILL_APPRCH_CSO 2000;
BA_ "FlexKomSigStartValue" SG_ 947 VC_ILL_APPRCH_CSO "0300000000000000h";
BA_ "FlexKomSigStartPos" SG_ 947 VC_ILL_APPRCH_CSO 7;
BA_ "FlexKomSigName" SG_ 947 VC_ILL_APPRCH_CSO "VehCfgCSM1_Pkt";
BA_ "FlexKomSigLaenge" SG_ 947 VC_ILL_APPRCH_CSO 64;
BA_ "FlexKomSID" SG_ 947 VC_ILL_APPRCH_CSO 2006;
BA_ "FlexKomIsMotorola" SG_ 947 VC_ILL_APPRCH_CSO 1;
BA_ "FlexKomComment" SG_ 947 VC_ILL_APPRCH_CSO "Vehicle configuration - customer settings menu 1 P";
BA_ "GenSigTimeout_IC" SG_ 947 VC_LDW_TRQ_CSO 21000;
BA_ "GenSigSNA" SG_ 947 VC_LDW_TRQ_CSO "0h";
BA_ "GenSigSendType" SG_ 947 VC_LDW_TRQ_CSO 5;
BA_ "GenSigCycleTime" SG_ 947 VC_LDW_TRQ_CSO 2000;
BA_ "FlexKomSigStartValue" SG_ 947 VC_LDW_TRQ_CSO "0300000000000000h";
BA_ "FlexKomSigStartPos" SG_ 947 VC_LDW_TRQ_CSO 7;
BA_ "FlexKomSigName" SG_ 947 VC_LDW_TRQ_CSO "VehCfgCSM1_Pkt";
BA_ "FlexKomSigLaenge" SG_ 947 VC_LDW_TRQ_CSO 64;
BA_ "FlexKomSID" SG_ 947 VC_LDW_TRQ_CSO 2006;
BA_ "FlexKomIsMotorola" SG_ 947 VC_LDW_TRQ_CSO 1;
BA_ "FlexKomComment" SG_ 947 VC_LDW_TRQ_CSO "Vehicle configuration - customer settings menu 1 P";
BA_ "GenSigTimeout_IC" SG_ 947 VC_LDW_WRN_CSO 21000;
BA_ "GenSigSNA" SG_ 947 VC_LDW_WRN_CSO "0h";
BA_ "GenSigSendType" SG_ 947 VC_LDW_WRN_CSO 5;
BA_ "GenSigCycleTime" SG_ 947 VC_LDW_WRN_CSO 2000;
BA_ "FlexKomSigStartValue" SG_ 947 VC_LDW_WRN_CSO "0300000000000000h";
BA_ "FlexKomSigStartPos" SG_ 947 VC_LDW_WRN_CSO 7;
BA_ "FlexKomSigName" SG_ 947 VC_LDW_WRN_CSO "VehCfgCSM1_Pkt";
BA_ "FlexKomSigLaenge" SG_ 947 VC_LDW_WRN_CSO 64;
BA_ "FlexKomSID" SG_ 947 VC_LDW_WRN_CSO 2006;
BA_ "FlexKomIsMotorola" SG_ 947 VC_LDW_WRN_CSO 1;
BA_ "FlexKomComment" SG_ 947 VC_LDW_WRN_CSO "Vehicle configuration - customer settings menu 1 P";
BA_ "GenSigTimeout_IC" SG_ 947 VC_LGHT_RMT_LWR_CSO 21000;
BA_ "GenSigSNA" SG_ 947 VC_LGHT_RMT_LWR_CSO "0h";
BA_ "GenSigSendType" SG_ 947 VC_LGHT_RMT_LWR_CSO 5;
BA_ "GenSigCycleTime" SG_ 947 VC_LGHT_RMT_LWR_CSO 2000;
BA_ "FlexKomSigStartValue" SG_ 947 VC_LGHT_RMT_LWR_CSO "0300000000000000h";
BA_ "FlexKomSigStartPos" SG_ 947 VC_LGHT_RMT_LWR_CSO 7;
BA_ "FlexKomSigName" SG_ 947 VC_LGHT_RMT_LWR_CSO "VehCfgCSM1_Pkt";
BA_ "FlexKomSigLaenge" SG_ 947 VC_LGHT_RMT_LWR_CSO 64;
BA_ "FlexKomSID" SG_ 947 VC_LGHT_RMT_LWR_CSO 2006;
BA_ "FlexKomIsMotorola" SG_ 947 VC_LGHT_RMT_LWR_CSO 1;
BA_ "FlexKomComment" SG_ 947 VC_LGHT_RMT_LWR_CSO "Vehicle configuration - customer settings menu 1 P";
BA_ "GenSigTimeout_IC" SG_ 947 VC_NAV_TRN_CSO 21000;
BA_ "GenSigSNA" SG_ 947 VC_NAV_TRN_CSO "0h";
BA_ "GenSigSendType" SG_ 947 VC_NAV_TRN_CSO 5;
BA_ "GenSigCycleTime" SG_ 947 VC_NAV_TRN_CSO 2000;
BA_ "FlexKomSigStartValue" SG_ 947 VC_NAV_TRN_CSO "0300000000000000h";
BA_ "FlexKomSigStartPos" SG_ 947 VC_NAV_TRN_CSO 7;
BA_ "FlexKomSigName" SG_ 947 VC_NAV_TRN_CSO "VehCfgCSM1_Pkt";
BA_ "FlexKomSigLaenge" SG_ 947 VC_NAV_TRN_CSO 64;
BA_ "FlexKomSID" SG_ 947 VC_NAV_TRN_CSO 2006;
BA_ "FlexKomIsMotorola" SG_ 947 VC_NAV_TRN_CSO 1;
BA_ "FlexKomComment" SG_ 947 VC_NAV_TRN_CSO "Vehicle configuration - customer settings menu 1 P";
BA_ "GenSigTimeout_IC" SG_ 947 VC_PER_SHFT_ENBL_CSO 21000;
BA_ "GenSigSNA" SG_ 947 VC_PER_SHFT_ENBL_CSO "0h";
BA_ "GenSigSendType" SG_ 947 VC_PER_SHFT_ENBL_CSO 5;
BA_ "GenSigCycleTime" SG_ 947 VC_PER_SHFT_ENBL_CSO 2000;
BA_ "FlexKomSigStartValue" SG_ 947 VC_PER_SHFT_ENBL_CSO "0300000000000000h";
BA_ "FlexKomSigStartPos" SG_ 947 VC_PER_SHFT_ENBL_CSO 7;
BA_ "FlexKomSigName" SG_ 947 VC_PER_SHFT_ENBL_CSO "VehCfgCSM1_Pkt";
BA_ "FlexKomSigLaenge" SG_ 947 VC_PER_SHFT_ENBL_CSO 64;
BA_ "FlexKomSID" SG_ 947 VC_PER_SHFT_ENBL_CSO 2006;
BA_ "FlexKomIsMotorola" SG_ 947 VC_PER_SHFT_ENBL_CSO 1;
BA_ "FlexKomComment" SG_ 947 VC_PER_SHFT_ENBL_CSO "Vehicle configuration - customer settings menu 1 P";
BA_ "GenSigTimeout_IC" SG_ 947 VC_PER_SHFT_RPM_CSO 21000;
BA_ "GenSigSNA" SG_ 947 VC_PER_SHFT_RPM_CSO "0h";
BA_ "GenSigSendType" SG_ 947 VC_PER_SHFT_RPM_CSO 5;
BA_ "GenSigCycleTime" SG_ 947 VC_PER_SHFT_RPM_CSO 2000;
BA_ "FlexKomSigStartValue" SG_ 947 VC_PER_SHFT_RPM_CSO "0300000000000000h";
BA_ "FlexKomSigStartPos" SG_ 947 VC_PER_SHFT_RPM_CSO 7;
BA_ "FlexKomSigName" SG_ 947 VC_PER_SHFT_RPM_CSO "VehCfgCSM1_Pkt";
BA_ "FlexKomSigLaenge" SG_ 947 VC_PER_SHFT_RPM_CSO 64;
BA_ "FlexKomSID" SG_ 947 VC_PER_SHFT_RPM_CSO 2006;
BA_ "FlexKomIsMotorola" SG_ 947 VC_PER_SHFT_RPM_CSO 1;
BA_ "FlexKomComment" SG_ 947 VC_PER_SHFT_RPM_CSO "Vehicle configuration - customer settings menu 1 P";
BA_ "GenSigTimeout_IC" SG_ 947 VC_PE_CSO 21000;
BA_ "GenSigSNA" SG_ 947 VC_PE_CSO "0h";
BA_ "GenSigSendType" SG_ 947 VC_PE_CSO 5;
BA_ "GenSigCycleTime" SG_ 947 VC_PE_CSO 2000;
BA_ "FlexKomSigStartValue" SG_ 947 VC_PE_CSO "0300000000000000h";
BA_ "FlexKomSigStartPos" SG_ 947 VC_PE_CSO 7;
BA_ "FlexKomSigName" SG_ 947 VC_PE_CSO "VehCfgCSM1_Pkt";
BA_ "FlexKomSigLaenge" SG_ 947 VC_PE_CSO 64;
BA_ "FlexKomSID" SG_ 947 VC_PE_CSO 2006;
BA_ "FlexKomIsMotorola" SG_ 947 VC_PE_CSO 1;
BA_ "FlexKomComment" SG_ 947 VC_PE_CSO "Vehicle configuration - customer settings menu 1 P";
BA_ "GenSigTimeout_IC" SG_ 947 VC_PLG_CHM_CSO 21000;
BA_ "GenSigSNA" SG_ 947 VC_PLG_CHM_CSO "0h";
BA_ "GenSigSendType" SG_ 947 VC_PLG_CHM_CSO 5;
BA_ "GenSigCycleTime" SG_ 947 VC_PLG_CHM_CSO 2000;
BA_ "FlexKomSigStartValue" SG_ 947 VC_PLG_CHM_CSO "0300000000000000h";
BA_ "FlexKomSigStartPos" SG_ 947 VC_PLG_CHM_CSO 7;
BA_ "FlexKomSigName" SG_ 947 VC_PLG_CHM_CSO "VehCfgCSM1_Pkt";
BA_ "FlexKomSigLaenge" SG_ 947 VC_PLG_CHM_CSO 64;
BA_ "FlexKomSID" SG_ 947 VC_PLG_CHM_CSO 2006;
BA_ "FlexKomIsMotorola" SG_ 947 VC_PLG_CHM_CSO 1;
BA_ "FlexKomComment" SG_ 947 VC_PLG_CHM_CSO "Vehicle configuration - customer settings menu 1 P";
BA_ "GenSigTimeout_IC" SG_ 947 VC_POLICE_PE_CSO 21000;
BA_ "GenSigSNA" SG_ 947 VC_POLICE_PE_CSO "0h";
BA_ "GenSigSendType" SG_ 947 VC_POLICE_PE_CSO 5;
BA_ "GenSigCycleTime" SG_ 947 VC_POLICE_PE_CSO 2000;
BA_ "FlexKomSigStartValue" SG_ 947 VC_POLICE_PE_CSO "0300000000000000h";
BA_ "FlexKomSigStartPos" SG_ 947 VC_POLICE_PE_CSO 7;
BA_ "FlexKomSigName" SG_ 947 VC_POLICE_PE_CSO "VehCfgCSM1_Pkt";
BA_ "FlexKomSigLaenge" SG_ 947 VC_POLICE_PE_CSO 64;
BA_ "FlexKomSID" SG_ 947 VC_POLICE_PE_CSO 2006;
BA_ "FlexKomIsMotorola" SG_ 947 VC_POLICE_PE_CSO 1;
BA_ "FlexKomComment" SG_ 947 VC_POLICE_PE_CSO "Vehicle configuration - customer settings menu 1 P";
BA_ "GenSigTimeout_IC" SG_ 947 VC_POWER_CSO 21000;
BA_ "GenSigSNA" SG_ 947 VC_POWER_CSO "0h";
BA_ "GenSigSendType" SG_ 947 VC_POWER_CSO 5;
BA_ "GenSigCycleTime" SG_ 947 VC_POWER_CSO 2000;
BA_ "FlexKomSigStartValue" SG_ 947 VC_POWER_CSO "0300000000000000h";
BA_ "FlexKomSigStartPos" SG_ 947 VC_POWER_CSO 7;
BA_ "FlexKomSigName" SG_ 947 VC_POWER_CSO "VehCfgCSM1_Pkt";
BA_ "FlexKomSigLaenge" SG_ 947 VC_POWER_CSO 64;
BA_ "FlexKomSID" SG_ 947 VC_POWER_CSO 2006;
BA_ "FlexKomIsMotorola" SG_ 947 VC_POWER_CSO 1;
BA_ "FlexKomComment" SG_ 947 VC_POWER_CSO "Vehicle configuration - customer settings menu 1 P";
BA_ "GenSigTimeout_IC" SG_ 947 VC_PRESSURE_CSO 21000;
BA_ "GenSigSNA" SG_ 947 VC_PRESSURE_CSO "0h";
BA_ "GenSigSendType" SG_ 947 VC_PRESSURE_CSO 5;
BA_ "GenSigCycleTime" SG_ 947 VC_PRESSURE_CSO 2000;
BA_ "FlexKomSigStartValue" SG_ 947 VC_PRESSURE_CSO "0300000000000000h";
BA_ "FlexKomSigStartPos" SG_ 947 VC_PRESSURE_CSO 7;
BA_ "FlexKomSigName" SG_ 947 VC_PRESSURE_CSO "VehCfgCSM1_Pkt";
BA_ "FlexKomSigLaenge" SG_ 947 VC_PRESSURE_CSO 64;
BA_ "FlexKomSID" SG_ 947 VC_PRESSURE_CSO 2006;
BA_ "FlexKomIsMotorola" SG_ 947 VC_PRESSURE_CSO 1;
BA_ "FlexKomComment" SG_ 947 VC_PRESSURE_CSO "Vehicle configuration - customer settings menu 1 P";
BA_ "GenSigTimeout_IC" SG_ 947 VC_PRK_AST_BRK_CSO 21000;
BA_ "GenSigSNA" SG_ 947 VC_PRK_AST_BRK_CSO "0h";
BA_ "GenSigSendType" SG_ 947 VC_PRK_AST_BRK_CSO 5;
BA_ "GenSigCycleTime" SG_ 947 VC_PRK_AST_BRK_CSO 2000;
BA_ "FlexKomSigStartValue" SG_ 947 VC_PRK_AST_BRK_CSO "0300000000000000h";
BA_ "FlexKomSigStartPos" SG_ 947 VC_PRK_AST_BRK_CSO 7;
BA_ "FlexKomSigName" SG_ 947 VC_PRK_AST_BRK_CSO "VehCfgCSM1_Pkt";
BA_ "FlexKomSigLaenge" SG_ 947 VC_PRK_AST_BRK_CSO 64;
BA_ "FlexKomSID" SG_ 947 VC_PRK_AST_BRK_CSO 2006;
BA_ "FlexKomIsMotorola" SG_ 947 VC_PRK_AST_BRK_CSO 1;
BA_ "FlexKomComment" SG_ 947 VC_PRK_AST_BRK_CSO "Vehicle configuration - customer settings menu 1 P";
BA_ "GenSigTimeout_IC" SG_ 947 VC_PRK_AST_CSO 21000;
BA_ "GenSigSNA" SG_ 947 VC_PRK_AST_CSO "0h";
BA_ "GenSigSendType" SG_ 947 VC_PRK_AST_CSO 5;
BA_ "GenSigCycleTime" SG_ 947 VC_PRK_AST_CSO 2000;
BA_ "FlexKomSigStartValue" SG_ 947 VC_PRK_AST_CSO "0300000000000000h";
BA_ "FlexKomSigStartPos" SG_ 947 VC_PRK_AST_CSO 7;
BA_ "FlexKomSigName" SG_ 947 VC_PRK_AST_CSO "VehCfgCSM1_Pkt";
BA_ "FlexKomSigLaenge" SG_ 947 VC_PRK_AST_CSO 64;
BA_ "FlexKomSID" SG_ 947 VC_PRK_AST_CSO 2006;
BA_ "FlexKomIsMotorola" SG_ 947 VC_PRK_AST_CSO 1;
BA_ "FlexKomComment" SG_ 947 VC_PRK_AST_CSO "Vehicle configuration - customer settings menu 1 P";
BA_ "GenSigTimeout_IC" SG_ 947 VC_PRK_FT_VOL_CSO 21000;
BA_ "GenSigSNA" SG_ 947 VC_PRK_FT_VOL_CSO "0h";
BA_ "GenSigSendType" SG_ 947 VC_PRK_FT_VOL_CSO 5;
BA_ "GenSigCycleTime" SG_ 947 VC_PRK_FT_VOL_CSO 2000;
BA_ "FlexKomSigStartValue" SG_ 947 VC_PRK_FT_VOL_CSO "0300000000000000h";
BA_ "FlexKomSigStartPos" SG_ 947 VC_PRK_FT_VOL_CSO 7;
BA_ "FlexKomSigName" SG_ 947 VC_PRK_FT_VOL_CSO "VehCfgCSM1_Pkt";
BA_ "FlexKomSigLaenge" SG_ 947 VC_PRK_FT_VOL_CSO 64;
BA_ "FlexKomSID" SG_ 947 VC_PRK_FT_VOL_CSO 2006;
BA_ "FlexKomIsMotorola" SG_ 947 VC_PRK_FT_VOL_CSO 1;
BA_ "FlexKomComment" SG_ 947 VC_PRK_FT_VOL_CSO "Vehicle configuration - customer settings menu 1 P";
BA_ "GenSigTimeout_IC" SG_ 947 VC_PRK_RR_VOL_CSO 21000;
BA_ "GenSigSNA" SG_ 947 VC_PRK_RR_VOL_CSO "0h";
BA_ "GenSigSendType" SG_ 947 VC_PRK_RR_VOL_CSO 5;
BA_ "GenSigCycleTime" SG_ 947 VC_PRK_RR_VOL_CSO 2000;
BA_ "FlexKomSigStartValue" SG_ 947 VC_PRK_RR_VOL_CSO "0300000000000000h";
BA_ "FlexKomSigStartPos" SG_ 947 VC_PRK_RR_VOL_CSO 7;
BA_ "FlexKomSigName" SG_ 947 VC_PRK_RR_VOL_CSO "VehCfgCSM1_Pkt";
BA_ "FlexKomSigLaenge" SG_ 947 VC_PRK_RR_VOL_CSO 64;
BA_ "FlexKomSID" SG_ 947 VC_PRK_RR_VOL_CSO 2006;
BA_ "FlexKomIsMotorola" SG_ 947 VC_PRK_RR_VOL_CSO 1;
BA_ "FlexKomComment" SG_ 947 VC_PRK_RR_VOL_CSO "Vehicle configuration - customer settings menu 1 P";
BA_ "GenSigTimeout_IC" SG_ 947 VC_PTO_CSO 21000;
BA_ "GenSigSNA" SG_ 947 VC_PTO_CSO "0h";
BA_ "GenSigSendType" SG_ 947 VC_PTO_CSO 5;
BA_ "GenSigCycleTime" SG_ 947 VC_PTO_CSO 2000;
BA_ "FlexKomSigStartValue" SG_ 947 VC_PTO_CSO "0300000000000000h";
BA_ "FlexKomSigStartPos" SG_ 947 VC_PTO_CSO 7;
BA_ "FlexKomSigName" SG_ 947 VC_PTO_CSO "VehCfgCSM1_Pkt";
BA_ "FlexKomSigLaenge" SG_ 947 VC_PTO_CSO 64;
BA_ "FlexKomSID" SG_ 947 VC_PTO_CSO 2006;
BA_ "FlexKomIsMotorola" SG_ 947 VC_PTO_CSO 1;
BA_ "FlexKomComment" SG_ 947 VC_PTO_CSO "Vehicle configuration - customer settings menu 1 P";
BA_ "GenSigTimeout_IC" SG_ 947 VC_RAIN_WPR_CSO 21000;
BA_ "GenSigSNA" SG_ 947 VC_RAIN_WPR_CSO "0h";
BA_ "GenSigSendType" SG_ 947 VC_RAIN_WPR_CSO 5;
BA_ "GenSigCycleTime" SG_ 947 VC_RAIN_WPR_CSO 2000;
BA_ "FlexKomSigStartValue" SG_ 947 VC_RAIN_WPR_CSO "0300000000000000h";
BA_ "FlexKomSigStartPos" SG_ 947 VC_RAIN_WPR_CSO 7;
BA_ "FlexKomSigName" SG_ 947 VC_RAIN_WPR_CSO "VehCfgCSM1_Pkt";
BA_ "FlexKomSigLaenge" SG_ 947 VC_RAIN_WPR_CSO 64;
BA_ "FlexKomSID" SG_ 947 VC_RAIN_WPR_CSO 2006;
BA_ "FlexKomIsMotorola" SG_ 947 VC_RAIN_WPR_CSO 1;
BA_ "FlexKomComment" SG_ 947 VC_RAIN_WPR_CSO "Vehicle configuration - customer settings menu 1 P";
BA_ "GenSigTimeout_IC" SG_ 947 VC_REAR_CMRA_CSO 21000;
BA_ "GenSigSNA" SG_ 947 VC_REAR_CMRA_CSO "0h";
BA_ "GenSigSendType" SG_ 947 VC_REAR_CMRA_CSO 5;
BA_ "GenSigCycleTime" SG_ 947 VC_REAR_CMRA_CSO 2000;
BA_ "FlexKomSigStartValue" SG_ 947 VC_REAR_CMRA_CSO "0300000000000000h";
BA_ "FlexKomSigStartPos" SG_ 947 VC_REAR_CMRA_CSO 7;
BA_ "FlexKomSigName" SG_ 947 VC_REAR_CMRA_CSO "VehCfgCSM1_Pkt";
BA_ "FlexKomSigLaenge" SG_ 947 VC_REAR_CMRA_CSO 64;
BA_ "FlexKomSID" SG_ 947 VC_REAR_CMRA_CSO 2006;
BA_ "FlexKomIsMotorola" SG_ 947 VC_REAR_CMRA_CSO 1;
BA_ "FlexKomComment" SG_ 947 VC_REAR_CMRA_CSO "Vehicle configuration - customer settings menu 1 P";
BA_ "GenSigSNA" SG_ 947 VC_UNIT_SET_CSO "0h";
BA_ "GenSigSendType" SG_ 947 VC_UNIT_SET_CSO 5;
BA_ "GenSigCycleTime" SG_ 947 VC_UNIT_SET_CSO 2000;
BA_ "FlexKomSigStartValue" SG_ 947 VC_UNIT_SET_CSO "0300000000000000h";
BA_ "FlexKomSigStartPos" SG_ 947 VC_UNIT_SET_CSO 7;
BA_ "FlexKomSigName" SG_ 947 VC_UNIT_SET_CSO "VehCfgCSM1_Pkt";
BA_ "FlexKomSigLaenge" SG_ 947 VC_UNIT_SET_CSO 64;
BA_ "FlexKomSID" SG_ 947 VC_UNIT_SET_CSO 2006;
BA_ "FlexKomIsMotorola" SG_ 947 VC_UNIT_SET_CSO 1;
BA_ "FlexKomComment" SG_ 947 VC_UNIT_SET_CSO "Vehicle configuration - customer settings menu 1 P";
BA_ "GenSigTimeout_IC" SG_ 947 VC_VehCfgCSO1_Stat 21000;
BA_ "GenSigStartValue" SG_ 947 VC_VehCfgCSO1_Stat 3;
BA_ "GenSigSNA" SG_ 947 VC_VehCfgCSO1_Stat "3h";
BA_ "GenSigSendType" SG_ 947 VC_VehCfgCSO1_Stat 5;
BA_ "GenSigCycleTime" SG_ 947 VC_VehCfgCSO1_Stat 2000;
BA_ "FlexKomSigStartValue" SG_ 947 VC_VehCfgCSO1_Stat "0300000000000000h";
BA_ "FlexKomSigStartPos" SG_ 947 VC_VehCfgCSO1_Stat 7;
BA_ "FlexKomSigName" SG_ 947 VC_VehCfgCSO1_Stat "VehCfgCSM1_Pkt";
BA_ "FlexKomSigLaenge" SG_ 947 VC_VehCfgCSO1_Stat 64;
BA_ "FlexKomSID" SG_ 947 VC_VehCfgCSO1_Stat 2006;
BA_ "FlexKomIsMotorola" SG_ 947 VC_VehCfgCSO1_Stat 1;
BA_ "FlexKomComment" SG_ 947 VC_VehCfgCSO1_Stat "Vehicle configuration - customer settings menu 1 P";
BA_ "GenSigSNA" SG_ 949 VC_BU_ACC_DLY_CSO "0h";
BA_ "GenSigSendType" SG_ 949 VC_BU_ACC_DLY_CSO 1;
BA_ "FlexKomSigStartValue" SG_ 949 VC_BU_ACC_DLY_CSO "0300000000000000h";
BA_ "FlexKomSigStartPos" SG_ 949 VC_BU_ACC_DLY_CSO 7;
BA_ "FlexKomSigName" SG_ 949 VC_BU_ACC_DLY_CSO "VehCfgCSM1_BuPkt";
BA_ "FlexKomSigLaenge" SG_ 949 VC_BU_ACC_DLY_CSO 64;
BA_ "FlexKomSID" SG_ 949 VC_BU_ACC_DLY_CSO 2008;
BA_ "FlexKomIsMotorola" SG_ 949 VC_BU_ACC_DLY_CSO 1;
BA_ "FlexKomComment" SG_ 949 VC_BU_ACC_DLY_CSO "Backup for veh config - customer settings menu 1 P";
BA_ "GenSigSNA" SG_ 949 VC_BU_AFLS_CSO "0h";
BA_ "GenSigSendType" SG_ 949 VC_BU_AFLS_CSO 1;
BA_ "FlexKomSigStartValue" SG_ 949 VC_BU_AFLS_CSO "0300000000000000h";
BA_ "FlexKomSigStartPos" SG_ 949 VC_BU_AFLS_CSO 7;
BA_ "FlexKomSigName" SG_ 949 VC_BU_AFLS_CSO "VehCfgCSM1_BuPkt";
BA_ "FlexKomSigLaenge" SG_ 949 VC_BU_AFLS_CSO 64;
BA_ "FlexKomSID" SG_ 949 VC_BU_AFLS_CSO 2008;
BA_ "FlexKomIsMotorola" SG_ 949 VC_BU_AFLS_CSO 1;
BA_ "FlexKomComment" SG_ 949 VC_BU_AFLS_CSO "Backup for veh config - customer settings menu 1 P";
BA_ "GenSigSNA" SG_ 949 VC_BU_AMB_DMR_CSO "0h";
BA_ "GenSigSendType" SG_ 949 VC_BU_AMB_DMR_CSO 1;
BA_ "FlexKomSigStartValue" SG_ 949 VC_BU_AMB_DMR_CSO "0300000000000000h";
BA_ "FlexKomSigStartPos" SG_ 949 VC_BU_AMB_DMR_CSO 7;
BA_ "FlexKomSigName" SG_ 949 VC_BU_AMB_DMR_CSO "VehCfgCSM1_BuPkt";
BA_ "FlexKomSigLaenge" SG_ 949 VC_BU_AMB_DMR_CSO 64;
BA_ "FlexKomSID" SG_ 949 VC_BU_AMB_DMR_CSO 2008;
BA_ "FlexKomIsMotorola" SG_ 949 VC_BU_AMB_DMR_CSO 1;
BA_ "FlexKomComment" SG_ 949 VC_BU_AMB_DMR_CSO "Backup for veh config - customer settings menu 1 P";
BA_ "GenSigSNA" SG_ 949 VC_BU_ASCM_TJ_CSO "0h";
BA_ "GenSigSendType" SG_ 949 VC_BU_ASCM_TJ_CSO 1;
BA_ "FlexKomSigStartValue" SG_ 949 VC_BU_ASCM_TJ_CSO "0300000000000000h";
BA_ "FlexKomSigStartPos" SG_ 949 VC_BU_ASCM_TJ_CSO 7;
BA_ "FlexKomSigName" SG_ 949 VC_BU_ASCM_TJ_CSO "VehCfgCSM1_BuPkt";
BA_ "FlexKomSigLaenge" SG_ 949 VC_BU_ASCM_TJ_CSO 64;
BA_ "FlexKomSID" SG_ 949 VC_BU_ASCM_TJ_CSO 2008;
BA_ "FlexKomIsMotorola" SG_ 949 VC_BU_ASCM_TJ_CSO 1;
BA_ "FlexKomComment" SG_ 949 VC_BU_ASCM_TJ_CSO "Backup for veh config - customer settings menu 1 P";
BA_ "GenSigSNA" SG_ 949 VC_BU_ASCM_WRN_CSO "0h";
BA_ "GenSigSendType" SG_ 949 VC_BU_ASCM_WRN_CSO 1;
BA_ "FlexKomSigStartValue" SG_ 949 VC_BU_ASCM_WRN_CSO "0300000000000000h";
BA_ "FlexKomSigStartPos" SG_ 949 VC_BU_ASCM_WRN_CSO 7;
BA_ "FlexKomSigName" SG_ 949 VC_BU_ASCM_WRN_CSO "VehCfgCSM1_BuPkt";
BA_ "FlexKomSigLaenge" SG_ 949 VC_BU_ASCM_WRN_CSO 64;
BA_ "FlexKomSID" SG_ 949 VC_BU_ASCM_WRN_CSO 2008;
BA_ "FlexKomIsMotorola" SG_ 949 VC_BU_ASCM_WRN_CSO 1;
BA_ "FlexKomComment" SG_ 949 VC_BU_ASCM_WRN_CSO "Backup for veh config - customer settings menu 1 P";
BA_ "GenSigSNA" SG_ 949 VC_BU_AUTO_AERO_CSO "0h";
BA_ "GenSigSendType" SG_ 949 VC_BU_AUTO_AERO_CSO 1;
BA_ "FlexKomSigStartValue" SG_ 949 VC_BU_AUTO_AERO_CSO "0300000000000000h";
BA_ "FlexKomSigStartPos" SG_ 949 VC_BU_AUTO_AERO_CSO 7;
BA_ "FlexKomSigName" SG_ 949 VC_BU_AUTO_AERO_CSO "VehCfgCSM1_BuPkt";
BA_ "FlexKomSigLaenge" SG_ 949 VC_BU_AUTO_AERO_CSO 64;
BA_ "FlexKomSID" SG_ 949 VC_BU_AUTO_AERO_CSO 2008;
BA_ "FlexKomIsMotorola" SG_ 949 VC_BU_AUTO_AERO_CSO 1;
BA_ "FlexKomComment" SG_ 949 VC_BU_AUTO_AERO_CSO "Backup for veh config - customer settings menu 1 P";
BA_ "GenSigSNA" SG_ 949 VC_BU_AUTO_HB_CSO "0h";
BA_ "GenSigSendType" SG_ 949 VC_BU_AUTO_HB_CSO 1;
BA_ "FlexKomSigStartValue" SG_ 949 VC_BU_AUTO_HB_CSO "0300000000000000h";
BA_ "FlexKomSigStartPos" SG_ 949 VC_BU_AUTO_HB_CSO 7;
BA_ "FlexKomSigName" SG_ 949 VC_BU_AUTO_HB_CSO "VehCfgCSM1_BuPkt";
BA_ "FlexKomSigLaenge" SG_ 949 VC_BU_AUTO_HB_CSO 64;
BA_ "FlexKomSID" SG_ 949 VC_BU_AUTO_HB_CSO 2008;
BA_ "FlexKomIsMotorola" SG_ 949 VC_BU_AUTO_HB_CSO 1;
BA_ "FlexKomComment" SG_ 949 VC_BU_AUTO_HB_CSO "Backup for veh config - customer settings menu 1 P";
BA_ "GenSigSNA" SG_ 949 VC_BU_AUTO_PRK_CSO "0h";
BA_ "GenSigSendType" SG_ 949 VC_BU_AUTO_PRK_CSO 1;
BA_ "FlexKomSigStartValue" SG_ 949 VC_BU_AUTO_PRK_CSO "0300000000000000h";
BA_ "FlexKomSigStartPos" SG_ 949 VC_BU_AUTO_PRK_CSO 7;
BA_ "FlexKomSigName" SG_ 949 VC_BU_AUTO_PRK_CSO "VehCfgCSM1_BuPkt";
BA_ "FlexKomSigLaenge" SG_ 949 VC_BU_AUTO_PRK_CSO 64;
BA_ "FlexKomSID" SG_ 949 VC_BU_AUTO_PRK_CSO 2008;
BA_ "FlexKomIsMotorola" SG_ 949 VC_BU_AUTO_PRK_CSO 1;
BA_ "FlexKomComment" SG_ 949 VC_BU_AUTO_PRK_CSO "Backup for veh config - customer settings menu 1 P";
BA_ "GenSigSNA" SG_ 949 VC_BU_AUX_SWS_CSO "0h";
BA_ "GenSigSendType" SG_ 949 VC_BU_AUX_SWS_CSO 1;
BA_ "FlexKomSigStartValue" SG_ 949 VC_BU_AUX_SWS_CSO "0300000000000000h";
BA_ "FlexKomSigStartPos" SG_ 949 VC_BU_AUX_SWS_CSO 7;
BA_ "FlexKomSigName" SG_ 949 VC_BU_AUX_SWS_CSO "VehCfgCSM1_BuPkt";
BA_ "FlexKomSigLaenge" SG_ 949 VC_BU_AUX_SWS_CSO 64;
BA_ "FlexKomSID" SG_ 949 VC_BU_AUX_SWS_CSO 2008;
BA_ "FlexKomIsMotorola" SG_ 949 VC_BU_AUX_SWS_CSO 1;
BA_ "FlexKomComment" SG_ 949 VC_BU_AUX_SWS_CSO "Backup for veh config - customer settings menu 1 P";
BA_ "GenSigSNA" SG_ 949 VC_BU_BLIND_SPOT_CSO "0h";
BA_ "GenSigSendType" SG_ 949 VC_BU_BLIND_SPOT_CSO 1;
BA_ "FlexKomSigStartValue" SG_ 949 VC_BU_BLIND_SPOT_CSO "0300000000000000h";
BA_ "FlexKomSigStartPos" SG_ 949 VC_BU_BLIND_SPOT_CSO 7;
BA_ "FlexKomSigName" SG_ 949 VC_BU_BLIND_SPOT_CSO "VehCfgCSM1_BuPkt";
BA_ "FlexKomSigLaenge" SG_ 949 VC_BU_BLIND_SPOT_CSO 64;
BA_ "FlexKomSID" SG_ 949 VC_BU_BLIND_SPOT_CSO 2008;
BA_ "FlexKomIsMotorola" SG_ 949 VC_BU_BLIND_SPOT_CSO 1;
BA_ "FlexKomComment" SG_ 949 VC_BU_BLIND_SPOT_CSO "Backup for veh config - customer settings menu 1 P";
BA_ "GenSigSNA" SG_ 949 VC_BU_CAPACITY_CSO "0h";
BA_ "GenSigSendType" SG_ 949 VC_BU_CAPACITY_CSO 1;
BA_ "FlexKomSigStartValue" SG_ 949 VC_BU_CAPACITY_CSO "0300000000000000h";
BA_ "FlexKomSigStartPos" SG_ 949 VC_BU_CAPACITY_CSO 7;
BA_ "FlexKomSigName" SG_ 949 VC_BU_CAPACITY_CSO "VehCfgCSM1_BuPkt";
BA_ "FlexKomSigLaenge" SG_ 949 VC_BU_CAPACITY_CSO 64;
BA_ "FlexKomSID" SG_ 949 VC_BU_CAPACITY_CSO 2008;
BA_ "FlexKomIsMotorola" SG_ 949 VC_BU_CAPACITY_CSO 1;
BA_ "FlexKomComment" SG_ 949 VC_BU_CAPACITY_CSO "Backup for veh config - customer settings menu 1 P";
BA_ "GenSigSNA" SG_ 949 VC_BU_CHMSL_LINE_CSO "0h";
BA_ "GenSigSendType" SG_ 949 VC_BU_CHMSL_LINE_CSO 1;
BA_ "FlexKomSigStartValue" SG_ 949 VC_BU_CHMSL_LINE_CSO "0300000000000000h";
BA_ "FlexKomSigStartPos" SG_ 949 VC_BU_CHMSL_LINE_CSO 7;
BA_ "FlexKomSigName" SG_ 949 VC_BU_CHMSL_LINE_CSO "VehCfgCSM1_BuPkt";
BA_ "FlexKomSigLaenge" SG_ 949 VC_BU_CHMSL_LINE_CSO 64;
BA_ "FlexKomSID" SG_ 949 VC_BU_CHMSL_LINE_CSO 2008;
BA_ "FlexKomIsMotorola" SG_ 949 VC_BU_CHMSL_LINE_CSO 1;
BA_ "FlexKomComment" SG_ 949 VC_BU_CHMSL_LINE_CSO "Backup for veh config - customer settings menu 1 P";
BA_ "GenSigSNA" SG_ 949 VC_BU_CLK_DSP_CSO "0h";
BA_ "GenSigSendType" SG_ 949 VC_BU_CLK_DSP_CSO 1;
BA_ "FlexKomSigStartValue" SG_ 949 VC_BU_CLK_DSP_CSO "0300000000000000h";
BA_ "FlexKomSigStartPos" SG_ 949 VC_BU_CLK_DSP_CSO 7;
BA_ "FlexKomSigName" SG_ 949 VC_BU_CLK_DSP_CSO "VehCfgCSM1_BuPkt";
BA_ "FlexKomSigLaenge" SG_ 949 VC_BU_CLK_DSP_CSO 64;
BA_ "FlexKomSID" SG_ 949 VC_BU_CLK_DSP_CSO 2008;
BA_ "FlexKomIsMotorola" SG_ 949 VC_BU_CLK_DSP_CSO 1;
BA_ "FlexKomComment" SG_ 949 VC_BU_CLK_DSP_CSO "Backup for veh config - customer settings menu 1 P";
BA_ "GenSigSNA" SG_ 949 VC_BU_CMP_CAL_CSO "0h";
BA_ "GenSigSendType" SG_ 949 VC_BU_CMP_CAL_CSO 1;
BA_ "FlexKomSigStartValue" SG_ 949 VC_BU_CMP_CAL_CSO "0300000000000000h";
BA_ "FlexKomSigStartPos" SG_ 949 VC_BU_CMP_CAL_CSO 7;
BA_ "FlexKomSigName" SG_ 949 VC_BU_CMP_CAL_CSO "VehCfgCSM1_BuPkt";
BA_ "FlexKomSigLaenge" SG_ 949 VC_BU_CMP_CAL_CSO 64;
BA_ "FlexKomSID" SG_ 949 VC_BU_CMP_CAL_CSO 2008;
BA_ "FlexKomIsMotorola" SG_ 949 VC_BU_CMP_CAL_CSO 1;
BA_ "FlexKomComment" SG_ 949 VC_BU_CMP_CAL_CSO "Backup for veh config - customer settings menu 1 P";
BA_ "GenSigSNA" SG_ 949 VC_BU_CMP_VAR_CSO "0h";
BA_ "GenSigSendType" SG_ 949 VC_BU_CMP_VAR_CSO 1;
BA_ "FlexKomSigStartValue" SG_ 949 VC_BU_CMP_VAR_CSO "0300000000000000h";
BA_ "FlexKomSigStartPos" SG_ 949 VC_BU_CMP_VAR_CSO 7;
BA_ "FlexKomSigName" SG_ 949 VC_BU_CMP_VAR_CSO "VehCfgCSM1_BuPkt";
BA_ "FlexKomSigLaenge" SG_ 949 VC_BU_CMP_VAR_CSO 64;
BA_ "FlexKomSID" SG_ 949 VC_BU_CMP_VAR_CSO 2008;
BA_ "FlexKomIsMotorola" SG_ 949 VC_BU_CMP_VAR_CSO 1;
BA_ "FlexKomComment" SG_ 949 VC_BU_CMP_VAR_CSO "Backup for veh config - customer settings menu 1 P";
BA_ "GenSigSNA" SG_ 949 VC_BU_CMRA_GRDLNS_CSO "0h";
BA_ "GenSigSendType" SG_ 949 VC_BU_CMRA_GRDLNS_CSO 1;
BA_ "FlexKomSigStartValue" SG_ 949 VC_BU_CMRA_GRDLNS_CSO "0300000000000000h";
BA_ "FlexKomSigStartPos" SG_ 949 VC_BU_CMRA_GRDLNS_CSO 7;
BA_ "FlexKomSigName" SG_ 949 VC_BU_CMRA_GRDLNS_CSO "VehCfgCSM1_BuPkt";
BA_ "FlexKomSigLaenge" SG_ 949 VC_BU_CMRA_GRDLNS_CSO 64;
BA_ "FlexKomSID" SG_ 949 VC_BU_CMRA_GRDLNS_CSO 2008;
BA_ "FlexKomIsMotorola" SG_ 949 VC_BU_CMRA_GRDLNS_CSO 1;
BA_ "FlexKomComment" SG_ 949 VC_BU_CMRA_GRDLNS_CSO "Backup for veh config - customer settings menu 1 P";
BA_ "GenSigSNA" SG_ 949 VC_BU_CONS_CSO "0h";
BA_ "GenSigSendType" SG_ 949 VC_BU_CONS_CSO 1;
BA_ "FlexKomSigStartValue" SG_ 949 VC_BU_CONS_CSO "0300000000000000h";
BA_ "FlexKomSigStartPos" SG_ 949 VC_BU_CONS_CSO 7;
BA_ "FlexKomSigName" SG_ 949 VC_BU_CONS_CSO "VehCfgCSM1_BuPkt";
BA_ "FlexKomSigLaenge" SG_ 949 VC_BU_CONS_CSO 64;
BA_ "FlexKomSID" SG_ 949 VC_BU_CONS_CSO 2008;
BA_ "FlexKomIsMotorola" SG_ 949 VC_BU_CONS_CSO 1;
BA_ "FlexKomComment" SG_ 949 VC_BU_CONS_CSO "Backup for veh config - customer settings menu 1 P";
BA_ "GenSigSNA" SG_ 949 VC_BU_DCS_CSO "0h";
BA_ "GenSigSendType" SG_ 949 VC_BU_DCS_CSO 1;
BA_ "FlexKomSigStartValue" SG_ 949 VC_BU_DCS_CSO "0300000000000000h";
BA_ "FlexKomSigStartPos" SG_ 949 VC_BU_DCS_CSO 7;
BA_ "FlexKomSigName" SG_ 949 VC_BU_DCS_CSO "VehCfgCSM1_BuPkt";
BA_ "FlexKomSigLaenge" SG_ 949 VC_BU_DCS_CSO 64;
BA_ "FlexKomSID" SG_ 949 VC_BU_DCS_CSO 2008;
BA_ "FlexKomIsMotorola" SG_ 949 VC_BU_DCS_CSO 1;
BA_ "FlexKomComment" SG_ 949 VC_BU_DCS_CSO "Backup for veh config - customer settings menu 1 P";
BA_ "GenSigSNA" SG_ 949 VC_BU_DISTANCE_CSO "0h";
BA_ "GenSigSendType" SG_ 949 VC_BU_DISTANCE_CSO 1;
BA_ "FlexKomSigStartValue" SG_ 949 VC_BU_DISTANCE_CSO "0300000000000000h";
BA_ "FlexKomSigStartPos" SG_ 949 VC_BU_DISTANCE_CSO 7;
BA_ "FlexKomSigName" SG_ 949 VC_BU_DISTANCE_CSO "VehCfgCSM1_BuPkt";
BA_ "FlexKomSigLaenge" SG_ 949 VC_BU_DISTANCE_CSO 64;
BA_ "FlexKomSID" SG_ 949 VC_BU_DISTANCE_CSO 2008;
BA_ "FlexKomIsMotorola" SG_ 949 VC_BU_DISTANCE_CSO 1;
BA_ "FlexKomComment" SG_ 949 VC_BU_DISTANCE_CSO "Backup for veh config - customer settings menu 1 P";
BA_ "GenSigSNA" SG_ 949 VC_BU_DRL_CSO "0h";
BA_ "GenSigSendType" SG_ 949 VC_BU_DRL_CSO 1;
BA_ "FlexKomSigStartValue" SG_ 949 VC_BU_DRL_CSO "0300000000000000h";
BA_ "FlexKomSigStartPos" SG_ 949 VC_BU_DRL_CSO 7;
BA_ "FlexKomSigName" SG_ 949 VC_BU_DRL_CSO "VehCfgCSM1_BuPkt";
BA_ "FlexKomSigLaenge" SG_ 949 VC_BU_DRL_CSO 64;
BA_ "FlexKomSID" SG_ 949 VC_BU_DRL_CSO 2008;
BA_ "FlexKomIsMotorola" SG_ 949 VC_BU_DRL_CSO 1;
BA_ "FlexKomComment" SG_ 949 VC_BU_DRL_CSO "Backup for veh config - customer settings menu 1 P";
BA_ "GenSigSNA" SG_ 949 VC_BU_DR_LK_CSO "0h";
BA_ "GenSigSendType" SG_ 949 VC_BU_DR_LK_CSO 1;
BA_ "FlexKomSigStartValue" SG_ 949 VC_BU_DR_LK_CSO "0300000000000000h";
BA_ "FlexKomSigStartPos" SG_ 949 VC_BU_DR_LK_CSO 7;
BA_ "FlexKomSigName" SG_ 949 VC_BU_DR_LK_CSO "VehCfgCSM1_BuPkt";
BA_ "FlexKomSigLaenge" SG_ 949 VC_BU_DR_LK_CSO 64;
BA_ "FlexKomSID" SG_ 949 VC_BU_DR_LK_CSO 2008;
BA_ "FlexKomIsMotorola" SG_ 949 VC_BU_DR_LK_CSO 1;
BA_ "FlexKomComment" SG_ 949 VC_BU_DR_LK_CSO "Backup for veh config - customer settings menu 1 P";
BA_ "GenSigSNA" SG_ 949 VC_BU_DR_UNLK_CSO "0h";
BA_ "GenSigSendType" SG_ 949 VC_BU_DR_UNLK_CSO 1;
BA_ "FlexKomSigStartValue" SG_ 949 VC_BU_DR_UNLK_CSO "0300000000000000h";
BA_ "FlexKomSigStartPos" SG_ 949 VC_BU_DR_UNLK_CSO 7;
BA_ "FlexKomSigName" SG_ 949 VC_BU_DR_UNLK_CSO "VehCfgCSM1_BuPkt";
BA_ "FlexKomSigLaenge" SG_ 949 VC_BU_DR_UNLK_CSO 64;
BA_ "FlexKomSID" SG_ 949 VC_BU_DR_UNLK_CSO 2008;
BA_ "FlexKomIsMotorola" SG_ 949 VC_BU_DR_UNLK_CSO 1;
BA_ "FlexKomComment" SG_ 949 VC_BU_DR_UNLK_CSO "Backup for veh config - customer settings menu 1 P";
BA_ "GenSigSNA" SG_ 949 VC_BU_EASY_EXIT_CSO "0h";
BA_ "GenSigSendType" SG_ 949 VC_BU_EASY_EXIT_CSO 1;
BA_ "FlexKomSigStartValue" SG_ 949 VC_BU_EASY_EXIT_CSO "0300000000000000h";
BA_ "FlexKomSigStartPos" SG_ 949 VC_BU_EASY_EXIT_CSO 7;
BA_ "FlexKomSigName" SG_ 949 VC_BU_EASY_EXIT_CSO "VehCfgCSM1_BuPkt";
BA_ "FlexKomSigLaenge" SG_ 949 VC_BU_EASY_EXIT_CSO 64;
BA_ "FlexKomSID" SG_ 949 VC_BU_EASY_EXIT_CSO 2008;
BA_ "FlexKomIsMotorola" SG_ 949 VC_BU_EASY_EXIT_CSO 1;
BA_ "FlexKomComment" SG_ 949 VC_BU_EASY_EXIT_CSO "Backup for veh config - customer settings menu 1 P";
BA_ "GenSigSNA" SG_ 949 VC_BU_ENTRY_EXIT_CSO "0h";
BA_ "GenSigSendType" SG_ 949 VC_BU_ENTRY_EXIT_CSO 1;
BA_ "FlexKomSigStartValue" SG_ 949 VC_BU_ENTRY_EXIT_CSO "0300000000000000h";
BA_ "FlexKomSigStartPos" SG_ 949 VC_BU_ENTRY_EXIT_CSO 7;
BA_ "FlexKomSigName" SG_ 949 VC_BU_ENTRY_EXIT_CSO "VehCfgCSM1_BuPkt";
BA_ "FlexKomSigLaenge" SG_ 949 VC_BU_ENTRY_EXIT_CSO 64;
BA_ "FlexKomSID" SG_ 949 VC_BU_ENTRY_EXIT_CSO 2008;
BA_ "FlexKomIsMotorola" SG_ 949 VC_BU_ENTRY_EXIT_CSO 1;
BA_ "FlexKomComment" SG_ 949 VC_BU_ENTRY_EXIT_CSO "Backup for veh config - customer settings menu 1 P";
BA_ "GenSigSNA" SG_ 949 VC_BU_EPB_SERV_CSO "0h";
BA_ "GenSigSendType" SG_ 949 VC_BU_EPB_SERV_CSO 1;
BA_ "FlexKomSigStartValue" SG_ 949 VC_BU_EPB_SERV_CSO "0300000000000000h";
BA_ "FlexKomSigStartPos" SG_ 949 VC_BU_EPB_SERV_CSO 7;
BA_ "FlexKomSigName" SG_ 949 VC_BU_EPB_SERV_CSO "VehCfgCSM1_BuPkt";
BA_ "FlexKomSigLaenge" SG_ 949 VC_BU_EPB_SERV_CSO 64;
BA_ "FlexKomSID" SG_ 949 VC_BU_EPB_SERV_CSO 2008;
BA_ "FlexKomIsMotorola" SG_ 949 VC_BU_EPB_SERV_CSO 1;
BA_ "FlexKomComment" SG_ 949 VC_BU_EPB_SERV_CSO "Backup for veh config - customer settings menu 1 P";
BA_ "GenSigSNA" SG_ 949 VC_BU_EPS_CSO "0h";
BA_ "GenSigSendType" SG_ 949 VC_BU_EPS_CSO 1;
BA_ "FlexKomSigStartValue" SG_ 949 VC_BU_EPS_CSO "0300000000000000h";
BA_ "FlexKomSigStartPos" SG_ 949 VC_BU_EPS_CSO 7;
BA_ "FlexKomSigName" SG_ 949 VC_BU_EPS_CSO "VehCfgCSM1_BuPkt";
BA_ "FlexKomSigLaenge" SG_ 949 VC_BU_EPS_CSO 64;
BA_ "FlexKomSID" SG_ 949 VC_BU_EPS_CSO 2008;
BA_ "FlexKomIsMotorola" SG_ 949 VC_BU_EPS_CSO 1;
BA_ "FlexKomComment" SG_ 949 VC_BU_EPS_CSO "Backup for veh config - customer settings menu 1 P";
BA_ "GenSigSNA" SG_ 949 VC_BU_FCW_BRK_CSO "0h";
BA_ "GenSigSendType" SG_ 949 VC_BU_FCW_BRK_CSO 1;
BA_ "FlexKomSigStartValue" SG_ 949 VC_BU_FCW_BRK_CSO "0300000000000000h";
BA_ "FlexKomSigStartPos" SG_ 949 VC_BU_FCW_BRK_CSO 7;
BA_ "FlexKomSigName" SG_ 949 VC_BU_FCW_BRK_CSO "VehCfgCSM1_BuPkt";
BA_ "FlexKomSigLaenge" SG_ 949 VC_BU_FCW_BRK_CSO 64;
BA_ "FlexKomSID" SG_ 949 VC_BU_FCW_BRK_CSO 2008;
BA_ "FlexKomIsMotorola" SG_ 949 VC_BU_FCW_BRK_CSO 1;
BA_ "FlexKomComment" SG_ 949 VC_BU_FCW_BRK_CSO "Backup for veh config - customer settings menu 1 P";
BA_ "GenSigSNA" SG_ 949 VC_BU_FCW_CSO "0h";
BA_ "GenSigSendType" SG_ 949 VC_BU_FCW_CSO 1;
BA_ "FlexKomSigStartValue" SG_ 949 VC_BU_FCW_CSO "0300000000000000h";
BA_ "FlexKomSigStartPos" SG_ 949 VC_BU_FCW_CSO 7;
BA_ "FlexKomSigName" SG_ 949 VC_BU_FCW_CSO "VehCfgCSM1_BuPkt";
BA_ "FlexKomSigLaenge" SG_ 949 VC_BU_FCW_CSO 64;
BA_ "FlexKomSID" SG_ 949 VC_BU_FCW_CSO 2008;
BA_ "FlexKomIsMotorola" SG_ 949 VC_BU_FCW_CSO 1;
BA_ "FlexKomComment" SG_ 949 VC_BU_FCW_CSO "Backup for veh config - customer settings menu 1 P";
BA_ "GenSigSNA" SG_ 949 VC_BU_FLSH_LMP_LK_CSO "0h";
BA_ "GenSigSendType" SG_ 949 VC_BU_FLSH_LMP_LK_CSO 1;
BA_ "FlexKomSigStartValue" SG_ 949 VC_BU_FLSH_LMP_LK_CSO "0300000000000000h";
BA_ "FlexKomSigStartPos" SG_ 949 VC_BU_FLSH_LMP_LK_CSO 7;
BA_ "FlexKomSigName" SG_ 949 VC_BU_FLSH_LMP_LK_CSO "VehCfgCSM1_BuPkt";
BA_ "FlexKomSigLaenge" SG_ 949 VC_BU_FLSH_LMP_LK_CSO 64;
BA_ "FlexKomSID" SG_ 949 VC_BU_FLSH_LMP_LK_CSO 2008;
BA_ "FlexKomIsMotorola" SG_ 949 VC_BU_FLSH_LMP_LK_CSO 1;
BA_ "FlexKomComment" SG_ 949 VC_BU_FLSH_LMP_LK_CSO "Backup for veh config - customer settings menu 1 P";
BA_ "GenSigSNA" SG_ 949 VC_BU_HL_DRP_CSO "0h";
BA_ "GenSigSendType" SG_ 949 VC_BU_HL_DRP_CSO 1;
BA_ "FlexKomSigStartValue" SG_ 949 VC_BU_HL_DRP_CSO "0300000000000000h";
BA_ "FlexKomSigStartPos" SG_ 949 VC_BU_HL_DRP_CSO 7;
BA_ "FlexKomSigName" SG_ 949 VC_BU_HL_DRP_CSO "VehCfgCSM1_BuPkt";
BA_ "FlexKomSigLaenge" SG_ 949 VC_BU_HL_DRP_CSO 64;
BA_ "FlexKomSID" SG_ 949 VC_BU_HL_DRP_CSO 2008;
BA_ "FlexKomIsMotorola" SG_ 949 VC_BU_HL_DRP_CSO 1;
BA_ "FlexKomComment" SG_ 949 VC_BU_HL_DRP_CSO "Backup for veh config - customer settings menu 1 P";
BA_ "GenSigSNA" SG_ 949 VC_BU_HL_OFF_DLY_CSO "0h";
BA_ "GenSigSendType" SG_ 949 VC_BU_HL_OFF_DLY_CSO 1;
BA_ "FlexKomSigStartValue" SG_ 949 VC_BU_HL_OFF_DLY_CSO "0300000000000000h";
BA_ "FlexKomSigStartPos" SG_ 949 VC_BU_HL_OFF_DLY_CSO 7;
BA_ "FlexKomSigName" SG_ 949 VC_BU_HL_OFF_DLY_CSO "VehCfgCSM1_BuPkt";
BA_ "FlexKomSigLaenge" SG_ 949 VC_BU_HL_OFF_DLY_CSO 64;
BA_ "FlexKomSID" SG_ 949 VC_BU_HL_OFF_DLY_CSO 2008;
BA_ "FlexKomIsMotorola" SG_ 949 VC_BU_HL_OFF_DLY_CSO 1;
BA_ "FlexKomComment" SG_ 949 VC_BU_HL_OFF_DLY_CSO "Backup for veh config - customer settings menu 1 P";
BA_ "GenSigSNA" SG_ 949 VC_BU_HL_WPR_CSO "0h";
BA_ "GenSigSendType" SG_ 949 VC_BU_HL_WPR_CSO 1;
BA_ "FlexKomSigStartValue" SG_ 949 VC_BU_HL_WPR_CSO "0300000000000000h";
BA_ "FlexKomSigStartPos" SG_ 949 VC_BU_HL_WPR_CSO 7;
BA_ "FlexKomSigName" SG_ 949 VC_BU_HL_WPR_CSO "VehCfgCSM1_BuPkt";
BA_ "FlexKomSigLaenge" SG_ 949 VC_BU_HL_WPR_CSO 64;
BA_ "FlexKomSID" SG_ 949 VC_BU_HL_WPR_CSO 2008;
BA_ "FlexKomIsMotorola" SG_ 949 VC_BU_HL_WPR_CSO 1;
BA_ "FlexKomComment" SG_ 949 VC_BU_HL_WPR_CSO "Backup for veh config - customer settings menu 1 P";
BA_ "GenSigSNA" SG_ 949 VC_BU_HRN_RMT_LK_CSO "0h";
BA_ "GenSigSendType" SG_ 949 VC_BU_HRN_RMT_LK_CSO 1;
BA_ "FlexKomSigStartValue" SG_ 949 VC_BU_HRN_RMT_LK_CSO "0300000000000000h";
BA_ "FlexKomSigStartPos" SG_ 949 VC_BU_HRN_RMT_LK_CSO 7;
BA_ "FlexKomSigName" SG_ 949 VC_BU_HRN_RMT_LK_CSO "VehCfgCSM1_BuPkt";
BA_ "FlexKomSigLaenge" SG_ 949 VC_BU_HRN_RMT_LK_CSO 64;
BA_ "FlexKomSID" SG_ 949 VC_BU_HRN_RMT_LK_CSO 2008;
BA_ "FlexKomIsMotorola" SG_ 949 VC_BU_HRN_RMT_LK_CSO 1;
BA_ "FlexKomComment" SG_ 949 VC_BU_HRN_RMT_LK_CSO "Backup for veh config - customer settings menu 1 P";
BA_ "GenSigSNA" SG_ 949 VC_BU_HRN_RMT_LWR_CSO "0h";
BA_ "GenSigSendType" SG_ 949 VC_BU_HRN_RMT_LWR_CSO 1;
BA_ "FlexKomSigStartValue" SG_ 949 VC_BU_HRN_RMT_LWR_CSO "0300000000000000h";
BA_ "FlexKomSigStartPos" SG_ 949 VC_BU_HRN_RMT_LWR_CSO 7;
BA_ "FlexKomSigName" SG_ 949 VC_BU_HRN_RMT_LWR_CSO "VehCfgCSM1_BuPkt";
BA_ "FlexKomSigLaenge" SG_ 949 VC_BU_HRN_RMT_LWR_CSO 64;
BA_ "FlexKomSID" SG_ 949 VC_BU_HRN_RMT_LWR_CSO 2008;
BA_ "FlexKomIsMotorola" SG_ 949 VC_BU_HRN_RMT_LWR_CSO 1;
BA_ "FlexKomComment" SG_ 949 VC_BU_HRN_RMT_LWR_CSO "Backup for veh config - customer settings menu 1 P";
BA_ "GenSigSNA" SG_ 949 VC_BU_HRN_RMT_ST_CSO "0h";
BA_ "GenSigSendType" SG_ 949 VC_BU_HRN_RMT_ST_CSO 1;
BA_ "FlexKomSigStartValue" SG_ 949 VC_BU_HRN_RMT_ST_CSO "0300000000000000h";
BA_ "FlexKomSigStartPos" SG_ 949 VC_BU_HRN_RMT_ST_CSO 7;
BA_ "FlexKomSigName" SG_ 949 VC_BU_HRN_RMT_ST_CSO "VehCfgCSM1_BuPkt";
BA_ "FlexKomSigLaenge" SG_ 949 VC_BU_HRN_RMT_ST_CSO 64;
BA_ "FlexKomSID" SG_ 949 VC_BU_HRN_RMT_ST_CSO 2008;
BA_ "FlexKomIsMotorola" SG_ 949 VC_BU_HRN_RMT_ST_CSO 1;
BA_ "FlexKomComment" SG_ 949 VC_BU_HRN_RMT_ST_CSO "Backup for veh config - customer settings menu 1 P";
BA_ "GenSigSNA" SG_ 949 VC_BU_HSA_CSO "0h";
BA_ "GenSigSendType" SG_ 949 VC_BU_HSA_CSO 1;
BA_ "FlexKomSigStartValue" SG_ 949 VC_BU_HSA_CSO "0300000000000000h";
BA_ "FlexKomSigStartPos" SG_ 949 VC_BU_HSA_CSO 7;
BA_ "FlexKomSigName" SG_ 949 VC_BU_HSA_CSO "VehCfgCSM1_BuPkt";
BA_ "FlexKomSigLaenge" SG_ 949 VC_BU_HSA_CSO 64;
BA_ "FlexKomSID" SG_ 949 VC_BU_HSA_CSO 2008;
BA_ "FlexKomIsMotorola" SG_ 949 VC_BU_HSA_CSO 1;
BA_ "FlexKomComment" SG_ 949 VC_BU_HSA_CSO "Backup for veh config - customer settings menu 1 P";
BA_ "GenSigSNA" SG_ 949 VC_BU_ILL_APPRCH_CSO "0h";
BA_ "GenSigSendType" SG_ 949 VC_BU_ILL_APPRCH_CSO 1;
BA_ "FlexKomSigStartValue" SG_ 949 VC_BU_ILL_APPRCH_CSO "0300000000000000h";
BA_ "FlexKomSigStartPos" SG_ 949 VC_BU_ILL_APPRCH_CSO 7;
BA_ "FlexKomSigName" SG_ 949 VC_BU_ILL_APPRCH_CSO "VehCfgCSM1_BuPkt";
BA_ "FlexKomSigLaenge" SG_ 949 VC_BU_ILL_APPRCH_CSO 64;
BA_ "FlexKomSID" SG_ 949 VC_BU_ILL_APPRCH_CSO 2008;
BA_ "FlexKomIsMotorola" SG_ 949 VC_BU_ILL_APPRCH_CSO 1;
BA_ "FlexKomComment" SG_ 949 VC_BU_ILL_APPRCH_CSO "Backup for veh config - customer settings menu 1 P";
BA_ "GenSigSNA" SG_ 949 VC_BU_LDW_TRQ_CSO "0h";
BA_ "GenSigSendType" SG_ 949 VC_BU_LDW_TRQ_CSO 1;
BA_ "FlexKomSigStartValue" SG_ 949 VC_BU_LDW_TRQ_CSO "0300000000000000h";
BA_ "FlexKomSigStartPos" SG_ 949 VC_BU_LDW_TRQ_CSO 7;
BA_ "FlexKomSigName" SG_ 949 VC_BU_LDW_TRQ_CSO "VehCfgCSM1_BuPkt";
BA_ "FlexKomSigLaenge" SG_ 949 VC_BU_LDW_TRQ_CSO 64;
BA_ "FlexKomSID" SG_ 949 VC_BU_LDW_TRQ_CSO 2008;
BA_ "FlexKomIsMotorola" SG_ 949 VC_BU_LDW_TRQ_CSO 1;
BA_ "FlexKomComment" SG_ 949 VC_BU_LDW_TRQ_CSO "Backup for veh config - customer settings menu 1 P";
BA_ "GenSigSNA" SG_ 949 VC_BU_LDW_WRN_CSO "0h";
BA_ "GenSigSendType" SG_ 949 VC_BU_LDW_WRN_CSO 1;
BA_ "FlexKomSigStartValue" SG_ 949 VC_BU_LDW_WRN_CSO "0300000000000000h";
BA_ "FlexKomSigStartPos" SG_ 949 VC_BU_LDW_WRN_CSO 7;
BA_ "FlexKomSigName" SG_ 949 VC_BU_LDW_WRN_CSO "VehCfgCSM1_BuPkt";
BA_ "FlexKomSigLaenge" SG_ 949 VC_BU_LDW_WRN_CSO 64;
BA_ "FlexKomSID" SG_ 949 VC_BU_LDW_WRN_CSO 2008;
BA_ "FlexKomIsMotorola" SG_ 949 VC_BU_LDW_WRN_CSO 1;
BA_ "FlexKomComment" SG_ 949 VC_BU_LDW_WRN_CSO "Backup for veh config - customer settings menu 1 P";
BA_ "GenSigSNA" SG_ 949 VC_BU_LGHT_RMT_LWR_CSO "0h";
BA_ "GenSigSendType" SG_ 949 VC_BU_LGHT_RMT_LWR_CSO 1;
BA_ "FlexKomSigStartValue" SG_ 949 VC_BU_LGHT_RMT_LWR_CSO "0300000000000000h";
BA_ "FlexKomSigStartPos" SG_ 949 VC_BU_LGHT_RMT_LWR_CSO 7;
BA_ "FlexKomSigName" SG_ 949 VC_BU_LGHT_RMT_LWR_CSO "VehCfgCSM1_BuPkt";
BA_ "FlexKomSigLaenge" SG_ 949 VC_BU_LGHT_RMT_LWR_CSO 64;
BA_ "FlexKomSID" SG_ 949 VC_BU_LGHT_RMT_LWR_CSO 2008;
BA_ "FlexKomIsMotorola" SG_ 949 VC_BU_LGHT_RMT_LWR_CSO 1;
BA_ "FlexKomComment" SG_ 949 VC_BU_LGHT_RMT_LWR_CSO "Backup for veh config - customer settings menu 1 P";
BA_ "GenSigSNA" SG_ 949 VC_BU_NAV_TRN_CSO "0h";
BA_ "GenSigSendType" SG_ 949 VC_BU_NAV_TRN_CSO 1;
BA_ "FlexKomSigStartValue" SG_ 949 VC_BU_NAV_TRN_CSO "0300000000000000h";
BA_ "FlexKomSigStartPos" SG_ 949 VC_BU_NAV_TRN_CSO 7;
BA_ "FlexKomSigName" SG_ 949 VC_BU_NAV_TRN_CSO "VehCfgCSM1_BuPkt";
BA_ "FlexKomSigLaenge" SG_ 949 VC_BU_NAV_TRN_CSO 64;
BA_ "FlexKomSID" SG_ 949 VC_BU_NAV_TRN_CSO 2008;
BA_ "FlexKomIsMotorola" SG_ 949 VC_BU_NAV_TRN_CSO 1;
BA_ "FlexKomComment" SG_ 949 VC_BU_NAV_TRN_CSO "Backup for veh config - customer settings menu 1 P";
BA_ "GenSigSNA" SG_ 949 VC_BU_PER_SHFT_ENBL_CSO "0h";
BA_ "GenSigSendType" SG_ 949 VC_BU_PER_SHFT_ENBL_CSO 1;
BA_ "FlexKomSigStartValue" SG_ 949 VC_BU_PER_SHFT_ENBL_CSO "0300000000000000h";
BA_ "FlexKomSigStartPos" SG_ 949 VC_BU_PER_SHFT_ENBL_CSO 7;
BA_ "FlexKomSigName" SG_ 949 VC_BU_PER_SHFT_ENBL_CSO "VehCfgCSM1_BuPkt";
BA_ "FlexKomSigLaenge" SG_ 949 VC_BU_PER_SHFT_ENBL_CSO 64;
BA_ "FlexKomSID" SG_ 949 VC_BU_PER_SHFT_ENBL_CSO 2008;
BA_ "FlexKomIsMotorola" SG_ 949 VC_BU_PER_SHFT_ENBL_CSO 1;
BA_ "FlexKomComment" SG_ 949 VC_BU_PER_SHFT_ENBL_CSO "Backup for veh config - customer settings menu 1 P";
BA_ "GenSigSNA" SG_ 949 VC_BU_PER_SHFT_RPM_CSO "0h";
BA_ "GenSigSendType" SG_ 949 VC_BU_PER_SHFT_RPM_CSO 1;
BA_ "FlexKomSigStartValue" SG_ 949 VC_BU_PER_SHFT_RPM_CSO "0300000000000000h";
BA_ "FlexKomSigStartPos" SG_ 949 VC_BU_PER_SHFT_RPM_CSO 7;
BA_ "FlexKomSigName" SG_ 949 VC_BU_PER_SHFT_RPM_CSO "VehCfgCSM1_BuPkt";
BA_ "FlexKomSigLaenge" SG_ 949 VC_BU_PER_SHFT_RPM_CSO 64;
BA_ "FlexKomSID" SG_ 949 VC_BU_PER_SHFT_RPM_CSO 2008;
BA_ "FlexKomIsMotorola" SG_ 949 VC_BU_PER_SHFT_RPM_CSO 1;
BA_ "FlexKomComment" SG_ 949 VC_BU_PER_SHFT_RPM_CSO "Backup for veh config - customer settings menu 1 P";
BA_ "GenSigSNA" SG_ 949 VC_BU_PE_CSO "0h";
BA_ "GenSigSendType" SG_ 949 VC_BU_PE_CSO 1;
BA_ "FlexKomSigStartValue" SG_ 949 VC_BU_PE_CSO "0300000000000000h";
BA_ "FlexKomSigStartPos" SG_ 949 VC_BU_PE_CSO 7;
BA_ "FlexKomSigName" SG_ 949 VC_BU_PE_CSO "VehCfgCSM1_BuPkt";
BA_ "FlexKomSigLaenge" SG_ 949 VC_BU_PE_CSO 64;
BA_ "FlexKomSID" SG_ 949 VC_BU_PE_CSO 2008;
BA_ "FlexKomIsMotorola" SG_ 949 VC_BU_PE_CSO 1;
BA_ "FlexKomComment" SG_ 949 VC_BU_PE_CSO "Backup for veh config - customer settings menu 1 P";
BA_ "GenSigSNA" SG_ 949 VC_BU_PLG_CHM_CSO "0h";
BA_ "GenSigSendType" SG_ 949 VC_BU_PLG_CHM_CSO 1;
BA_ "FlexKomSigStartValue" SG_ 949 VC_BU_PLG_CHM_CSO "0300000000000000h";
BA_ "FlexKomSigStartPos" SG_ 949 VC_BU_PLG_CHM_CSO 7;
BA_ "FlexKomSigName" SG_ 949 VC_BU_PLG_CHM_CSO "VehCfgCSM1_BuPkt";
BA_ "FlexKomSigLaenge" SG_ 949 VC_BU_PLG_CHM_CSO 64;
BA_ "FlexKomSID" SG_ 949 VC_BU_PLG_CHM_CSO 2008;
BA_ "FlexKomIsMotorola" SG_ 949 VC_BU_PLG_CHM_CSO 1;
BA_ "FlexKomComment" SG_ 949 VC_BU_PLG_CHM_CSO "Backup for veh config - customer settings menu 1 P";
BA_ "GenSigSNA" SG_ 949 VC_BU_POLICE_PE_CSO "0h";
BA_ "GenSigSendType" SG_ 949 VC_BU_POLICE_PE_CSO 1;
BA_ "FlexKomSigStartValue" SG_ 949 VC_BU_POLICE_PE_CSO "0300000000000000h";
BA_ "FlexKomSigStartPos" SG_ 949 VC_BU_POLICE_PE_CSO 7;
BA_ "FlexKomSigName" SG_ 949 VC_BU_POLICE_PE_CSO "VehCfgCSM1_BuPkt";
BA_ "FlexKomSigLaenge" SG_ 949 VC_BU_POLICE_PE_CSO 64;
BA_ "FlexKomSID" SG_ 949 VC_BU_POLICE_PE_CSO 2008;
BA_ "FlexKomIsMotorola" SG_ 949 VC_BU_POLICE_PE_CSO 1;
BA_ "FlexKomComment" SG_ 949 VC_BU_POLICE_PE_CSO "Backup for veh config - customer settings menu 1 P";
BA_ "GenSigSNA" SG_ 949 VC_BU_POWER_CSO "0h";
BA_ "GenSigSendType" SG_ 949 VC_BU_POWER_CSO 1;
BA_ "FlexKomSigStartValue" SG_ 949 VC_BU_POWER_CSO "0300000000000000h";
BA_ "FlexKomSigStartPos" SG_ 949 VC_BU_POWER_CSO 7;
BA_ "FlexKomSigName" SG_ 949 VC_BU_POWER_CSO "VehCfgCSM1_BuPkt";
BA_ "FlexKomSigLaenge" SG_ 949 VC_BU_POWER_CSO 64;
BA_ "FlexKomSID" SG_ 949 VC_BU_POWER_CSO 2008;
BA_ "FlexKomIsMotorola" SG_ 949 VC_BU_POWER_CSO 1;
BA_ "FlexKomComment" SG_ 949 VC_BU_POWER_CSO "Backup for veh config - customer settings menu 1 P";
BA_ "GenSigSNA" SG_ 949 VC_BU_PRESSURE_CSO "0h";
BA_ "GenSigSendType" SG_ 949 VC_BU_PRESSURE_CSO 1;
BA_ "FlexKomSigStartValue" SG_ 949 VC_BU_PRESSURE_CSO "0300000000000000h";
BA_ "FlexKomSigStartPos" SG_ 949 VC_BU_PRESSURE_CSO 7;
BA_ "FlexKomSigName" SG_ 949 VC_BU_PRESSURE_CSO "VehCfgCSM1_BuPkt";
BA_ "FlexKomSigLaenge" SG_ 949 VC_BU_PRESSURE_CSO 64;
BA_ "FlexKomSID" SG_ 949 VC_BU_PRESSURE_CSO 2008;
BA_ "FlexKomIsMotorola" SG_ 949 VC_BU_PRESSURE_CSO 1;
BA_ "FlexKomComment" SG_ 949 VC_BU_PRESSURE_CSO "Backup for veh config - customer settings menu 1 P";
BA_ "GenSigSNA" SG_ 949 VC_BU_PRK_AST_BRK_CSO "0h";
BA_ "GenSigSendType" SG_ 949 VC_BU_PRK_AST_BRK_CSO 1;
BA_ "FlexKomSigStartValue" SG_ 949 VC_BU_PRK_AST_BRK_CSO "0300000000000000h";
BA_ "FlexKomSigStartPos" SG_ 949 VC_BU_PRK_AST_BRK_CSO 7;
BA_ "FlexKomSigName" SG_ 949 VC_BU_PRK_AST_BRK_CSO "VehCfgCSM1_BuPkt";
BA_ "FlexKomSigLaenge" SG_ 949 VC_BU_PRK_AST_BRK_CSO 64;
BA_ "FlexKomSID" SG_ 949 VC_BU_PRK_AST_BRK_CSO 2008;
BA_ "FlexKomIsMotorola" SG_ 949 VC_BU_PRK_AST_BRK_CSO 1;
BA_ "FlexKomComment" SG_ 949 VC_BU_PRK_AST_BRK_CSO "Backup for veh config - customer settings menu 1 P";
BA_ "GenSigSNA" SG_ 949 VC_BU_PRK_AST_CSO "0h";
BA_ "GenSigSendType" SG_ 949 VC_BU_PRK_AST_CSO 1;
BA_ "FlexKomSigStartValue" SG_ 949 VC_BU_PRK_AST_CSO "0300000000000000h";
BA_ "FlexKomSigStartPos" SG_ 949 VC_BU_PRK_AST_CSO 7;
BA_ "FlexKomSigName" SG_ 949 VC_BU_PRK_AST_CSO "VehCfgCSM1_BuPkt";
BA_ "FlexKomSigLaenge" SG_ 949 VC_BU_PRK_AST_CSO 64;
BA_ "FlexKomSID" SG_ 949 VC_BU_PRK_AST_CSO 2008;
BA_ "FlexKomIsMotorola" SG_ 949 VC_BU_PRK_AST_CSO 1;
BA_ "FlexKomComment" SG_ 949 VC_BU_PRK_AST_CSO "Backup for veh config - customer settings menu 1 P";
BA_ "GenSigSNA" SG_ 949 VC_BU_PRK_FT_VOL_CSO "0h";
BA_ "GenSigSendType" SG_ 949 VC_BU_PRK_FT_VOL_CSO 1;
BA_ "FlexKomSigStartValue" SG_ 949 VC_BU_PRK_FT_VOL_CSO "0300000000000000h";
BA_ "FlexKomSigStartPos" SG_ 949 VC_BU_PRK_FT_VOL_CSO 7;
BA_ "FlexKomSigName" SG_ 949 VC_BU_PRK_FT_VOL_CSO "VehCfgCSM1_BuPkt";
BA_ "FlexKomSigLaenge" SG_ 949 VC_BU_PRK_FT_VOL_CSO 64;
BA_ "FlexKomSID" SG_ 949 VC_BU_PRK_FT_VOL_CSO 2008;
BA_ "FlexKomIsMotorola" SG_ 949 VC_BU_PRK_FT_VOL_CSO 1;
BA_ "FlexKomComment" SG_ 949 VC_BU_PRK_FT_VOL_CSO "Backup for veh config - customer settings menu 1 P";
BA_ "GenSigSNA" SG_ 949 VC_BU_PRK_RR_VOL_CSO "0h";
BA_ "GenSigSendType" SG_ 949 VC_BU_PRK_RR_VOL_CSO 1;
BA_ "FlexKomSigStartValue" SG_ 949 VC_BU_PRK_RR_VOL_CSO "0300000000000000h";
BA_ "FlexKomSigStartPos" SG_ 949 VC_BU_PRK_RR_VOL_CSO 7;
BA_ "FlexKomSigName" SG_ 949 VC_BU_PRK_RR_VOL_CSO "VehCfgCSM1_BuPkt";
BA_ "FlexKomSigLaenge" SG_ 949 VC_BU_PRK_RR_VOL_CSO 64;
BA_ "FlexKomSID" SG_ 949 VC_BU_PRK_RR_VOL_CSO 2008;
BA_ "FlexKomIsMotorola" SG_ 949 VC_BU_PRK_RR_VOL_CSO 1;
BA_ "FlexKomComment" SG_ 949 VC_BU_PRK_RR_VOL_CSO "Backup for veh config - customer settings menu 1 P";
BA_ "GenSigSNA" SG_ 949 VC_BU_PTO_CSO "0h";
BA_ "GenSigSendType" SG_ 949 VC_BU_PTO_CSO 1;
BA_ "FlexKomSigStartValue" SG_ 949 VC_BU_PTO_CSO "0300000000000000h";
BA_ "FlexKomSigStartPos" SG_ 949 VC_BU_PTO_CSO 7;
BA_ "FlexKomSigName" SG_ 949 VC_BU_PTO_CSO "VehCfgCSM1_BuPkt";
BA_ "FlexKomSigLaenge" SG_ 949 VC_BU_PTO_CSO 64;
BA_ "FlexKomSID" SG_ 949 VC_BU_PTO_CSO 2008;
BA_ "FlexKomIsMotorola" SG_ 949 VC_BU_PTO_CSO 1;
BA_ "FlexKomComment" SG_ 949 VC_BU_PTO_CSO "Backup for veh config - customer settings menu 1 P";
BA_ "GenSigSNA" SG_ 949 VC_BU_RAIN_WPR_CSO "0h";
BA_ "GenSigSendType" SG_ 949 VC_BU_RAIN_WPR_CSO 1;
BA_ "FlexKomSigStartValue" SG_ 949 VC_BU_RAIN_WPR_CSO "0300000000000000h";
BA_ "FlexKomSigStartPos" SG_ 949 VC_BU_RAIN_WPR_CSO 7;
BA_ "FlexKomSigName" SG_ 949 VC_BU_RAIN_WPR_CSO "VehCfgCSM1_BuPkt";
BA_ "FlexKomSigLaenge" SG_ 949 VC_BU_RAIN_WPR_CSO 64;
BA_ "FlexKomSID" SG_ 949 VC_BU_RAIN_WPR_CSO 2008;
BA_ "FlexKomIsMotorola" SG_ 949 VC_BU_RAIN_WPR_CSO 1;
BA_ "FlexKomComment" SG_ 949 VC_BU_RAIN_WPR_CSO "Backup for veh config - customer settings menu 1 P";
BA_ "GenSigSNA" SG_ 949 VC_BU_REAR_CMRA_CSO "0h";
BA_ "GenSigSendType" SG_ 949 VC_BU_REAR_CMRA_CSO 1;
BA_ "FlexKomSigStartValue" SG_ 949 VC_BU_REAR_CMRA_CSO "0300000000000000h";
BA_ "FlexKomSigStartPos" SG_ 949 VC_BU_REAR_CMRA_CSO 7;
BA_ "FlexKomSigName" SG_ 949 VC_BU_REAR_CMRA_CSO "VehCfgCSM1_BuPkt";
BA_ "FlexKomSigLaenge" SG_ 949 VC_BU_REAR_CMRA_CSO 64;
BA_ "FlexKomSID" SG_ 949 VC_BU_REAR_CMRA_CSO 2008;
BA_ "FlexKomIsMotorola" SG_ 949 VC_BU_REAR_CMRA_CSO 1;
BA_ "FlexKomComment" SG_ 949 VC_BU_REAR_CMRA_CSO "Backup for veh config - customer settings menu 1 P";
BA_ "GenSigSNA" SG_ 949 VC_BU_UNIT_SET_CSO "0h";
BA_ "GenSigSendType" SG_ 949 VC_BU_UNIT_SET_CSO 1;
BA_ "FlexKomSigStartValue" SG_ 949 VC_BU_UNIT_SET_CSO "0300000000000000h";
BA_ "FlexKomSigStartPos" SG_ 949 VC_BU_UNIT_SET_CSO 7;
BA_ "FlexKomSigName" SG_ 949 VC_BU_UNIT_SET_CSO "VehCfgCSM1_BuPkt";
BA_ "FlexKomSigLaenge" SG_ 949 VC_BU_UNIT_SET_CSO 64;
BA_ "FlexKomSID" SG_ 949 VC_BU_UNIT_SET_CSO 2008;
BA_ "FlexKomIsMotorola" SG_ 949 VC_BU_UNIT_SET_CSO 1;
BA_ "FlexKomComment" SG_ 949 VC_BU_UNIT_SET_CSO "Backup for veh config - customer settings menu 1 P";
BA_ "GenSigStartValue" SG_ 949 VC_BU_VehCfgCSO1_Stat 3;
BA_ "GenSigSNA" SG_ 949 VC_BU_VehCfgCSO1_Stat "3h";
BA_ "GenSigSendType" SG_ 949 VC_BU_VehCfgCSO1_Stat 1;
BA_ "FlexKomSigStartValue" SG_ 949 VC_BU_VehCfgCSO1_Stat "0300000000000000h";
BA_ "FlexKomSigStartPos" SG_ 949 VC_BU_VehCfgCSO1_Stat 7;
BA_ "FlexKomSigName" SG_ 949 VC_BU_VehCfgCSO1_Stat "VehCfgCSM1_BuPkt";
BA_ "FlexKomSigLaenge" SG_ 949 VC_BU_VehCfgCSO1_Stat 64;
BA_ "FlexKomSID" SG_ 949 VC_BU_VehCfgCSO1_Stat 2008;
BA_ "FlexKomIsMotorola" SG_ 949 VC_BU_VehCfgCSO1_Stat 1;
BA_ "FlexKomComment" SG_ 949 VC_BU_VehCfgCSO1_Stat "Backup for veh config - customer settings menu 1 P";
VAL_ 1099 VC_BU_AmbTempLct 0 "CBC" 1 "DCM" 3 "SNA" ;
VAL_ 1099 VC_BU_Strng_Rt_0 255 "SNA" ;
VAL_ 1099 VC_BU_Strng_Rt_pls1 255 "SNA" ;
VAL_ 1099 VC_BU_Strng_Rt_pls2 255 "SNA" ;
VAL_ 1099 VC_BU_Strng_Rt_pls3 255 "SNA" ;
VAL_ 1099 VC_BU_Strng_Rt_pls4 255 "SNA" ;
VAL_ 1099 VC_BU_Strng_Rt_pls5 255 "SNA" ;
VAL_ 1099 VC_BU_VehCfg5_Stat 0 "NA" 1 "PROGAMMED" 2 "NA1" 3 "SNA" ;
VAL_ 1101 VC_BU_AnlgDrSnsr 0 "NONE" 1 "DRV" 2 "FT" 3 "ALL" ;
VAL_ 1101 VC_BU_BrkTyp 0 "SMALL" 1 "PB" 2 "CB" 3 "MB" 7 "SNA" ;
VAL_ 1101 VC_BU_Strng_Rt_Mns1 255 "SNA" ;
VAL_ 1101 VC_BU_Strng_Rt_Mns2 255 "SNA" ;
VAL_ 1101 VC_BU_Strng_Rt_Mns3 255 "SNA" ;
VAL_ 1101 VC_BU_Strng_Rt_Mns4 255 "SNA" ;
VAL_ 1101 VC_BU_Strng_Rt_Mns5 255 "SNA" ;
VAL_ 1101 VC_BU_TireCircumfFT 65535 "SNA" ;
VAL_ 1101 VC_BU_VehCfg6_Stat 0 "NA" 1 "PROGAMMED" 2 "NA1" 3 "SNA" ;
VAL_ 898 VC_BU_ACC_Type 0 "NONE" 1 "ACC" 2 "STOP" 3 "GO" ;
VAL_ 898 VC_BU_AGSprsnt 0 "Not_Present" 1 "Present" ;
VAL_ 898 VC_BU_AS_ERS 0 "NONE" 1 "ERS" 2 "AS" 3 "SNA" ;
VAL_ 898 VC_BU_AxleLockerPrsnt 0 "NONE" 1 "REAR" 2 "FTRR" ;
VAL_ 898 VC_BU_Brake_Type 0 "None" 1 "1" 2 "2" 3 "3" 4 "4" 5 "5" 6 "6" 7 "7" 8 "8" 9 "9" 10 "10" 11 "11" 12 "12" 13 "13" 14 "14" 15 "15" ;
VAL_ 898 VC_BU_GlareFree_Prsnt 0 "Not_Present" 1 "Present" ;
VAL_ 898 VC_BU_HybridType 0 "NONE" 1 "BEV" 2 "HEV" 3 "PHEV" 4 "BSG48" ;
VAL_ 898 VC_BU_MOC_Type 0 "NO_MOC" 1 "MOC_BREMBO" 2 "MOC_CONTI" ;
VAL_ 898 VC_BU_PBTyp 0 "MECH" 1 "EPB_MOC" 2 "EPB_CP" 3 "IMOC" 4 "ICP" 7 "SNA" ;
VAL_ 898 VC_BU_Suspension_Type 0 "None" 1 "1" 2 "2" 3 "3" 4 "4" 5 "5" 6 "6" 7 "7" 8 "8" 9 "9" 10 "10" 11 "11" 12 "12" 13 "13" 14 "14" 15 "15" ;
VAL_ 898 VC_BU_TPMS_Configuration 0 "NHTSA" 1 "NAFTA" 2 "ECE" 3 "OTHER" 4 "CHINA" 7 "SNA" ;
VAL_ 898 VC_BU_Temp_Display_Resolution 0 "One_Degree_C" 1 "Half_Degree_C" ;
VAL_ 898 VC_BU_TransType 0 "NP" 1 "SI_EVT_Hybrid_Trans" 2 "MTA" 3 "c40TES" 4 "Aisin_LD" 5 "W5A580" 6 "c62TE" 7 "c65RFE" 8 "c66RFE" 9 "c68RFE" 10 "AISIN_HD" 11 "DDCT_C635" 12 "HPT_6F24" 13 "ZF_8Spd" 14 "ZF_9Spd" 63 "SNA" ;
VAL_ 898 VC_BU_VehCfg7_Stat 0 "NA" 1 "PROGAMMED" 2 "NA1" 3 "SNA" ;
VAL_ 907 VC_BU_AVAC_PRSNT 0 "Not_Present" 1 "Present" ;
VAL_ 907 VC_BU_BEAM_SHAPING_PRSNT 0 "Not_Present" 1 "Present" ;
VAL_ 907 VC_BU_DBL_PRSNT 0 "Not_Present" 1 "Present" ;
VAL_ 907 VC_BU_FADPrsnt 0 "Not_Present" 1 "Present" ;
VAL_ 907 VC_BU_Increasing_Speed_Constant 0 "Increasing_0" 1 "Increasing_1" 2 "Increasing_2" 3 "Increasing_3" 4 "Increasing_4" 5 "Increasing_5" 6 "Increasing_6" 7 "Increasing_7" ;
VAL_ 907 VC_BU_PEB_PRSNT 0 "Not_Present" 1 "Present" ;
VAL_ 907 VC_BU_PPPAHardBtn 0 "Not_Present" 1 "Present" ;
VAL_ 907 VC_BU_Power_Outlet_Type 0 "No_Inverter" 1 "230V_Auxiliary_Power_Outlet" 2 "115V_Auxiliary_Power_Outlet" 3 "Reserved" ;
VAL_ 907 VC_BU_SBL_FBL_CORNERING_PRSNT 0 "Not_Present" 1 "SBL_FBL_Present" 2 "Cornering_Present" ;
VAL_ 907 VC_BU_Speedometer_Tolerance 0 "Tolerance_0" 1 "Tolerance_1" 2 "Tolerance_2" 3 "Tolerance_3" 4 "Tolerance_4" 5 "Tolerance_5" 6 "Tolerance_6" 7 "Tolerance_7" 8 "Tolerance_8" 9 "Tolerance_9" 10 "Tolerance_10" 11 "Tolerance_Neg1" 12 "Tolerance_Neg2" 13 "Tolerance_Neg3" 14 "Tolerance_Neg4" 15 "Tolerance_Neg5" ;
VAL_ 907 VC_BU_Steering_Cfactor 0 "TYPE_1" 1 "TYPE_2" 2 "TYPE_3" 3 "TYPE_4" ;
VAL_ 907 VC_BU_TACHO_TYPE 0 "DISABLED" 1 "TYP_1" 2 "TYP_2" 3 "TYP_3" ;
VAL_ 907 VC_BU_VP_Level 0 "None" 1 "LTM" 2 "ETM" ;
VAL_ 907 VC_BU_VehCfg8_Stat 0 "NA" 1 "PROGAMMED" 2 "NA1" 3 "SNA" ;
VAL_ 907 VC_BU_WHL_BASE_LENGTH 0 "Not_Used" 1 "Length_1" 2 "Length_2" 3 "Length_3" 4 "Length_4" 5 "Length_5" 6 "Length_6" 7 "Length_7" 8 "Length_8" 9 "Length_9" 10 "Length_10" 11 "Length_11" 12 "Length_12" 13 "Length_13" 14 "Length_14" 15 "Length_15" ;
VAL_ 947 VC_AUX_SWS_CSO 0 "Absent" 1 "SWITCH_1_4" 2 "SWITCH_2_5" 3 "SWITCH_3_6" ;
VAL_ 947 VC_CMRA_GRDLNS_CSO 0 "Absent" 1 "STATIC" 2 "DYNAMIC" 3 "STATIC_DYNAMIC" ;
VAL_ 947 VC_DCS_CSO 0 "Absent" 1 "Option_1_2" 2 "Option_2_3" ;
VAL_ 947 VC_FCW_CSO 0 "Absent" 1 "Option_1_2" 2 "Option_2_3" ;
VAL_ 947 VC_HRN_RMT_LK_CSO 0 "Absent" 1 "Option_1_2" 2 "Option_2_3" ;
VAL_ 947 VC_PRK_AST_CSO 0 "Absent" 1 "Option_1_2" 2 "Option_2_3" ;
VAL_ 947 VC_VehCfgCSO1_Stat 0 "NA" 1 "PROGAMMED" 2 "REQUEST_DATA" 3 "SNA" ;
VAL_ 949 VC_BU_AUX_SWS_CSO 0 "Absent" 1 "SWITCH_1_4" 2 "SWITCH_2_5" 3 "SWITCH_3_6" ;
VAL_ 949 VC_BU_CMRA_GRDLNS_CSO 0 "Absent" 1 "STATIC" 2 "DYNAMIC" 3 "STATIC_DYNAMIC" ;
VAL_ 949 VC_BU_DCS_CSO 0 "Absent" 1 "Option_1_2" 2 "Option_2_3" ;
VAL_ 949 VC_BU_FCW_CSO 0 "Absent" 1 "Option_1_2" 2 "Option_2_3" ;
VAL_ 949 VC_BU_HRN_RMT_LK_CSO 0 "Absent" 1 "Option_1_2" 2 "Option_2_3" ;
VAL_ 949 VC_BU_PRK_AST_CSO 0 "Absent" 1 "Option_1_2" 2 "Option_2_3" ;
VAL_ 949 VC_BU_VehCfgCSO1_Stat 0 "NA" 1 "PROGAMMED" 2 "REQUEST_DATA" 3 "SNA" ;
